VERSION "2021.24.4"

NS_ :

BS_:

BU_: VEH CH Receiver X

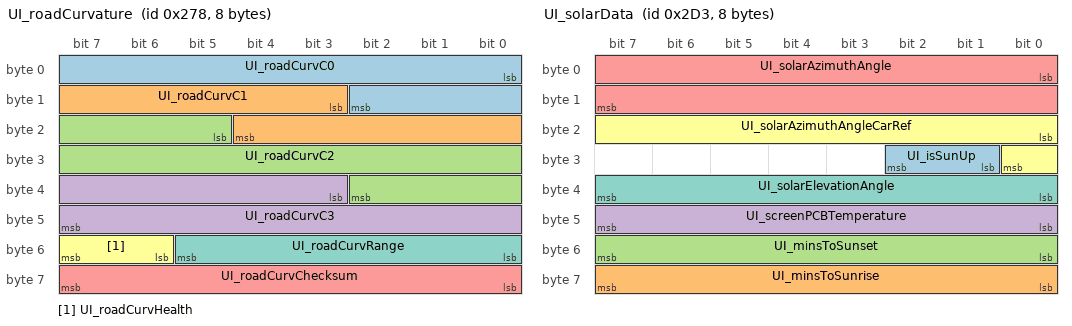
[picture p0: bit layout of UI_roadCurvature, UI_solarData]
BO_ 632 UI_roadCurvature: 8 VEH
 SG_ UI_roadCurvC0: 0|11@1- (0.02,0) [0|0] "m" X
 SG_ UI_roadCurvC1: 11|10@1- (0.00075,0) [0|0] "1" X
 SG_ UI_roadCurvC2: 21|14@1- (7.5e-06,0) [0|0] "1/m" X
 SG_ UI_roadCurvC3: 35|13@1- (3e-08,0) [0|0] "1/m2" X
 SG_ UI_roadCurvChecksum: 56|8@1+ (1,0) [0|0] "" X
 SG_ UI_roadCurvHealth: 54|2@1+ (1,0) [0|0] "" X
 SG_ UI_roadCurvRange: 48|6@1+ (4,0) [0|0] "m" X

BO_ 723 UI_solarData: 8 VEH
 SG_ UI_isSunUp: 25|2@1+ (1,0) [0|0] "" X
 SG_ UI_minsToSunrise: 56|8@1+ (10,0) [0|0] "min" X
 SG_ UI_minsToSunset: 48|8@1+ (10,0) [0|0] "min" X
 SG_ UI_screenPCBTemperature: 40|8@1- (0.5,40) [0|0] "degC" X
 SG_ UI_solarAzimuthAngle: 0|16@1- (1,0) [0|0] "degrees" X
 SG_ UI_solarAzimuthAngleCarRef: 16|9@1- (1,0) [0|0] "degrees" X
 SG_ UI_solarElevationAngle: 32|8@1- (1,0) [0|0] "degrees" X

BO_ 851 UI_status: 8 VehicleBus
 SG_ UI_touchActive : 0|1@1+ (1,0) [0|1] ""  VehicleBus
 SG_ UI_audioActive : 1|1@1+ (1,0) [0|1] ""  VehicleBus
 SG_ UI_bluetoothActive : 2|1@1+ (1,0) [0|1] ""  VehicleBus
 SG_ UI_cellActive : 3|1@1+ (1,0) [0|1] ""  VehicleBus
 SG_ UI_displayReady : 4|1@1+ (1,0) [0|1] ""  VehicleBus
 SG_ UI_displayOn : 5|1@1+ (1,0) [0|1] ""  VehicleBus
 SG_ UI_wifiActive : 6|1@1+ (1,0) [0|1] ""  VehicleBus
 SG_ UI_wifiConnected : 7|1@1+ (1,0) [0|1] ""  VehicleBus
 SG_ UI_systemActive : 8|1@1+ (1,0) [0|1] ""  VehicleBus
 SG_ UI_readyForDrive : 9|1@1+ (1,0) [0|1] ""  VehicleBus
 SG_ UI_cellConnected : 10|1@1+ (1,0) [0|1] ""  VehicleBus
 SG_ UI_vpnActive : 11|1@1+ (1,0) [0|1] ""  VehicleBus
 SG_ UI_autopilotTrial : 12|2@1+ (1,0) [0|3] ""  VehicleBus
 SG_ UI_factoryReset : 14|2@1+ (1,0) [0|3] ""  VehicleBus
 SG_ UI_gpsActive : 16|1@1+ (1,0) [0|1] ""  VehicleBus
 SG_ UI_screenshotActive : 17|1@1+ (1,0) [0|1] ""  VehicleBus
 SG_ UI_radioActive : 18|1@1+ (1,0) [0|1] ""  VehicleBus
 SG_ UI_cellNetworkTechnology : 19|4@1+ (1,0) [0|15] ""  VehicleBus
 SG_ UI_cellReceiverPower : 24|8@1+ (1,-128) [-128|127] "dB"  VehicleBus
 SG_ UI_falseTouchCounter : 32|8@1+ (1,0) [0|255] "1"  VehicleBus
 SG_ UI_developmentCar : 40|1@1+ (1,0) [0|1] ""  VehicleBus
 SG_ UI_cameraActive : 41|1@1+ (1,0) [0|1] ""  VehicleBus
 SG_ UI_cellSignalBars : 42|3@1+ (1,0) [0|7] ""  VehicleBus
 SG_ UI_trailerModeTelltale : 45|2@1+ (1,0) [0|3] ""  VehicleBus
 SG_ UI_pcbTemperature : 48|8@1- (1,40) [-87|167] "degC"  VehicleBus
 SG_ UI_cpuTemperature : 56|8@1- (1,40) [-87|167] "degC"  VehicleBus

BO_ 991 UI_status2: 8 Vector__XXX
 SG_ UI_connectivityStandbyActive : 63|1@1+ (1,0) [0|0] "" Vector__XXX
 SG_ UI_sapClients : 62|1@1+ (1,0) [0|0] "" Vector__XXX
 SG_ UI_sapActive : 61|1@1+ (1,0) [0|0] "" Vector__XXX
 SG_ UI_wakeOnIPActive : 60|1@1+ (1,0) [0|0] "" Vector__XXX
 SG_ UI_sentryModeCameraDetection : 59|1@1+ (1,0) [0|0] "" Vector__XXX
 SG_ UI_fullScreenMode : 58|1@1+ (1,0) [0|0] "" Vector__XXX
 SG_ UI_summonDeviceIndex : 56|2@1+ (1,0) [0|0] "" Vector__XXX
 SG_ UI_selfParkState : 48|8@1+ (1,0) [0|0] "" Vector__XXX
 SG_ UI_sohHealthStatus : 46|2@1+ (1,0) [0|0] "" Vector__XXX
 SG_ UI_wifiBtModuleType : 43|3@1+ (1,0) [0|0] "" Vector__XXX
 SG_ UI_autoshiftDRState : 40|3@1+ (1,0) [0|0] "" Vector__XXX
 SG_ UI_phoneLeftInCabin : 39|1@1+ (1,0) [0|0] "" Vector__XXX
 SG_ UI_mobileAppConnected : 38|1@1+ (1,0) [0|0] "" Vector__XXX
 SG_ UI_autopilotSentryRequest : 37|1@1+ (1,0) [0|0] "" Vector__XXX
 SG_ UI_sentryModeState : 34|3@1+ (1,0) [0|0] "" Vector__XXX
 SG_ UI_linkState : 32|2@1+ (1,0) [0|0] "" Vector__XXX
 SG_ UI_activeTouchPoints : 24|8@1+ (1,0) [0|0] "" Vector__XXX
 SG_ UI_userActivity : 23|1@1+ (1,0) [0|0] "" Vector__XXX
 SG_ UI_displayInDarkMode : 22|1@1+ (1,0) [0|0] "" Vector__XXX
 SG_ UI_locatedAtFavorite : 21|1@1+ (1,0) [0|0] "" Vector__XXX
 SG_ UI_locatedAtWork : 20|1@1+ (1,0) [0|0] "" Vector__XXX
 SG_ UI_locatedAtHome : 19|1@1+ (1,0) [0|0] "" Vector__XXX
 SG_ UI_validDeviceForEUSummon : 18|1@1+ (1,0) [0|0] "" Vector__XXX
 SG_ UI_touchDetected : 17|1@1+ (1,0) [0|0] "" Vector__XXX
 SG_ UI_userRequestSnapshot : 16|1@1+ (1,0) [0|0] "" Vector__XXX
 SG_ UI_mobileAppStepCount : 0|16@1+ (1,0) [0|0] "" Vector__XXX

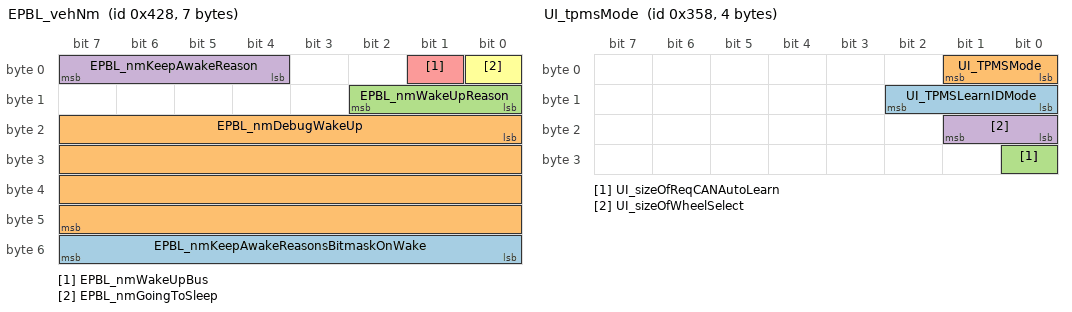
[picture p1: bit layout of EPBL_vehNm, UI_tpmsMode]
BO_ 1064 EPBL_vehNm: 7 Vector__XXX
 SG_ EPBL_nmKeepAwakeReasonsBitmaskOnWake : 48|8@1+ (1,0) [0|0] "" Vector__XXX
 SG_ EPBL_nmDebugWakeUp : 16|32@1+ (1,0) [0|0] "" Vector__XXX
 SG_ EPBL_nmWakeUpReason : 8|3@1+ (1,0) [0|0] "" Vector__XXX
 SG_ EPBL_nmKeepAwakeReason : 4|4@1+ (1,0) [0|0] "" Vector__XXX
 SG_ EPBL_nmWakeUpBus : 1|1@1+ (1,0) [0|0] "" Vector__XXX
 SG_ EPBL_nmGoingToSleep : 0|1@1+ (1,0) [0|0] "" Vector__XXX

BO_ 856 UI_tpmsMode: 4 VEH
 SG_ UI_TPMSLearnIDMode: 8|3@1+ (1,0) [0|0] "" X
 SG_ UI_TPMSMode: 0|2@1+ (1,0) [0|0] "" X
 SG_ UI_sizeOfReqCANAutoLearn: 24|1@1+ (1,0) [0|0] "" X
 SG_ UI_sizeOfWheelSelect: 16|2@1+ (1,0) [0|0] "" X

BO_ 952 UI_tpmsRCPsetting: 4 Vector__XXX
 SG_ UI_setRCPRear : 24|8@1+ (0.025,0) [0|0] "" Vector__XXX
 SG_ UI_setRCPFront : 16|8@1+ (0.025,0) [0|0] "" Vector__XXX

BO_ 627 UI_vehicleControl: 8 VEH
 SG_ UI_accessoryPowerRequest: 0|1@1+ (1,0) [0|0] "" X
 SG_ UI_alarmEnabled: 20|1@1+ (1,0) [0|0] "" X
 SG_ UI_ambientLightingEnabled: 40|1@1+ (1,0) [0|0] "" X
 SG_ UI_autoFoldMirrorsOn: 52|1@1+ (1,0) [0|0] "" X
 SG_ UI_autoHighBeamEnabled: 41|1@1+ (1,0) [0|0] "" X
 SG_ UI_childDoorLockOn: 16|1@1+ (1,0) [0|0] "" X
 SG_ UI_displayBrightnessLevel: 32|8@1+ (0.5,0) [0|0] "%" X
 SG_ UI_domeLightSwitch: 59|2@1+ (1,0) [0|0] "" X
 SG_ UI_driveStateRequest: 62|1@1+ (1,0) [0|0] "" X
 SG_ UI_frontFogSwitch: 3|1@1+ (1,0) [0|0] "" X
 SG_ UI_frontLeftSeatHeatReq: 42|2@1+ (1,0) [0|0] "" X
 SG_ UI_frontRightSeatHeatReq: 44|2@1+ (1,0) [0|0] "" X
 SG_ UI_frunkRequest: 5|1@1+ (1,0) [0|0] "" X
 SG_ UI_globalUnlockOn: 15|1@1+ (1,0) [0|0] "" X
 SG_ UI_honkHorn: 61|1@1+ (1,0) [0|0] "" X
 SG_ UI_intrusionSensorOn: 21|1@1+ (1,0) [0|0] "" X
 SG_ UI_lightSwitch: 1|2@1+ (1,0) [0|0] "" X
 SG_ UI_lockRequest: 17|3@1+ (1,0) [0|0] "" X
 SG_ UI_mirrorDipOnReverse: 53|1@1+ (1,0) [0|0] "" X
 SG_ UI_mirrorFoldRequest: 24|2@1+ (1,0) [0|0] "" X
 SG_ UI_mirrorHeatRequest: 26|1@1+ (1,0) [0|0] "" X
 SG_ UI_powerOff: 31|1@1+ (1,0) [0|0] "" X
 SG_ UI_rearCenterSeatHeatReq: 48|2@1+ (1,0) [0|0] "" X
 SG_ UI_rearFogSwitch: 23|1@1+ (1,0) [0|0] "" X
 SG_ UI_rearLeftSeatHeatReq: 46|2@1+ (1,0) [0|0] "" X
 SG_ UI_rearRightSeatHeatReq: 50|2@1+ (1,0) [0|0] "" X
 SG_ UI_rearWindowLockout: 63|1@1+ (1,0) [0|0] "" X
 SG_ UI_remoteClosureRequest: 54|2@1+ (1,0) [0|0] "" X
 SG_ UI_remoteStartRequest: 27|3@1+ (1,0) [0|0] "" X
 SG_ UI_seeYouHomeLightingOn: 30|1@1+ (1,0) [0|0] "" X
 SG_ UI_steeringBacklightEnabled: 8|1@1+ (1,0) [0|0] "" X
 SG_ UI_steeringButtonMode: 9|3@1+ (1,0) [0|0] "" X
 SG_ UI_stop12vSupport: 22|1@1+ (1,0) [0|0] "" X
 SG_ UI_summonActive: 4|1@1+ (1,0) [0|0] "" X
 SG_ UI_unlockOnPark: 14|1@1+ (1,0) [0|0] "" X
 SG_ UI_walkAwayLock: 13|1@1+ (1,0) [0|0] "" X
 SG_ UI_walkUpUnlock: 12|1@1+ (1,0) [0|0] "" X
 SG_ UI_wiperMode: 6|2@1+ (1,0) [0|0] "" X
 SG_ UI_wiperRequest: 56|3@1+ (1,0) [0|0] "" X

BO_ 947 UI_vehicleControl2: 8 Vector__XXX
 SG_ UI_sleepFeature2 : 63|1@1+ (1,0) [0|0] "" Vector__XXX
 SG_ UI_silentAlarm : 61|1@1+ (1,0) [0|0] "" Vector__XXX
 SG_ UI_saveTireConfigReq : 60|1@1+ (1,0) [0|0] "" Vector__XXX
 SG_ UI_tireSeason : 59|1@1+ (1,0) [0|0] "" Vector__XXX
 SG_ UI_wiperHeaterReq : 57|1@1+ (1,0) [0|0] "" Vector__XXX
 SG_ UI_frontLeftSeatAutoClimateReq : 56|1@1+ (1,0) [0|0] "" Vector__XXX
 SG_ UI_dcr12VThreshold : 52|4@1+ (1,0) [0|0] "" Vector__XXX
 SG_ UI_sleepFeature1 : 51|1@1+ (1,0) [0|0] "" Vector__XXX
 SG_ UI_frontRightSeatAutoClimateReq : 39|1@1+ (1,0) [0|0] "" Vector__XXX
 SG_ UI_disableHorn : 34|1@1+ (1,0) [0|0] "" Vector__XXX
 SG_ UI_steeringWheelHeatReq : 33|1@1+ (1,0) [0|0] "" Vector__XXX
 SG_ UI_WC3UpdateInhibit : 32|1@1+ (1,0) [0|0] "" Vector__XXX
 SG_ UI_conditionalLoggingEnabledVCSE : 31|1@1+ (1,0) [0|0] "" Vector__XXX
 SG_ UI_virtualPitchSensorOverrideOKF : 30|1@1+ (1,0) [0|0] "" Vector__XXX
 SG_ UI_autoRollWindowsOnLockEnable : 29|1@1+ (1,0) [0|0] "" Vector__XXX
 SG_ UI_shorted12VCellTestMode : 27|2@1+ (1,0) [0|0] "" Vector__XXX
 SG_ UI_autopilotPowerStateRequest : 25|2@1+ (1,0) [0|0] "" Vector__XXX
 SG_ UI_coastDownMode : 24|1@1+ (1,0) [0|0] "" Vector__XXX
 SG_ UI_batteryPreconditioningRequest : 23|1@1+ (1,0) [0|0] "" Vector__XXX
 SG_ UI_keepAutopilotAwake : 22|1@1+ (1,0) [0|0] "" Vector__XXX
 SG_ UI_pairKeyQRCodeDisplaying : 21|1@1+ (1,0) [0|0] "" Vector__XXX
 SG_ UI_BLEPushNotificationRequest : 20|1@1+ (1,0) [0|0] "" Vector__XXX
 SG_ UI_freeRollModeRequest : 19|1@1+ (1,0) [0|0] "" Vector__XXX
 SG_ UI_displayOnForUser : 18|1@1+ (1,0) [0|0] "" Vector__XXX
 SG_ UI_summonState : 16|2@1+ (1,0) [0|0] "" Vector__XXX
 SG_ UI_VCLEFTFeature1 : 15|1@1+ (1,0) [0|0] "" Vector__XXX
 SG_ UI_VCSECFeature1 : 14|1@1+ (1,0) [0|0] "" Vector__XXX
 SG_ UI_alarmTriggerRequest : 13|1@1+ (1,0) [0|0] "" Vector__XXX
 SG_ UI_readyToAddKey : 12|1@1+ (1,0) [0|0] "" Vector__XXX
 SG_ UI_lightSwitch : 9|3@1+ (1,0) [0|0] "" Vector__XXX
 SG_ UI_disableMirrorAutoDim : 8|1@1+ (1,0) [0|0] "" Vector__XXX
 SG_ UI_PINToDrivePassed : 7|1@1+ (1,0) [0|0] "" Vector__XXX
 SG_ UI_PINToDriveEnabled : 6|1@1+ (1,0) [0|0] "" Vector__XXX
 SG_ UI_locksPanelActive : 5|1@1+ (1,0) [0|0] "" Vector__XXX
 SG_ UI_soundHornOnLock : 4|1@1+ (1,0) [0|0] "" Vector__XXX
 SG_ UI_WCUpdateInhibit : 3|1@1+ (1,0) [0|0] "" Vector__XXX
 SG_ UI_UMCUpdateInhibit : 2|1@1+ (1,0) [0|0] "" Vector__XXX
 SG_ UI_trunkRequest : 1|1@1+ (1,0) [0|0] "" Vector__XXX
 SG_ UI_gloveboxRequest : 0|1@1+ (1,0) [0|0] "" Vector__XXX

BO_ 644 UI_vehicleModes: 8 Vector__XXX
 SG_ UI_vehicleModesChecksum : 56|8@1+ (1,0) [0|0] "" Vector__XXX
 SG_ UI_vehicleModesCounter : 52|4@1+ (1,0) [0|0] "" Vector__XXX
 SG_ UI_upkeepMode : 46|1@1+ (1,0) [0|0] "" Vector__XXX
 SG_ UI_sohTestRequest : 45|1@1+ (1,0) [0|0] "" Vector__XXX
 SG_ UI_lightShowType : 42|3@1+ (1,0) [0|0] "" Vector__XXX
 SG_ UI_closureEasterEggStatus : 40|2@1+ (1,0) [0|0] "" Vector__XXX
 SG_ UI_signedCmdServiceMode : 39|1@1+ (1,0) [0|0] "" Vector__XXX
 SG_ UI_signedCmdHardLocked : 38|1@1+ (1,0) [0|0] "" Vector__XXX
 SG_ UI_premiumAmpPowerOff : 37|1@1+ (1,0) [0|0] "" Vector__XXX
 SG_ UI_serviceModePlus : 36|1@1+ (1,0) [0|0] "" Vector__XXX
 SG_ UI_diagnosticsAllowed : 35|1@1+ (1,0) [0|0] "" Vector__XXX
 SG_ UI_gameMode : 34|1@1+ (1,0) [0|0] "" Vector__XXX
 SG_ UI_valetMode : 33|1@1+ (1,0) [0|0] "" Vector__XXX
 SG_ UI_carWashMode : 32|1@1+ (1,0) [0|0] "" Vector__XXX
 SG_ UI_homelinkV2Command2 : 24|8@1+ (1,0) [0|0] "" Vector__XXX
 SG_ UI_homelinkV2Command1 : 16|8@1+ (1,0) [0|0] "" Vector__XXX
 SG_ UI_homelinkV2Command0 : 8|8@1+ (1,0) [0|0] "" Vector__XXX
 SG_ UI_hasEverBeenDelivered : 5|1@1+ (1,0) [0|0] "" Vector__XXX
 SG_ UI_isDelivered : 4|1@1+ (1,0) [0|0] "" Vector__XXX
 SG_ UI_serviceMode : 3|1@1+ (1,0) [0|0] "" Vector__XXX
 SG_ UI_showroomMode : 2|1@1+ (1,0) [0|0] "" Vector__XXX
 SG_ UI_transportMode : 1|1@1+ (1,0) [0|0] "" Vector__XXX
 SG_ UI_factoryMode : 0|1@1+ (1,0) [0|0] "" Vector__XXX

BO_ 595 UI_ventPanelControlRequest: 8 Vector__XXX
 SG_ UI_hvacReqActiveVents m0 : 60|2@1+ (1,0) [0|0] "" Vector__XXX
 SG_ UI_ventPanelRightLateralMode m0 : 58|2@1+ (1,0) [0|0] "" Vector__XXX
 SG_ UI_ventPanelLeftLateralMode m0 : 56|2@1+ (1,0) [0|0] "" Vector__XXX
 SG_ UI_ventPanelRightLateralSplit m0 : 48|8@1+ (0.5,0) [0|0] "" Vector__XXX
 SG_ UI_ventPanelRightPositionY m0 : 40|8@1+ (0.5,0) [0|0] "" Vector__XXX
 SG_ UI_ventPanelRightPositionX m0 : 32|8@1+ (0.5,0) [0|0] "" Vector__XXX
 SG_ UI_ventPanelLeftLateralSplit m0 : 24|8@1+ (0.5,0) [0|0] "" Vector__XXX
 SG_ UI_ventPanelLeftPositionY m0 : 16|8@1+ (0.5,0) [0|0] "" Vector__XXX
 SG_ UI_ventPanelLeftPositionX m0 : 8|8@1+ (0.5,0) [0|0] "" Vector__XXX
 SG_ UI_ventPanelControlRequestIndex M : 0|1@1+ (1,0) [0|0] "" Vector__XXX

BO_ 824 UMC_alertMatrix1: 8 VEH
 SG_ UMC_a001_gndMonIntrptLineSide: 0|1@1+ (1,0) [0|0] "" X
 SG_ UMC_a002_GFCITripped: 1|1@1+ (1,0) [0|0] "" X
 SG_ UMC_a003_GFCISelfTestFault: 2|1@1+ (1,0) [0|0] "" X
 SG_ UMC_a004_inputOverVoltage: 3|1@1+ (1,0) [0|0] "" X
 SG_ UMC_a005_inputUnderVoltage: 4|1@1+ (1,0) [0|0] "" X
 SG_ UMC_a006_contactorWelded: 5|1@1+ (1,0) [0|0] "" X
 SG_ UMC_a007_pcbaOT: 6|1@1+ (1,0) [0|0] "" X
 SG_ UMC_a008_wallPlugOT: 7|1@1+ (1,0) [0|0] "" X
 SG_ UMC_a009_vehConnOT: 8|1@1+ (1,0) [0|0] "" X
 SG_ UMC_a010_inputOT: 9|1@1+ (1,0) [0|0] "" X
 SG_ UMC_a011_proxDisconnected: 10|1@1+ (1,0) [0|0] "" X
 SG_ UMC_a012_pilotFault: 11|1@1+ (1,0) [0|0] "" X
 SG_ UMC_a013_SA_Temperature: 12|1@1+ (1,0) [0|0] "" X
 SG_ UMC_a014_SA_Genealogy: 13|1@1+ (1,0) [0|0] "" X
 SG_ UMC_a015_SA_Connection: 14|1@1+ (1,0) [0|0] "" X
 SG_ UMC_a016_pcbaOTFoldback: 15|1@1+ (1,0) [0|0] "" X
 SG_ UMC_a017_wallPlugOTFoldback: 16|1@1+ (1,0) [0|0] "" X
 SG_ UMC_a018_vehConnOTFoldback: 17|1@1+ (1,0) [0|0] "" X
 SG_ UMC_a019_inputOTFoldback: 18|1@1+ (1,0) [0|0] "" X
 SG_ UMC_a020_applicationCRC: 19|1@1+ (1,0) [0|0] "" X
 SG_ UMC_a021_dataBus: 20|1@1+ (1,0) [0|0] "" X
 SG_ UMC_a022_criticalRAM: 21|1@1+ (1,0) [0|0] "" X
 SG_ UMC_a023_adcSelfTest: 22|1@1+ (1,0) [0|0] "" X

BO_ 609 VCFRONT_12VBatteryStatus: 8 Vector__XXX
 SG_ VCFRONT_12VBatteryStatusChecksum : 56|8@1+ (1,0) [0|0] "" Vector__XXX
 SG_ VCFRONT_12VBatteryStatusCounter : 52|4@1+ (1,0) [0|0] "" Vector__XXX
 SG_ VCFRONT_LVBatterySPICommsDetectedDBG m4 : 51|1@1+ (1,0) [0|0] "" Vector__XXX
 SG_ VCFRONT_goodTemp12VforUpdate m1 : 51|1@1+ (1,0) [0|0] "" Vector__XXX
 SG_ VCFRONT_opportunisticDCRTestNeeded m3 : 51|1@1+ (1,0) [0|0] "" Vector__XXX
 SG_ VCFRONT_resistanceEstimationNeeded m2 : 51|1@1+ (1,0) [0|0] "" Vector__XXX
 SG_ VCFRONT_LVBatteryCannotSupportVehicle m1 : 50|1@1+ (1,0) [0|0] "" Vector__XXX
 SG_ VCFRONT_LVBatteryFctryLimOverrideOk m4 : 50|1@1+ (1,0) [0|0] "" Vector__XXX
 SG_ VCFRONT_goodLVChargeForUpdate m3 : 50|1@1+ (1,0) [0|0] "" Vector__XXX
 SG_ VCFRONT_LVBatterySupported m1 : 49|1@1+ (1,0) [0|0] "" Vector__XXX
 SG_ VCFRONT_resistanceEstimationTestsExpended m3 : 49|1@1+ (1,0) [0|0] "" Vector__XXX
 SG_ VCFRONT_LVBatteryType m2 : 48|3@1+ (1,0) [0|0] "" Vector__XXX
 SG_ VCFRONT_resistanceEstimationTestValid m3 : 48|1@1+ (1,0) [0|0] "" Vector__XXX
 SG_ VCFRONT_reverseBatteryFault m1 : 48|1@1+ (1,0) [0|0] "" Vector__XXX
 SG_ VCFRONT_voltageFloorReachedCounter m0 : 48|4@1+ (1,0) [0|0] "" Vector__XXX
 SG_ VCFRONT_LVLoadRequest : 47|1@1+ (1,0) [0|0] "" Vector__XXX
 SG_ VCFRONT_good12VforUpdate : 46|1@1+ (1,0) [0|0] "" Vector__XXX
 SG_ VCFRONT_LVBusControlsFutile m3 : 45|1@1+ (1,0) [0|0] "" Vector__XXX
 SG_ VCFRONT_firstChargePOR m0 : 45|1@1+ (1,0) [0|0] "" Vector__XXX
 SG_ VCFRONT_LVBatteryStatusForDrive m2 : 44|2@1+ (1,0) [0|0] "" Vector__XXX
 SG_ VCFRONT_firstChargeOTA m0 : 44|1@1+ (1,0) [0|0] "" Vector__XXX
 SG_ VCFRONT_LVBusControlMode m4 : 41|4@1+ (1,0) [0|0] "" Vector__XXX
 SG_ VCFRONT_goodForPCSPowerCycleLeakyBktDBG m3 : 40|5@1+ (0.0005,0) [0|0] "" Vector__XXX
 SG_ VCFRONT_LVBatteryEnergyRemainingPCT m2 : 37|7@1+ (1,0) [0|0] "" Vector__XXX
 SG_ VCFRONT_voltageSensorMismatchLeakyBktPctDBG m4 : 34|7@1+ (2,0) [0|0] "" Vector__XXX
 SG_ VCFRONT_LVBatteryLINCommsDetectedDBG m4 : 33|1@1+ (1,0) [0|0] "" Vector__XXX
 SG_ VCFRONT_IBSVoltage m1 : 32|14@1+ (0.005443676098,0) [0|0] "" Vector__XXX
 SG_ VCFRONT_silentWakeIBSCurrent m0 : 32|12@1+ (0.125,-511.875) [0|0] "" Vector__XXX
 SG_ VCFRONT_currentControlLoopIntegrationVal m5 : 30|14@1+ (0.006,0) [0|0] "" Vector__XXX
 SG_ VCFRONT_currentSensorMismatchLeakyBktPctDBG m2 : 27|7@1+ (2,0) [0|0] "" Vector__XXX
 SG_ VCFRONT_LVBatterySupportRqrdTrigger m3 : 24|14@1+ (1,0) [0|0] "" Vector__XXX
 SG_ VCFRONT_IBSVoltageRawDBG m4 : 19|14@1+ (0.005443676098,0) [0|0] "" Vector__XXX
 SG_ VCFRONT_LVBMS_LVPackCurrentSourceDBG m3 : 19|2@1+ (1,0) [0|0] "" Vector__XXX
 SG_ VCFRONT_LVBMS_LVBusVoltageSourceDBG m3 : 17|2@1+ (1,0) [0|0] "" Vector__XXX
 SG_ VCFRONT_IBSCurrent m1 : 16|16@1- (0.005,0) [0|0] "" Vector__XXX
 SG_ VCFRONT_IBSCurrentFiltered m0 : 16|16@1- (0.005,0) [0|0] "" Vector__XXX
 SG_ VCFRONT_IBSTemperature m2 : 16|11@1+ (0.1,-24) [0|0] "" Vector__XXX
 SG_ VCFRONT_voltageControlLoopIntegrationVal m5 : 16|14@1+ (0.006,0) [0|0] "" Vector__XXX
 SG_ VCFRONT_chargeNeeded m5 : 15|1@1+ (1,0) [0|0] "" Vector__XXX
 SG_ VCFRONT_PCSMia m5 : 14|1@1+ (1,0) [0|0] "" Vector__XXX
 SG_ VCFRONT_resistanceEstimationTestCounter m1 : 14|2@1+ (1,0) [0|0] "" Vector__XXX
 SG_ VCFRONT_shortedCellFaultCounter m0 : 13|3@1+ (1,0) [0|0] "" Vector__XXX
 SG_ VCFRONT_isVehicleSupported m0 : 12|1@1+ (1,0) [0|0] "" Vector__XXX
 SG_ VCFRONT_batteryLINScheduleDBG m1 : 11|3@1+ (1,0) [0|0] "" Vector__XXX
 SG_ VCFRONT_eFuseRecoveryStateDBG m1 : 8|3@1+ (1,0) [0|0] "" Vector__XXX
 SG_ VCFRONT_voltageDropCounter m0 : 8|4@1+ (1,0) [0|0] "" Vector__XXX
 SG_ VCFRONT_IBSAmpHours m4 : 5|14@1- (0.005,0) [0|0] "" Vector__XXX
 SG_ VCFRONT_12VOverchargeCounter m0 : 4|4@1+ (1,0) [0|0] "" Vector__XXX
 SG_ VCFRONT_batterySMState m1 : 4|4@1+ (1,0) [0|0] "" Vector__XXX
 SG_ VCFRONT_12VBatteryTargetVoltage m2 : 3|13@1+ (0.01,0) [0|0] "" Vector__XXX
 SG_ VCFRONT_IBSFault m0 : 3|1@1+ (1,0) [0|0] "" Vector__XXX
 SG_ VCFRONT_IBSVoltageFiltered m3 : 3|14@1+ (0.005443676098,0) [0|0] "" Vector__XXX
 SG_ VCFRONT_batterySupportRequest m1 : 3|1@1+ (1,0) [0|0] "" Vector__XXX
 SG_ VCFRONT_targetCurrent m5 : 3|11@1+ (0.125,-127) [0|0] "" Vector__XXX
 SG_ VCFRONT_voltageProfile m4 : 3|2@1+ (1,0) [0|0] "" Vector__XXX
 SG_ VCFRONT_12VBatteryStatusIndex M : 0|3@1+ (1,0) [0|0] "" Vector__XXX

BO_ 545 VCFRONT_LVPowerState: 8 VEH
 SG_ VCFRONT_LVPowerStateChecksum: 56|8@1+ (1,0) [0|0] "" X
 SG_ VCFRONT_LVPowerStateCounter: 52|4@1+ (1,0) [0|0] "" X
 SG_ VCFRONT_LVPowerStateIndex M: 0|5@1+ (1,0) [0|0] "" X
 SG_ VCFRONT_vehiclePowerState: 5|2@1+ (1,0) [0|0] "" X
 SG_ VCFRONT_parkLVState m0: 8|2@1+ (1,0) [0|0] "" X
 SG_ VCFRONT_espLVState m0: 10|2@1+ (1,0) [0|0] "" X
 SG_ VCFRONT_radcLVState m0: 12|2@1+ (1,0) [0|0] "" X
 SG_ VCFRONT_hvacCompLVState m0: 14|2@1+ (1,0) [0|0] "" X
 SG_ VCFRONT_ptcLVRequest m0: 16|2@1+ (1,0) [0|0] "" X
 SG_ VCFRONT_sccmLVRequest m0: 18|2@1+ (1,0) [0|0] "" X
 SG_ VCFRONT_tpmsLVRequest m0: 20|2@1+ (1,0) [0|0] "" X
 SG_ VCFRONT_rcmLVRequest m0: 22|2@1+ (1,0) [0|0] "" X
 SG_ VCFRONT_iBoosterLVState m0: 24|2@1+ (1,0) [0|0] "" X
 SG_ VCFRONT_tunerLVRequest m0: 26|2@1+ (1,0) [0|0] "" X
 SG_ VCFRONT_amplifierLVRequest m0: 28|2@1+ (1,0) [0|0] "" X
 SG_ VCFRONT_das1HighCurrentLVState m0: 30|2@1+ (1,0) [0|0] "" X
 SG_ VCFRONT_das2HighCurrentLVState m0: 32|2@1+ (1,0) [0|0] "" X
 SG_ VCFRONT_diLVRequest m0: 34|2@1+ (1,0) [0|0] "" X
 SG_ VCFRONT_disLVState m0: 36|2@1+ (1,0) [0|0] "" X
 SG_ VCFRONT_oilPumpFrontLVState m0: 38|2@1+ (1,0) [0|0] "" X
 SG_ VCFRONT_oilPumpRearLVRequest m0: 40|2@1+ (1,0) [0|0] "" X
 SG_ VCFRONT_ocsLVRequest m0: 42|2@1+ (1,0) [0|0] "" X
 SG_ VCFRONT_vcleftHiCurrentLVState m0: 44|2@1+ (1,0) [0|0] "" X
 SG_ VCFRONT_vcrightHiCurrentLVState m0: 46|2@1+ (1,0) [0|0] "" X
 SG_ VCFRONT_uiHiCurrentLVState m0: 48|2@1+ (1,0) [0|0] "" X
 SG_ VCFRONT_uiAudioLVState m0: 50|2@1+ (1,0) [0|0] "" X
 SG_ VCFRONT_cpLVRequest m1: 8|2@1+ (1,0) [0|0] "" X
 SG_ VCFRONT_epasLVState m1: 10|2@1+ (1,0) [0|0] "" X
 SG_ VCFRONT_hvcLVRequest m1: 12|2@1+ (1,0) [0|0] "" X
 SG_ VCFRONT_tasLVState m1: 14|2@1+ (1,0) [0|0] "" X
 SG_ VCFRONT_pcsLVState m1: 16|2@1+ (1,0) [0|0] "" X

BO_ 832 VCFRONT_alertMatrix: 8 VEH
 SG_ VCFRONT_matrixIndex M: 0|4@1+ (1,0) [0|0] "" X
 SG_ VCFRONT_a001_WatchdogReset m0: 4|1@1+ (1,0) [0|0] "" X
 SG_ VCFRONT_a002_PowerLossReset m0: 5|1@1+ (1,0) [0|0] "" X
 SG_ VCFRONT_a003_SWAssertion m0: 6|1@1+ (1,0) [0|0] "" X
 SG_ VCFRONT_a010_ExtSupplyVoltError m0: 13|1@1+ (1,0) [0|0] "" X
 SG_ VCFRONT_a012_CPUReset m0: 15|1@1+ (1,0) [0|0] "" X
 SG_ VCFRONT_a013_AlertManagerFault m0: 16|1@1+ (1,0) [0|0] "" X
 SG_ VCFRONT_a015_NVMMAlert m0: 18|1@1+ (1,0) [0|0] "" X
 SG_ VCFRONT_a021_TaskSchedulerError m0: 24|1@1+ (1,0) [0|0] "" X
 SG_ VCFRONT_a022_TaskInitError m0: 25|1@1+ (1,0) [0|0] "" X
 SG_ VCFRONT_a031_UDSActive m0: 34|1@1+ (1,0) [0|0] "" X
 SG_ VCFRONT_a041_HighCPULoad m0: 44|1@1+ (1,0) [0|0] "" X
 SG_ VCFRONT_a042_HighStackUsage m0: 45|1@1+ (1,0) [0|0] "" X
 SG_ VCFRONT_a043_Task1msError m0: 46|1@1+ (1,0) [0|0] "" X
 SG_ VCFRONT_a044_Task10msError m0: 47|1@1+ (1,0) [0|0] "" X
 SG_ VCFRONT_a045_Task100msError m0: 48|1@1+ (1,0) [0|0] "" X
 SG_ VCFRONT_a046_Task1000msError m0: 49|1@1+ (1,0) [0|0] "" X
 SG_ VCFRONT_a059_inputResistanceHigh m0: 62|1@1+ (1,0) [0|0] "" X
 SG_ VCFRONT_a060_engineeringBuild m0: 63|1@1+ (1,0) [0|0] "" X
 SG_ VCFRONT_a061_XCPConnected m1: 4|1@1+ (1,0) [0|0] "" X
 SG_ VCFRONT_a062_XCPWasConnected m1: 5|1@1+ (1,0) [0|0] "" X
 SG_ VCFRONT_a063_SwitchFault m1: 6|1@1+ (1,0) [0|0] "" X
 SG_ VCFRONT_a064_busSleepReqTimeout m1: 7|1@1+ (1,0) [0|0] "" X
 SG_ VCFRONT_a097_CMP_MIA m1: 40|1@1+ (1,0) [0|0] "" X
 SG_ VCFRONT_a098_DI_THERMAL_MIA m1: 41|1@1+ (1,0) [0|0] "" X
 SG_ VCFRONT_a099_PARK_MIA m1: 42|1@1+ (1,0) [0|0] "" X
 SG_ VCFRONT_a100_CANbus_MIA m1: 43|1@1+ (1,0) [0|0] "" X
 SG_ VCFRONT_a101_PM_MIA m1: 44|1@1+ (1,0) [0|0] "" X
 SG_ VCFRONT_a102_PTC_MIA m1: 45|1@1+ (1,0) [0|0] "" X
 SG_ VCFRONT_a103_CP_MIA m1: 46|1@1+ (1,0) [0|0] "" X
 SG_ VCFRONT_a104_DAS_MIA m1: 47|1@1+ (1,0) [0|0] "" X
 SG_ VCFRONT_a105_TAS_MIA m1: 48|1@1+ (1,0) [0|0] "" X
 SG_ VCFRONT_a106_PCS_MIA m1: 49|1@1+ (1,0) [0|0] "" X
 SG_ VCFRONT_a107_BMS_MIA m1: 50|1@1+ (1,0) [0|0] "" X
 SG_ VCFRONT_a108_DIS_MIA m1: 51|1@1+ (1,0) [0|0] "" X
 SG_ VCFRONT_a109_RCM_MIA m1: 52|1@1+ (1,0) [0|0] "" X
 SG_ VCFRONT_a110_GTW_MIA m1: 53|1@1+ (1,0) [0|0] "" X
 SG_ VCFRONT_a111_EPBR_MIA m1: 54|1@1+ (1,0) [0|0] "" X
 SG_ VCFRONT_a112_EPBL_MIA m1: 55|1@1+ (1,0) [0|0] "" X
 SG_ VCFRONT_a113_UI_MIA m1: 56|1@1+ (1,0) [0|0] "" X
 SG_ VCFRONT_a114_ESP_MIA m1: 57|1@1+ (1,0) [0|0] "" X
 SG_ VCFRONT_a115_VCSEC_MIA m1: 58|1@1+ (1,0) [0|0] "" X
 SG_ VCFRONT_a116_VCRIGHT_MIA m1: 59|1@1+ (1,0) [0|0] "" X
 SG_ VCFRONT_a117_VCLEFT_MIA m1: 60|1@1+ (1,0) [0|0] "" X
 SG_ VCFRONT_a118_VCFRONT_MIA m1: 61|1@1+ (1,0) [0|0] "" X
 SG_ VCFRONT_a119_SCCM_MIA m1: 62|1@1+ (1,0) [0|0] "" X
 SG_ VCFRONT_a120_DI_DRIVE_MIA m1: 63|1@1+ (1,0) [0|0] "" X
 SG_ VCFRONT_a121_pumpBatICLatchFault m2: 4|1@1+ (1,0) [0|0] "" X
 SG_ VCFRONT_a122_pumpBatICWarning m2: 5|1@1+ (1,0) [0|0] "" X
 SG_ VCFRONT_a123_pumpPtICLatchFault m2: 6|1@1+ (1,0) [0|0] "" X
 SG_ VCFRONT_a124_pumpPtICWarning m2: 7|1@1+ (1,0) [0|0] "" X
 SG_ VCFRONT_a125_thmlFanICLatchFault m2: 8|1@1+ (1,0) [0|0] "" X
 SG_ VCFRONT_a126_thmlFanICWarning m2: 9|1@1+ (1,0) [0|0] "" X
 SG_ VCFRONT_a127_vcleftEFuseTrip m2: 10|1@1+ (1,0) [0|0] "" X
 SG_ VCFRONT_a128_vcrightEFuseTrip m2: 11|1@1+ (1,0) [0|0] "" X
 SG_ VCFRONT_a129_pcsEFuseTrip m2: 12|1@1+ (1,0) [0|0] "" X
 SG_ VCFRONT_a130_epas3pEFuseTrip m2: 13|1@1+ (1,0) [0|0] "" X
 SG_ VCFRONT_a131_epas3sEFuseTrip m2: 14|1@1+ (1,0) [0|0] "" X
 SG_ VCFRONT_a132_iBoosterEFuseTrip m2: 15|1@1+ (1,0) [0|0] "" X
 SG_ VCFRONT_a133_espEFuseTrip m2: 16|1@1+ (1,0) [0|0] "" X
 SG_ VCFRONT_a134_fusedHighEFuseTrip m2: 17|1@1+ (1,0) [0|0] "" X
 SG_ VCFRONT_a135_coolantLevelLow m2: 18|1@1+ (1,0) [0|0] "" X
 SG_ VCFRONT_a136_refrigDischTempSns m2: 19|1@1+ (1,0) [0|0] "" X
 SG_ VCFRONT_a137_refrigDischPresSns m2: 20|1@1+ (1,0) [0|0] "" X
 SG_ VCFRONT_a138_refrigSuctTempSns m2: 21|1@1+ (1,0) [0|0] "" X
 SG_ VCFRONT_a139_refrigSuctPresSns m2: 22|1@1+ (1,0) [0|0] "" X
 SG_ VCFRONT_a140_coolantTempPtSns m2: 23|1@1+ (1,0) [0|0] "" X
 SG_ VCFRONT_a141_coolantTempBatSns m2: 24|1@1+ (1,0) [0|0] "" X
 SG_ VCFRONT_a142_exvMotorFault m2: 25|1@1+ (1,0) [0|0] "" X
 SG_ VCFRONT_a143_pumpBatICTransFault m2: 26|1@1+ (1,0) [0|0] "" X
 SG_ VCFRONT_a144_pumpPtICTransFault m2: 27|1@1+ (1,0) [0|0] "" X
 SG_ VCFRONT_a145_thmlFanICTransFault m2: 28|1@1+ (1,0) [0|0] "" X
 SG_ VCFRONT_a146_pumpBatSoftStall m2: 29|1@1+ (1,0) [0|0] "" X
 SG_ VCFRONT_a147_pumpPtSoftStall m2: 30|1@1+ (1,0) [0|0] "" X
 SG_ VCFRONT_a148_thmlFanSoftStall m2: 31|1@1+ (1,0) [0|0] "" X
 SG_ VCFRONT_a149_BLEFrontPowerCycled m2: 32|1@1+ (1,0) [0|0] "" X
 SG_ VCFRONT_a150_pumpBatLowRPMCBang m2: 33|1@1+ (1,0) [0|0] "" X
 SG_ VCFRONT_a151_pumpPtLowRPMCBang m2: 34|1@1+ (1,0) [0|0] "" X
 SG_ VCFRONT_a152_thmlFanLowRPMCBang m2: 35|1@1+ (1,0) [0|0] "" X
 SG_ VCFRONT_a156_louverBlockage m2: 39|1@1+ (1,0) [0|0] "" X
 SG_ VCFRONT_a157_louverBreakage m2: 40|1@1+ (1,0) [0|0] "" X
 SG_ VCFRONT_a158_louverDisconnected m2: 41|1@1+ (1,0) [0|0] "" X
 SG_ VCFRONT_a159_fiveWayValveFault m2: 42|1@1+ (1,0) [0|0] "" X
 SG_ VCFRONT_a160_compressorInhibited m2: 43|1@1+ (1,0) [0|0] "" X
 SG_ VCFRONT_a161_compressorSelfFault m2: 44|1@1+ (1,0) [0|0] "" X
 SG_ VCFRONT_a164_eFuseLckoutMissing m2: 47|1@1+ (1,0) [0|0] "" X
 SG_ VCFRONT_a165_unxpctdEFuseLckout m2: 48|1@1+ (1,0) [0|0] "" X
 SG_ VCFRONT_a166_rightHCMMIA m2: 49|1@1+ (1,0) [0|0] "" X
 SG_ VCFRONT_a167_leftHCMMIA m2: 50|1@1+ (1,0) [0|0] "" X
 SG_ VCFRONT_a168_hcmShortToVBAT m2: 51|1@1+ (1,0) [0|0] "" X
 SG_ VCFRONT_a169_hcmPhaseEnableFail m2: 52|1@1+ (1,0) [0|0] "" X
 SG_ VCFRONT_a170_hcmUnderVoltage m2: 53|1@1+ (1,0) [0|0] "" X
 SG_ VCFRONT_a171_driveBlckdByMsmtch m2: 54|1@1+ (1,0) [0|0] "" X
 SG_ VCFRONT_a172_wsteHtBlckdByMsmtch m2: 55|1@1+ (1,0) [0|0] "" X
 SG_ VCFRONT_a173_HVBlckdByMsmtch m2: 56|1@1+ (1,0) [0|0] "" X
 SG_ VCFRONT_a174_driveNotAuthed m2: 57|1@1+ (1,0) [0|0] "" X
 SG_ VCFRONT_a175_ambientTempSns m2: 58|1@1+ (1,0) [0|0] "" X
 SG_ VCFRONT_a176_vehicleInSelfTest m2: 59|1@1+ (1,0) [0|0] "" X
 SG_ VCFRONT_a177_mcuAudioEFuseFault m2: 60|1@1+ (1,0) [0|0] "" X
 SG_ VCFRONT_a179_highLVAmpsIntoPCS m2: 62|1@1+ (1,0) [0|0] "" X
 SG_ VCFRONT_a180_12VNotSupported m2: 63|1@1+ (1,0) [0|0] "" X
 SG_ VCFRONT_a182_replace12VBattery m3: 5|1@1+ (1,0) [0|0] "" X
 SG_ VCFRONT_a183_low12VCapacity m3: 6|1@1+ (1,0) [0|0] "" X
 SG_ VCFRONT_a185_washerFluidLow m3: 8|1@1+ (1,0) [0|0] "" X
 SG_ VCFRONT_a186_noDriveChgCableCon m3: 9|1@1+ (1,0) [0|0] "" X
 SG_ VCFRONT_a187_busesNotSleeping m3: 10|1@1+ (1,0) [0|0] "" X
 SG_ VCFRONT_a188_sleepFailed m3: 11|1@1+ (1,0) [0|0] "" X
 SG_ VCFRONT_a189_IBSMIA m3: 12|1@1+ (1,0) [0|0] "" X
 SG_ VCFRONT_a190_DCDCNotOperational m3: 13|1@1+ (1,0) [0|0] "" X
 SG_ VCFRONT_a191_exitDriveLow12V m3: 14|1@1+ (1,0) [0|0] "" X
 SG_ VCFRONT_a192_criticalLoadShed m3: 15|1@1+ (1,0) [0|0] "" X
 SG_ VCFRONT_a193_mcuAudioRetry m3: 16|1@1+ (1,0) [0|0] "" X
 SG_ VCFRONT_a194_iBoosterRetry m3: 17|1@1+ (1,0) [0|0] "" X
 SG_ VCFRONT_a195_drveBlckdVltgeTooHgh m3: 18|1@1+ (1,0) [0|0] "" X
 SG_ VCFRONT_a196_discnctd12VBattery m3: 19|1@1+ (1,0) [0|0] "" X
 SG_ VCFRONT_a198_PRVCANOverterminate m3: 21|1@1+ (1,0) [0|0] "" X
 SG_ VCFRONT_a199_PRVCANUndertrminate m3: 22|1@1+ (1,0) [0|0] "" X
 SG_ VCFRONT_a200_vcleftSelfTestFail m3: 23|1@1+ (1,0) [0|0] "" X
 SG_ VCFRONT_a201_vcrightSelfTestFail m3: 24|1@1+ (1,0) [0|0] "" X
 SG_ VCFRONT_a202_pcsSelfTestFail m3: 25|1@1+ (1,0) [0|0] "" X
 SG_ VCFRONT_a203_epas3pSelfTestFail m3: 26|1@1+ (1,0) [0|0] "" X
 SG_ VCFRONT_a204_epas3sSelfTestFail m3: 27|1@1+ (1,0) [0|0] "" X
 SG_ VCFRONT_a205_iBoosterSelfTestFail m3: 28|1@1+ (1,0) [0|0] "" X
 SG_ VCFRONT_a206_espSelfTestFail m3: 29|1@1+ (1,0) [0|0] "" X
 SG_ VCFRONT_a207_vbatFusdSelfTestFail m3: 30|1@1+ (1,0) [0|0] "" X
 SG_ VCFRONT_a208_brakeFluidLow m3: 31|1@1+ (1,0) [0|0] "" X
 SG_ VCFRONT_a209_brakeFluidSNA m3: 32|1@1+ (1,0) [0|0] "" X
 SG_ VCFRONT_a210_fiveWayValveCalib m3: 33|1@1+ (1,0) [0|0] "" X
 SG_ VCFRONT_a211_I2CFault m3: 34|1@1+ (1,0) [0|0] "" X
 SG_ VCFRONT_a212_IBSOverTemp m3: 35|1@1+ (1,0) [0|0] "" X
 SG_ VCFRONT_a213_12VOvercharge m3: 36|1@1+ (1,0) [0|0] "" X
 SG_ VCFRONT_a214_airCompUnderCurrent m3: 37|1@1+ (1,0) [0|0] "" X
 SG_ VCFRONT_a215_airCompDriverFault m3: 38|1@1+ (1,0) [0|0] "" X
 SG_ VCFRONT_a219_12VVoltFloorRchd m3: 42|1@1+ (1,0) [0|0] "" X
 SG_ VCFRONT_a220_reverseBatteryFault m3: 43|1@1+ (1,0) [0|0] "" X
 SG_ VCFRONT_a221_leftTurnLightFault m3: 44|1@1+ (1,0) [0|0] "" X
 SG_ VCFRONT_a222_rightTurnLightFault m3: 45|1@1+ (1,0) [0|0] "" X
 SG_ VCFRONT_a223_12VTempSensDiscnect m3: 46|1@1+ (1,0) [0|0] "" X
 SG_ VCFRONT_a224_revBatChrgPmpFault m3: 47|1@1+ (1,0) [0|0] "" X
 SG_ VCFRONT_a225_driveBlckdByShowroom m3: 48|1@1+ (1,0) [0|0] "" X
 SG_ VCFRONT_a226_railAPoweredForFrunk m3: 49|1@1+ (1,0) [0|0] "" X
 SG_ VCFRONT_a228_pumpBatFbkSanity m3: 51|1@1+ (1,0) [0|0] "" X
 SG_ VCFRONT_a229_pumpPtFbkSanity m3: 52|1@1+ (1,0) [0|0] "" X
 SG_ VCFRONT_a230_thmlFanFbkSanity m3: 53|1@1+ (1,0) [0|0] "" X
 SG_ VCFRONT_a231_12VTempSensShort m3: 54|1@1+ (1,0) [0|0] "" X
 SG_ VCFRONT_a233_autopilot1EFuseFault m3: 56|1@1+ (1,0) [0|0] "" X
 SG_ VCFRONT_a234_autopilot2EFuseFault m3: 57|1@1+ (1,0) [0|0] "" X
 SG_ VCFRONT_a235_ptTempSnsIrrational m3: 58|1@1+ (1,0) [0|0] "" X
 SG_ VCFRONT_a236_batTempSnsIrrational m3: 59|1@1+ (1,0) [0|0] "" X
 SG_ VCFRONT_a237_pumpBatChipComms m3: 60|1@1+ (1,0) [0|0] "" X
 SG_ VCFRONT_a238_pumpPtChipComms m3: 61|1@1+ (1,0) [0|0] "" X
 SG_ VCFRONT_a239_thmlFanChipComms m3: 62|1@1+ (1,0) [0|0] "" X
 SG_ VCFRONT_a243_12VOverchargeInstc m4: 6|1@1+ (1,0) [0|0] "" X
 SG_ VCFRONT_a244_sleepBypassFault m4: 7|1@1+ (1,0) [0|0] "" X
 SG_ VCFRONT_a245_pump1EFuseFault m4: 8|1@1+ (1,0) [0|0] "" X
 SG_ VCFRONT_a246_pump2EFuseFault m4: 9|1@1+ (1,0) [0|0] "" X
 SG_ VCFRONT_a247_evapSolenoidFault m4: 10|1@1+ (1,0) [0|0] "" X
 SG_ VCFRONT_a248_voltageOutOfSpec m4: 11|1@1+ (1,0) [0|0] "" X
 SG_ VCFRONT_a249_fiveWayValveBadMode m4: 12|1@1+ (1,0) [0|0] "" X
 SG_ VCFRONT_a250_headlampsNotAimed m4: 13|1@1+ (1,0) [0|0] "" X
 SG_ VCFRONT_a251_UIWakeupTrigger m4: 14|1@1+ (1,0) [0|0] "" X
 SG_ VCFRONT_a252_frontControllerWakeup m4: 15|1@1+ (1,0) [0|0] "" X
 SG_ VCFRONT_a253_maxChrgeSssionTmeout m4: 16|1@1+ (1,0) [0|0] "" X
 SG_ VCFRONT_a254_pumpBatStopped m4: 17|1@1+ (1,0) [0|0] "" X
 SG_ VCFRONT_a255_pumpPtStopped m4: 18|1@1+ (1,0) [0|0] "" X
 SG_ VCFRONT_a256_compTornShaftSeal m4: 19|1@1+ (1,0) [0|0] "" X
 SG_ VCFRONT_a257_portExpanderVOR m4: 20|1@1+ (1,0) [0|0] "" X
 SG_ VCFRONT_a258_resistanceEstimationRun m4: 21|1@1+ (1,0) [0|0] "" X
 SG_ VCFRONT_a259_12vVoltageDropOnHighLoadCurrent m4: 22|1@1+ (1,0) [0|0] "" X

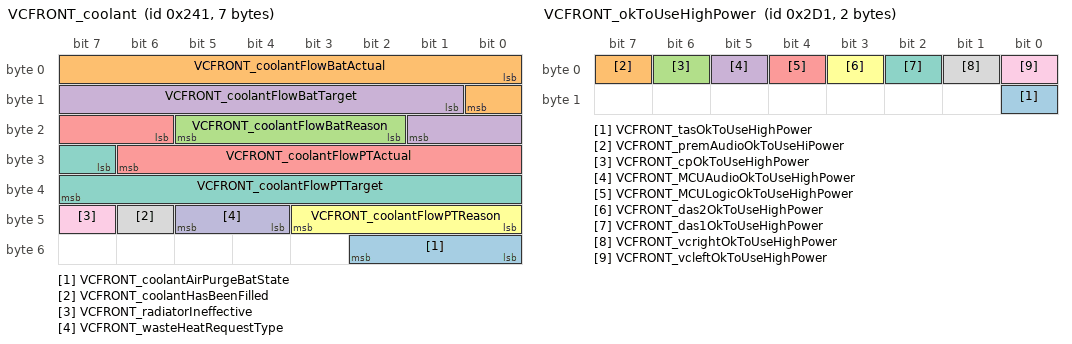
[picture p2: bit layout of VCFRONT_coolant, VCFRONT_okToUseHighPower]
BO_ 577 VCFRONT_coolant: 7 VEH
 SG_ VCFRONT_coolantAirPurgeBatState: 48|3@1+ (1,0) [0|0] "" X
 SG_ VCFRONT_coolantFlowBatActual: 0|9@1+ (0.1,0) [0|0] "LPM" X
 SG_ VCFRONT_coolantFlowBatReason: 18|4@1+ (1,0) [0|0] "" X
 SG_ VCFRONT_coolantFlowBatTarget: 9|9@1+ (0.1,0) [0|0] "LPM" X
 SG_ VCFRONT_coolantFlowPTActual: 22|9@1+ (0.1,0) [0|0] "LPM" X
 SG_ VCFRONT_coolantFlowPTReason: 40|4@1+ (1,0) [0|0] "" X
 SG_ VCFRONT_coolantFlowPTTarget: 31|9@1+ (0.1,0) [0|0] "LPM" X
 SG_ VCFRONT_coolantHasBeenFilled: 46|1@1+ (1,0) [0|0] "" X
 SG_ VCFRONT_radiatorIneffective: 47|1@1+ (1,0) [0|0] "" X
 SG_ VCFRONT_wasteHeatRequestType: 44|2@1+ (1,0) [0|0] "" X

BO_ 753 VCFRONT_eFuseDebugStatus: 8 VEH
 SG_ VCFRONT_eFuseDebugStatusIndex M: 0|5@1+ (1,0) [0|0] "" X
 SG_ VCFRONT_rightControllerState m0: 8|2@1+ (1,0) [0|0] "" X
 SG_ VCFRONT_rightControllerFault m0: 10|1@1+ (1,0) [0|0] "" X
 SG_ VCFRONT_vcrightSelfTestResult m0: 11|4@1+ (1,0) [0|0] "" X
 SG_ VCFRONT_rightControllerTemp m0: 15|11@1+ (0.125,-40) [0|0] "degC" X
 SG_ VCFRONT_rightControllerVoltage m0: 31|16@1+ (0.1,0) [0|0] "V" X
 SG_ VCFRONT_rightControllerCurrent m0: 47|16@1+ (0.1,0) [0|0] "A" X
 SG_ VCFRONT_leftControllerState m1: 8|2@1+ (1,0) [0|0] "" X
 SG_ VCFRONT_leftControllerFault m1: 10|1@1+ (1,0) [0|0] "" X
 SG_ VCFRONT_vcleftSelfTestResult m1: 11|4@1+ (1,0) [0|0] "" X
 SG_ VCFRONT_leftControllerTemp m1: 15|11@1+ (0.125,-40) [0|0] "degC" X
 SG_ VCFRONT_leftControllerVoltage m1: 31|16@1+ (0.1,0) [0|0] "V" X
 SG_ VCFRONT_leftControllerCurrent m1: 47|16@1+ (0.1,0) [0|0] "A" X
 SG_ VCFRONT_PCSState m2: 8|2@1+ (1,0) [0|0] "" X
 SG_ VCFRONT_PCSFault m2: 10|1@1+ (1,0) [0|0] "" X
 SG_ VCFRONT_pcsSelfTestResult m2: 11|4@1+ (1,0) [0|0] "" X
 SG_ VCFRONT_PCSTemp m2: 15|11@1+ (0.125,-40) [0|0] "degC" X
 SG_ VCFRONT_PCSVoltage m2: 31|16@1+ (0.1,0) [0|0] "V" X
 SG_ VCFRONT_PCSCurrent m2: 47|16@1- (0.1,0) [0|0] "A" X
 SG_ VCFRONT_iBoosterState m3: 8|2@1+ (1,0) [0|0] "" X
 SG_ VCFRONT_iBoosterFault m3: 10|1@1+ (1,0) [0|0] "" X
 SG_ VCFRONT_iBoosterSelfTestResult m3: 11|4@1+ (1,0) [0|0] "" X
 SG_ VCFRONT_iBoosterTemp m3: 15|11@1+ (0.125,-40) [0|0] "degC" X
 SG_ VCFRONT_iBoosterVoltage m3: 31|16@1+ (0.1,0) [0|0] "V" X
 SG_ VCFRONT_iBoosterCurrent m3: 47|16@1+ (0.1,0) [0|0] "A" X
 SG_ VCFRONT_EPAS3PState m4: 8|2@1+ (1,0) [0|0] "" X
 SG_ VCFRONT_EPAS3PFault m4: 10|1@1+ (1,0) [0|0] "" X
 SG_ VCFRONT_EPAS3PSelfTestResult m4: 11|4@1+ (1,0) [0|0] "" X
 SG_ VCFRONT_EPAS3PTemp m4: 15|11@1+ (0.125,-40) [0|0] "degC" X
 SG_ VCFRONT_EPAS3PVoltage m4: 31|16@1+ (0.1,0) [0|0] "V" X
 SG_ VCFRONT_EPAS3PCurrent m4: 47|16@1+ (0.1,0) [0|0] "A" X
 SG_ VCFRONT_EPAS3SState m5: 8|2@1+ (1,0) [0|0] "" X
 SG_ VCFRONT_EPAS3SFault m5: 10|1@1+ (1,0) [0|0] "" X
 SG_ VCFRONT_EPAS3SSelfTestResult m5: 11|4@1+ (1,0) [0|0] "" X
 SG_ VCFRONT_EPAS3STemp m5: 15|11@1+ (0.125,-40) [0|0] "degC" X
 SG_ VCFRONT_EPAS3SVoltage m5: 31|16@1+ (0.1,0) [0|0] "V" X
 SG_ VCFRONT_EPAS3SCurrent m5: 47|16@1+ (0.1,0) [0|0] "A" X
 SG_ VCFRONT_ESPMotorState m6: 8|2@1+ (1,0) [0|0] "" X
 SG_ VCFRONT_ESPMotorFault m6: 10|1@1+ (1,0) [0|0] "" X
 SG_ VCFRONT_ESPMotorSelfTestResult m6: 11|4@1+ (1,0) [0|0] "" X
 SG_ VCFRONT_ESPMotorTemp m6: 15|11@1+ (0.125,-40) [0|0] "degC" X
 SG_ VCFRONT_ESPMotorVoltage m6: 31|16@1+ (0.1,0) [0|0] "V" X
 SG_ VCFRONT_ESPMotorCurrent m6: 47|16@1+ (0.1,0) [0|0] "A" X
 SG_ VCFRONT_ESPValveState m7: 8|2@1+ (1,0) [0|0] "" X
 SG_ VCFRONT_ESPValveFault m7: 10|1@1+ (1,0) [0|0] "" X
 SG_ VCFRONT_ESPValveTemp m7: 12|11@1+ (0.125,-40) [0|0] "degC" X
 SG_ VCFRONT_ESPValveVoltage m7: 28|16@1+ (0.1,0) [0|0] "V" X
 SG_ VCFRONT_ESPValveCurrent m7: 44|16@1+ (0.1,0) [0|0] "A" X
 SG_ VCFRONT_autopilot1State m8: 8|2@1+ (1,0) [0|0] "" X
 SG_ VCFRONT_autopilot1Fault m8: 10|1@1+ (1,0) [0|0] "" X
 SG_ VCFRONT_autopilot1Temp m8: 11|11@1+ (0.125,-40) [0|0] "degC" X
 SG_ VCFRONT_autopilot1Voltage m8: 27|16@1+ (0.1,0) [0|0] "V" X
 SG_ VCFRONT_autopilot1Current m8: 43|16@1+ (0.1,0) [0|0] "A" X
 SG_ VCFRONT_autopilot2State m9: 8|2@1+ (1,0) [0|0] "" X
 SG_ VCFRONT_autopilot2Fault m9: 10|1@1+ (1,0) [0|0] "" X
 SG_ VCFRONT_autopilot2Temp m9: 11|11@1+ (0.125,-40) [0|0] "degC" X
 SG_ VCFRONT_autopilot2Voltage m9: 27|16@1+ (0.1,0) [0|0] "V" X
 SG_ VCFRONT_autopilot2Current m9: 43|16@1+ (0.1,0) [0|0] "A" X
 SG_ VCFRONT_sleepBypassState m10: 8|1@1+ (1,0) [0|0] "" X
 SG_ VCFRONT_sleepBypassFault m10: 9|1@1+ (1,0) [0|0] "" X
 SG_ VCFRONT_sleepBypassVoltage m10: 10|16@1+ (0.1,0) [0|0] "V" X
 SG_ VCFRONT_sleepBypassCurrent m10: 26|16@1+ (0.1,0) [0|0] "A" X
 SG_ VCFRONT_uiAudioState m11: 5|1@1+ (1,0) [0|0] "" X
 SG_ VCFRONT_uiAudioFault m11: 6|1@1+ (1,0) [0|0] "" X
 SG_ VCFRONT_uiAudioCurrent m11: 8|16@1+ (0.1,0) [0|0] "A" X
 SG_ VCFRONT_uiState m11: 24|1@1+ (1,0) [0|0] "" X
 SG_ VCFRONT_uiFault m11: 25|1@1+ (1,0) [0|0] "" X
 SG_ VCFRONT_uiCurrent m11: 32|16@1+ (0.1,0) [0|0] "A" X
 SG_ VCFRONT_headlampLeftState m12: 8|1@1+ (1,0) [0|0] "" X
 SG_ VCFRONT_headlampLeftFault m12: 9|1@1+ (1,0) [0|0] "" X
 SG_ VCFRONT_headlampLeftCurrent m12: 10|10@1+ (0.1,0) [0|0] "A" X
 SG_ VCFRONT_headlampLeftVoltage m12: 20|8@1+ (0.1,0) [0|0] "V" X
 SG_ VCFRONT_headlampRightState m12: 28|1@1+ (1,0) [0|0] "" X
 SG_ VCFRONT_headlampRightFault m12: 29|1@1+ (1,0) [0|0] "" X
 SG_ VCFRONT_headlampRightCurrent m12: 30|10@1+ (0.1,0) [0|0] "A" X
 SG_ VCFRONT_headlampRightVoltage m12: 40|8@1+ (0.1,0) [0|0] "V" X
 SG_ VCFRONT_headlampLeftTemperature m12: 48|8@1- (1,-40) [0|0] "degC" X
 SG_ VCFRONT_headlampRightTemperature m12: 56|8@1- (1,-40) [0|0] "degC" X
 SG_ VCFRONT_vbatFusedHighState m13: 8|1@1+ (1,0) [0|0] "" X
 SG_ VCFRONT_vbatFusedHighFault m13: 9|1@1+ (1,0) [0|0] "" X
 SG_ VCFRONT_vbatFusedSelfTestResult m13: 10|4@1+ (1,0) [0|0] "" X
 SG_ VCFRONT_vbatFusedHighTemp m13: 14|11@1+ (0.125,-40) [0|0] "degC" X
 SG_ VCFRONT_vbatFusedHighVoltage m13: 30|16@1+ (0.1,0) [0|0] "V" X
 SG_ VCFRONT_vbatFusedHighCurrent m13: 46|16@1+ (0.1,0) [0|0] "A" X
 SG_ VCFRONT_pump1AndFanState m14: 5|1@1+ (1,0) [0|0] "" X
 SG_ VCFRONT_pump1AndFanCurrent m14: 6|16@1+ (0.1,0) [0|0] "A" X
 SG_ VCFRONT_pump1AndFanVoltage m14: 22|12@1+ (0.1,0) [0|0] "V" X
 SG_ VCFRONT_pump2AndAirCompState m14: 34|1@1+ (1,0) [0|0] "" X
 SG_ VCFRONT_pump2AndAirCompCurrent m14: 35|16@1+ (0.1,0) [0|0] "A" X
 SG_ VCFRONT_pump2AndAirCompVoltage m14: 51|12@1+ (0.1,0) [0|0] "V" X
 SG_ VCFRONT_railA_12v m15: 8|12@1+ (0.00544368,0) [0|0] "V" X
 SG_ VCFRONT_railB_12v m15: 20|12@1+ (0.00544368,0) [0|0] "V" X
 SG_ VCFRONT_railA_5v m15: 32|12@1+ (0.00544368,0) [0|0] "V" X
 SG_ VCFRONT_railB_5v m15: 44|12@1+ (0.00544368,0) [0|0] "V" X
 SG_ VCFRONT_eFuseLockoutVoltage m16: 8|12@1+ (0.00544368,0) [0|0] "V" X
 SG_ VCFRONT_ChargePumpVoltage m16: 24|16@1+ (0.00544368,0) [0|0] "V" X
 SG_ VCFRONT_vbatProt m16: 40|12@1+ (0.00544368,0) [0|0] "V" X

BO_ 769 VCFRONT_info: 8 Vector__XXX
 SG_ VCFRONT_infoComponentId m10 : 48|16@1+ (1,0) [0|0] "" Vector__XXX
 SG_ VCFRONT_infoSubUsageId m11 : 40|16@1+ (1,0) [0|0] "" Vector__XXX
 SG_ VCFRONT_infoBattPumpAppCRC m32 : 32|32@1+ (1,0) [0|0] "" Vector__XXX
 SG_ VCFRONT_infoFanAppCRC m34 : 32|32@1+ (1,0) [0|0] "" Vector__XXX
 SG_ VCFRONT_infoHardwareId m10 : 32|16@1+ (1,0) [0|0] "" Vector__XXX
 SG_ VCFRONT_infoPtPumpAppCRC m33 : 32|32@1+ (1,0) [0|0] "" Vector__XXX
 SG_ VCFRONT_infoSubcomponent10 m37 : 32|32@1+ (1,0) [0|0] "" Vector__XXX
 SG_ VCFRONT_infoSubcomponent11 m38 : 32|32@1+ (1,0) [0|0] "" Vector__XXX
 SG_ VCFRONT_infoSubcomponent12 m39 : 32|32@1+ (1,0) [0|0] "" Vector__XXX
 SG_ VCFRONT_infoSubcomponent13 m40 : 32|32@1+ (1,0) [0|0] "" Vector__XXX
 SG_ VCFRONT_infoSubcomponent14 m41 : 32|32@1+ (1,0) [0|0] "" Vector__XXX
 SG_ VCFRONT_infoSubcomponent3 m24 : 32|32@1+ (1,0) [0|0] "" Vector__XXX
 SG_ VCFRONT_infoSubcomponent8 m35 : 32|32@1+ (1,0) [0|0] "" Vector__XXX
 SG_ VCFRONT_infoSubcomponent9 m36 : 32|32@1+ (1,0) [0|0] "" Vector__XXX
 SG_ VC_infoHCMLAppCRC m16 : 32|32@1+ (1,0) [0|0] "" Vector__XXX
 SG_ VC_infoHCMRAppCRC m23 : 32|32@1+ (1,0) [0|0] "" Vector__XXX
 SG_ VC_infoWiperAppCRC m31 : 32|32@1+ (1,0) [0|0] "" Vector__XXX
 SG_ VCFRONT_infoBootCrc m20 : 24|32@1+ (1,0) [0|0] "" Vector__XXX
 SG_ VCFRONT_infoUsageId m11 : 24|16@1+ (1,0) [0|0] "" Vector__XXX
 SG_ VCFRONT_infoAssemblyId m11 : 16|8@1+ (1,0) [0|0] "" Vector__XXX
 SG_ VCFRONT_infoBuildConfigId m10 : 16|16@1+ (1,0) [0|0] "" Vector__XXX
 SG_ VCFRONT_infoAppCrc m13 : 8|32@1+ (1,0) [0|0] "" Vector__XXX
 SG_ VCFRONT_infoAppGitHash m17 : 8|56@1+ (1,0) [0|0] "" Vector__XXX
 SG_ VCFRONT_infoBootGitHash m18 : 8|56@1+ (1,0) [0|0] "" Vector__XXX
 SG_ VCFRONT_infoBootUdsProtoVersion m20 : 8|16@1+ (1,0) [0|0] "" Vector__XXX
 SG_ VCFRONT_infoBuildType m10 : 8|3@1+ (1,0) [0|0] "" Vector__XXX
 SG_ VCFRONT_infoPcbaId m11 : 8|8@1+ (1,0) [0|0] "" Vector__XXX
 SG_ VCFRONT_infoPlatformType m19 : 8|8@1+ (1,0) [0|0] "" Vector__XXX
 SG_ VCFRONT_infoIndex M : 0|8@1+ (1,0) [0|0] "" Vector__XXX

BO_ 1009 VCFRONT_lighting_3F1: 8 VEH
 SG_ VCFRONT_DRLLeftStatus: 36|2@1+ (1,0) [0|0] "" X
 SG_ VCFRONT_DRLRightStatus: 38|2@1+ (1,0) [0|0] "" X
 SG_ VCFRONT_ambientLightingBrightnes: 8|8@1+ (0.5,0) [0|0] "%" X
 SG_ VCFRONT_approachLightingRequest: 25|1@1+ (1,0) [0|0] "" X
 SG_ VCFRONT_courtesyLightingRequest: 24|1@1+ (1,0) [0|0] "" X
 SG_ VCFRONT_fogLeftStatus: 40|2@1+ (1,0) [0|0] "" X
 SG_ VCFRONT_fogRightStatus: 42|2@1+ (1,0) [0|0] "" X
 SG_ VCFRONT_hazardLightRequest: 4|3@1+ (1,0) [0|0] "" X
 SG_ VCFRONT_hazardSwitchBacklight: 27|1@1+ (1,0) [0|0] "" X
 SG_ VCFRONT_highBeamLeftStatus: 32|2@1+ (1,0) [0|0] "" X
 SG_ VCFRONT_highBeamRightStatus: 34|2@1+ (1,0) [0|0] "" X
 SG_ VCFRONT_highBeamSwitchActive: 58|1@1+ (1,0) [0|0] "" X
 SG_ VCFRONT_indicatorLeftRequest: 0|2@1+ (1,0) [0|0] "" X
 SG_ VCFRONT_indicatorRightRequest: 2|2@1+ (1,0) [0|0] "" X
 SG_ VCFRONT_lowBeamLeftStatus: 28|2@1+ (1,0) [0|0] "" X
 SG_ VCFRONT_lowBeamRightStatus: 30|2@1+ (1,0) [0|0] "" X
 SG_ VCFRONT_lowBeamsCalibrated: 62|1@1+ (1,0) [0|0] "" X
 SG_ VCFRONT_lowBeamsOnForDRL: 61|1@1+ (1,0) [0|0] "" X
 SG_ VCFRONT_parkLeftStatus: 54|2@1+ (1,0) [0|0] "" X
 SG_ VCFRONT_parkRightStatus: 56|2@1+ (1,0) [0|0] "" X
 SG_ VCFRONT_seeYouHomeLightingReq: 26|1@1+ (1,0) [0|0] "" X
 SG_ VCFRONT_sideMarkersStatus: 44|2@1+ (1,0) [0|0] "" X
 SG_ VCFRONT_sideRepeaterLeftStatus: 46|2@1+ (1,0) [0|0] "" X
 SG_ VCFRONT_sideRepeaterRightStatus: 48|2@1+ (1,0) [0|0] "" X
 SG_ VCFRONT_simLatchingStalk: 59|2@1+ (1,0) [0|0] "" X
 SG_ VCFRONT_switchLightingBrightness: 16|8@1+ (0.5,0) [0|0] "%" X
 SG_ VCFRONT_turnSignalLeftStatus: 50|2@1+ (1,0) [0|0] "" X
 SG_ VCFRONT_turnSignalRightStatus: 52|2@1+ (1,0) [0|0] "" X

BO_ 705 VCFRONT_logging10Hz: 8 VEH
 SG_ VCFRONT_logging10HzIndex M : 0|3@1+ (1,0) [0|7] "" X
 SG_ VCFRONT_activeLouverAbnormalKT m4 : 3|1@1+ (1,0) [0|1] "" X
 SG_ VCFRONT_activeLouverCalibRange m4 : 53|8@1+ (1,630) [630|880] "ticks" X
 SG_ VCFRONT_activeLouverCommSuccess m4 : 63|1@1+ (1,0) [0|1] "" X
 SG_ VCFRONT_activeLouverDemand m4 : 32|7@1+ (1,0) [0|100] "%" X
 SG_ VCFRONT_activeLouverDisconnect m4 : 6|1@1+ (1,0) [0|1] "" X
 SG_ VCFRONT_activeLouverFalsStallCal m4 : 62|1@1+ (1,0) [0|1] "" X
 SG_ VCFRONT_activeLouverFalsStallRun m4 : 61|1@1+ (1,0) [0|1] "" X
 SG_ VCFRONT_activeLouverIsCalibrated m4 : 15|1@1+ (1,0) [0|1] "" X
 SG_ VCFRONT_activeLouverMotorCounts m4 : 16|11@1+ (1,-100) [-100|1900] "ticks" X
 SG_ VCFRONT_activeLouverMotorState m4 : 8|3@1+ (1,0) [0|7] "" X
 SG_ VCFRONT_activeLouverOverCurrent m4 : 4|1@1+ (1,0) [0|1] "" X
 SG_ VCFRONT_activeLouverOverTemp m4 : 5|1@1+ (1,0) [0|1] "" X
 SG_ VCFRONT_activeLouverStallCounter m4 : 40|3@1+ (1,0) [0|7] "" X
 SG_ VCFRONT_activeLouverStallLength m4 : 43|10@1+ (1,0) [0|1000] "ticks" X
 SG_ VCFRONT_activeLouverStalled m4 : 7|1@1+ (1,0) [0|1] "" X
 SG_ VCFRONT_activeLouverState m4 : 11|4@1+ (1,0) [0|8] "" X
 SG_ VCFRONT_compLimitDeadband m3 : 8|1@1+ (1,0) [0|1] "" X
 SG_ VCFRONT_compLimitNvh m3 : 6|1@1+ (1,0) [0|1] "" X
 SG_ VCFRONT_compLimitPresDischargeHi m3 : 3|1@1+ (1,0) [0|1] "" X
 SG_ VCFRONT_compLimitScrollSepRamp m3 : 7|1@1+ (1,0) [0|1] "" X
 SG_ VCFRONT_compLimitScrollSepRegion m3 : 5|1@1+ (1,0) [0|1] "" X
 SG_ VCFRONT_compLimitTempDischargeHi m3 : 4|1@1+ (1,0) [0|1] "" X
 SG_ VCFRONT_compLimitTempDischargeSi m3 : 19|1@1+ (1,0) [0|1] "" X
 SG_ VCFRONT_compRampRateUpMax m3 : 20|6@1+ (0.1,0) [0|6] "%/s" X
 SG_ VCFRONT_compStandbyCoastDownMode m3 : 15|1@1+ (1,0) [0|1] "" X
 SG_ VCFRONT_compStandbyCommunication m3 : 10|1@1+ (1,0) [0|1] "" X
 SG_ VCFRONT_compStandbyHVNotReady m3 : 11|1@1+ (1,0) [0|1] "" X
 SG_ VCFRONT_compStandbyHighSuctionSu m3 : 16|1@1+ (1,0) [0|1] "" X
 SG_ VCFRONT_compStandbyLowAmbient m3 : 12|1@1+ (1,0) [0|1] "" X
 SG_ VCFRONT_compStandbyLowDischPress m3 : 13|1@1+ (1,0) [0|1] "" X
 SG_ VCFRONT_compStandbyMultiplePdCut m3 : 17|1@1+ (1,0) [0|1] "" X
 SG_ VCFRONT_compStandbyRefrigNotOk m3 : 14|1@1+ (1,0) [0|1] "" X
 SG_ VCFRONT_compStandbySelfNotReady m3 : 9|1@1+ (1,0) [0|1] "" X
 SG_ VCFRONT_compStandbyShowroomMode m3 : 18|1@1+ (1,0) [0|1] "" X
 SG_ VCFRONT_coolantFlowAmbSourceActu m0 : 48|8@1+ (0.1,0) [0|25] "LPM" X
 SG_ VCFRONT_coolantFlowAmbSourceTarg m0 : 56|8@1+ (0.1,0) [0|25] "LPM" X
 SG_ VCFRONT_coolantTempBasedMode m2 : 3|2@1+ (1,0) [0|3] "" X
 SG_ VCFRONT_coolantValveAngleActual m2 : 8|11@1+ (0.25,-100) [-100|410] "deg" X
 SG_ VCFRONT_coolantValveAngleTarget m2 : 19|10@1+ (0.25,-5) [-5|245] "deg" X
 SG_ VCFRONT_coolantValveAngleTravel m2 : 40|10@1+ (5,0) [0|5000] "deg" X
 SG_ VCFRONT_coolantValveDuty m2 : 32|8@1- (1,0) [-100|100] "%" X
 SG_ VCFRONT_coolantValveISense m2 : 56|7@1+ (0.01,0) [0|1.2] "A" X
 SG_ VCFRONT_coolantValveModeWrong m2 : 5|1@1+ (1,0) [0|1] "" X
 SG_ VCFRONT_coolantValveState m2 : 29|2@1+ (1,0) [0|3] "" X
 SG_ VCFRONT_exvFlow m3 : 32|10@1+ (0.1,0) [0|100] "%" X
 SG_ VCFRONT_exvIsFlooding m3 : 42|1@1+ (1,0) [0|1] "" X
 SG_ VCFRONT_exvMotorState m3 : 28|4@1+ (1,0) [0|10] "" X
 SG_ VCFRONT_exvPrechillActive m3 : 43|1@1+ (1,0) [0|1] "" X
 SG_ VCFRONT_pumpBatSpiError m0 : 46|1@1+ (1,0) [0|1] "" X
 SG_ VCFRONT_pumpBatteryEnabled m0 : 41|1@1+ (1,0) [0|1] "" X
 SG_ VCFRONT_pumpBatteryInitd m0 : 39|1@1+ (1,0) [0|1] "" X
 SG_ VCFRONT_pumpBatteryOutVoltage m0 : 24|7@1+ (0.2,0) [0|20] "V" X
 SG_ VCFRONT_pumpBatteryPowerOn m0 : 43|1@1+ (1,0) [0|1] "" X
 SG_ VCFRONT_pumpBatteryRPMTarget m0 : 3|10@1+ (10,0) [0|10000] "rpm" X
 SG_ VCFRONT_pumpPowertrainEnabled m0 : 42|1@1+ (1,0) [0|1] "" X
 SG_ VCFRONT_pumpPowertrainInitd m0 : 40|1@1+ (1,0) [0|1] "" X
 SG_ VCFRONT_pumpPowertrainOutVoltage m0 : 32|7@1+ (0.2,0) [0|20] "V" X
 SG_ VCFRONT_pumpPowertrainPowerOn m0 : 44|1@1+ (1,0) [0|1] "" X
 SG_ VCFRONT_pumpPowertrainRPMTarget m0 : 13|10@1+ (10,0) [0|10000] "rpm" X
 SG_ VCFRONT_pumpPtSpiError m0 : 47|1@1+ (1,0) [0|1] "" X
 SG_ VCFRONT_pumpsWake m0 : 45|1@1+ (1,0) [0|1] "" X
 SG_ VCFRONT_radarHeaterCurrent m6 : 8|8@1+ (0.1,0) [0|25.5] "A" X
 SG_ VCFRONT_radarHeaterDuty m6 : 16|7@1+ (1,0) [0|100] "%" X
 SG_ VCFRONT_radarHeaterTargetVoltage m6 : 24|8@1+ (0.1,0) [0|16] "V" X
 SG_ VCFRONT_radiatorFanDemandLimit m1 : 48|7@1+ (1,0) [0|100] "%" X
 SG_ VCFRONT_radiatorFanDemandLimited m1 : 47|1@1+ (1,0) [0|1] "" X
 SG_ VCFRONT_radiatorFanEnabled m1 : 27|1@1+ (1,0) [0|1] "" X
 SG_ VCFRONT_radiatorFanInitd m1 : 26|1@1+ (1,0) [0|1] "" X
 SG_ VCFRONT_radiatorFanOutVoltage m1 : 8|7@1+ (0.2,0) [0|20] "V" X
 SG_ VCFRONT_radiatorFanPhaseCurrent m1 : 32|8@1+ (0.25,-10) [-10|50] "A" X
 SG_ VCFRONT_radiatorFanPhaseIMax m1 : 40|7@1+ (0.25,0) [5|35] "A" X
 SG_ VCFRONT_radiatorFanPowerOn m1 : 28|1@1+ (1,0) [0|1] "" X
 SG_ VCFRONT_radiatorFanRPMTarget m1 : 16|10@1+ (10,0) [0|10000] "rpm" X
 SG_ VCFRONT_refrigerantHasBeenFilled m3 : 27|1@1+ (1,0) [0|1] "" X
 SG_ VCFRONT_refrigerantValvesClosed m3 : 26|1@1+ (1,0) [0|1] "" X
 SG_ VCFRONT_solenoidEvapCurrent m3 : 58|6@1+ (0.04,0) [0|2.4] "A" X
 SG_ VCFRONT_subcoolFeedbackFlow m5 : 13|10@1- (0.1,0) [-50|50] "%" X
 SG_ VCFRONT_subcoolFeedforwardFlow m5 : 3|10@1+ (0.1,0) [0|100] "%" X
 SG_ VCFRONT_subcoolProtectionFlow m5 : 24|10@1+ (0.1,0) [0|100] "%" X
 SG_ VCFRONT_subcoolProtectionType m5 : 34|3@1+ (1,0) [0|4] "" X
 SG_ VCFRONT_tempDischargeSimulated m3 : 44|11@1+ (0.125,-40) [-40|150] "C" X
 SG_ VCFRONT_thmlFanSpiError m1 : 55|1@1+ (1,0) [0|1] "" X
 SG_ VCFRONT_usingSimulatedAmbTemp m3 : 57|1@1+ (1,0) [0|1] "" X
 SG_ VCFRONT_usingSimulatedDischTemp m3 : 56|1@1+ (1,0) [0|1] "" X
 SG_ VCFRONT_usingSimulatedSuctTemp m3 : 55|1@1+ (1,0) [0|1] "" X

BO_ 897 VCFRONT_logging1Hz: 8 VEH
 SG_ VCFRONT_logging1HzIndex M : 0|5@1+ (1,0) [0|19] ""  Receiver
 SG_ VCFRONT_CCQdotActual m9 : 21|7@1+ (80,0) [0|10100] "W"  Receiver
 SG_ VCFRONT_CCQdotFdFrwrdTarget m9 : 7|7@1+ (80,0) [0|10100] "W"  Receiver
 SG_ VCFRONT_CCQdotFdbk m9 : 14|7@1- (80,0) [-5000|5000] "W"  Receiver
 SG_ VCFRONT_CMPDischargeSuperheat m8 : 17|5@1- (1,6) [-10|21] "C"  Receiver
 SG_ VCFRONT_DIQdotA m9 : 42|7@1+ (80,0) [0|10000] "W"  Receiver
 SG_ VCFRONT_HCML_bladeTemp m3 : 32|8@1- (1,67) [-60|194] "C"  Receiver
 SG_ VCFRONT_HCML_diffuseTemp m3 : 40|8@1- (1,67) [-60|194] "C"  Receiver
 SG_ VCFRONT_HCML_highBeamTemp m3 : 16|8@1- (1,67) [-60|194] "C"  Receiver
 SG_ VCFRONT_HCML_lowBeamSpotTemp m3 : 8|8@1- (1,67) [-60|194] "C"  Receiver
 SG_ VCFRONT_HCML_turnTemp m3 : 24|8@1- (1,67) [-60|194] "C"  Receiver
 SG_ VCFRONT_HCMR_bladeTemp m4 : 32|8@1- (1,67) [-60|194] "C"  Receiver
 SG_ VCFRONT_HCMR_diffuseTemp m4 : 40|8@1- (1,67) [-60|194] "C"  Receiver
 SG_ VCFRONT_HCMR_highBeamTemp m4 : 16|8@1- (1,67) [-60|194] "C"  Receiver
 SG_ VCFRONT_HCMR_lowBeamSpotTemp m4 : 8|8@1- (1,67) [-60|194] "C"  Receiver
 SG_ VCFRONT_HCMR_turnTemp m4 : 24|8@1- (1,67) [-60|194] "C"  Receiver
 SG_ VCFRONT_PDischargeControllerOutp m14 : 24|8@1+ (0.5,0) [0|100] "%"  Receiver
 SG_ VCFRONT_PSuctionControllerOutput m14 : 40|8@1+ (0.5,0) [0|100] "%"  Receiver
 SG_ VCFRONT_ambientColderThanBatt m16 : 8|1@1+ (1,0) [0|1] ""  Receiver
 SG_ VCFRONT_ambientSourcingAvailable m16 : 9|1@1+ (1,0) [0|1] ""  Receiver
 SG_ VCFRONT_ambientSourcingDisabled m14 : 38|1@1+ (1,0) [0|1] ""  Receiver
 SG_ VCFRONT_battDissipation m12 : 8|8@1+ (140,0) [0|35000] "W"  Receiver
 SG_ VCFRONT_battLoopWorthCooling m16 : 15|1@1+ (1,0) [0|1] ""  Receiver
 SG_ VCFRONT_battOverStagUpperLimit m16 : 6|1@1+ (1,0) [0|1] ""  Receiver
 SG_ VCFRONT_battUnderStagUpperLimit m16 : 7|1@1+ (1,0) [0|1] ""  Receiver
 SG_ VCFRONT_cabinHeatEnergyDuringDri m8 : 42|7@1+ (150,0) [0|19000] "Wh"  Receiver
 SG_ VCFRONT_calibratedPositionHCML m6 : 5|10@1+ (1,0) [0|1023] "Steps"  Receiver
 SG_ VCFRONT_calibratedPositionHCMR m6 : 16|10@1+ (1,0) [0|1023] "Steps"  Receiver
 SG_ VCFRONT_ccLeftExvCalibFailed m11 : 60|1@1+ (1,0) [0|1] ""  Receiver
 SG_ VCFRONT_ccLeftExvCalibOffset m11 : 40|8@1- (4,0) [-510|510] "ticks"  Receiver
 SG_ VCFRONT_ccLeftExvRange m7 : 41|9@1+ (3,0) [0|1500] "ticks"  Receiver
 SG_ VCFRONT_ccRightExvCalibFailed m11 : 61|1@1+ (1,0) [0|1] ""  Receiver
 SG_ VCFRONT_ccRightExvCalibOffset m11 : 48|8@1- (4,0) [-510|510] "ticks"  Receiver
 SG_ VCFRONT_ccRightExvRange m7 : 50|9@1+ (3,0) [0|1500] "ticks"  Receiver
 SG_ VCFRONT_chillerExvCalibFailed m11 : 56|1@1+ (1,0) [0|1] ""  Receiver
 SG_ VCFRONT_chillerExvCalibOffset m11 : 8|8@1- (4,0) [-510|510] "ticks"  Receiver
 SG_ VCFRONT_chillerExvRange m7 : 5|9@1+ (3,0) [0|1500] "ticks"  Receiver
 SG_ VCFRONT_chillerInletTempEstimate m13 : 27|8@1- (1,0) [-40|85] "C"  Receiver
 SG_ VCFRONT_chillerLiftDisabledLowPs m14 : 39|1@1+ (1,0) [0|1] ""  Receiver
 SG_ VCFRONT_chillerPassiveCoolPower m12 : 24|8@1- (60,7560) [0|15000] "W"  Receiver
 SG_ VCFRONT_compEnergyDuringDrive m8 : 35|7@1+ (150,0) [0|19000] "Wh"  Receiver
 SG_ VCFRONT_condenserPressureLimit m1 : 8|6@1+ (0.16,10) [10|20] "bar"  Receiver
 SG_ VCFRONT_coolantLevelVoltage m0 : 55|9@1+ (0.01,0) [0|5] "V"  Receiver
 SG_ VCFRONT_coolantValveAngleDrift m2 : 18|10@1+ (0.25,-127) [-127|127] "degrees"  Receiver
 SG_ VCFRONT_coolantValveCountRange m2 : 8|10@1+ (1,375) [375|1375] "ticks"  Receiver
 SG_ VCFRONT_coolantValveRadBypass m2 : 56|7@1+ (1,0) [0|100] "%"  Receiver
 SG_ VCFRONT_coolantValveRecalCount m2 : 28|16@1+ (1,0) [0|65535] ""  Receiver
 SG_ VCFRONT_coolantValveRecalReason m2 : 5|3@1+ (1,0) [0|6] ""  Receiver
 SG_ VCFRONT_coolantValveWindupEstL m2 : 44|6@1+ (2,0) [0|126] "ticks"  Receiver
 SG_ VCFRONT_coolantValveWindupEstR m2 : 50|6@1+ (2,0) [0|126] "ticks"  Receiver
 SG_ VCFRONT_currentPositionHCML m6 : 26|10@1+ (1,0) [0|1023] "Steps"  Receiver
 SG_ VCFRONT_currentPositionHCMR m6 : 36|10@1+ (1,0) [0|1023] "Steps"  Receiver
 SG_ VCFRONT_cycleModelConverged m10 : 61|1@1+ (1,0) [0|1] ""  Receiver
 SG_ VCFRONT_diDissipation m12 : 16|8@1+ (80,0) [0|20000] "W"  Receiver
 SG_ VCFRONT_dischargePressureTarget m14 : 8|7@1+ (0.25,0) [0|26] "bar"  Receiver
 SG_ VCFRONT_estCompPower m16 : 48|8@1+ (50,0) [0|12750] "W"  Receiver
 SG_ VCFRONT_estCompPressureInlet m16 : 24|8@1+ (0.05,0) [0|12.75] "bar"  Receiver
 SG_ VCFRONT_estCompPressureOutlet m16 : 32|8@1+ (0.1,0) [1|26.5] "bar"  Receiver
 SG_ VCFRONT_estCompRefrigMassflow m16 : 17|7@1+ (2,0) [0|254] "g/s"  Receiver
 SG_ VCFRONT_estCompTempOutlet m16 : 40|8@1+ (1.5,0) [0|190.5] "C"  Receiver
 SG_ VCFRONT_estCompressorRpm m10 : 48|6@1+ (400,0) [0|25200] "rpm"  Receiver
 SG_ VCFRONT_estPressureDisch m10 : 19|7@1+ (0.25,0) [0|31.75] "bar"  Receiver
 SG_ VCFRONT_estPressureLiq m10 : 5|7@1+ (0.25,0) [0|31.75] "bar"  Receiver
 SG_ VCFRONT_estPressureSuct m10 : 12|7@1+ (0.125,0) [0|11.5] "bar"  Receiver
 SG_ VCFRONT_estQLift m10 : 54|7@1+ (100,0) [0|12700] "W"  Receiver
 SG_ VCFRONT_estTempDisch m10 : 40|8@1- (0.8,68.8) [-34|170] "C"  Receiver
 SG_ VCFRONT_estTempLiq m10 : 26|8@1- (0.8,68.8) [-34|170] "C"  Receiver
 SG_ VCFRONT_estTempSuct m10 : 34|6@1- (1,2) [-30|33] "C"  Receiver
 SG_ VCFRONT_evapDisabledLowPsCutout m14 : 15|1@1+ (1,0) [0|1] ""  Receiver
 SG_ VCFRONT_evapExvCalibFailed m11 : 57|1@1+ (1,0) [0|1] ""  Receiver
 SG_ VCFRONT_evapExvCalibOffset m11 : 16|8@1- (4,0) [-510|510] "ticks"  Receiver
 SG_ VCFRONT_evapExvRange m7 : 14|9@1+ (3,0) [0|1500] "ticks"  Receiver
 SG_ VCFRONT_evapFdFrwrdTarget m9 : 28|7@1+ (80,0) [0|10100] "W"  Receiver
 SG_ VCFRONT_evapFdFrwrdTargetMinimum m9 : 49|7@1+ (80,0) [0|10000] "W"  Receiver
 SG_ VCFRONT_evapFdbk m9 : 35|7@1- (80,0) [-5000|5000] "W"  Receiver
 SG_ VCFRONT_exteriorQuietModeAllowed m9 : 6|1@1+ (1,0) [0|1] ""  Receiver
 SG_ VCFRONT_exteriorQuietModeEnabled m9 : 5|1@1+ (1,0) [0|1] ""  Receiver
 SG_ VCFRONT_fanControlFeedfwdActive m15 : 49|1@1+ (1,0) [0|1] ""  Receiver
 SG_ VCFRONT_fanControlRadCanCool m15 : 48|1@1+ (1,0) [0|1] ""  Receiver
 SG_ VCFRONT_fanControlRadiatorInletT m15 : 57|6@1- (1.8,36) [-20|90] "C"  Receiver
 SG_ VCFRONT_fanControlRadiatorUa m15 : 50|7@1+ (8,0) [0|1000] "W/C"  Receiver
 SG_ VCFRONT_fanDemandCondenser m1 : 14|7@1+ (1,0) [0|100] "%"  Receiver
 SG_ VCFRONT_fanDemandRadiator m1 : 21|7@1+ (1,0) [0|100] "%"  Receiver
 SG_ VCFRONT_feedBackDuctTempControll m15 : 32|8@1+ (1,-100) [-100|100] "-"  Receiver
 SG_ VCFRONT_feedBackEvapTempControll m15 : 24|7@1+ (0.01,-0.5) [-0.5|0.5] "-"  Receiver
 SG_ VCFRONT_feedFwdFanDemand m13 : 35|7@1+ (1,0) [0|100] "%"  Receiver
 SG_ VCFRONT_feedFwdMDotCabinCondense m15 : 16|8@1+ (0.005,0) [0|1] "-"  Receiver
 SG_ VCFRONT_feedFwdMDotEvaporator m15 : 8|8@1+ (0.005,0) [0|1] "-"  Receiver
 SG_ VCFRONT_feedFwdPumpDemand m13 : 42|7@1+ (1,0) [0|100] "%"  Receiver
 SG_ VCFRONT_feedfwdLoadCoolingDomina m9 : 59|1@1+ (1,0) [0|1] ""  Receiver
 SG_ VCFRONT_homelinkRegionCode m5 : 8|4@1+ (1,0) [0|9] ""  Receiver
 SG_ VCFRONT_hpAmbientSource m17 : 6|1@1+ (1,0) [0|1] ""  Receiver
 SG_ VCFRONT_hpAtSteadyState m16 : 63|1@1+ (1,0) [0|1] ""  Receiver
 SG_ VCFRONT_hpBattStagTarget m8 : 28|7@1+ (1,-40) [-40|80] "C"  Receiver
 SG_ VCFRONT_hpBatteryCool m17 : 19|1@1+ (1,0) [0|1] ""  Receiver
 SG_ VCFRONT_hpBatteryCoolCabinConden m17 : 20|1@1+ (1,0) [0|1] ""  Receiver
 SG_ VCFRONT_hpBatteryCoolCabinReheat m17 : 21|1@1+ (1,0) [0|1] ""  Receiver
 SG_ VCFRONT_hpBatteryCoolEvaporator m17 : 22|1@1+ (1,0) [0|1] ""  Receiver
 SG_ VCFRONT_hpBatteryHeatAmbientSour m17 : 17|1@1+ (1,0) [0|1] ""  Receiver
 SG_ VCFRONT_hpBatteryHeatCOP1 m17 : 18|1@1+ (1,0) [0|1] ""  Receiver
 SG_ VCFRONT_hpCOP m8 : 22|6@1+ (0.1,0) [0|6] "-"  Receiver
 SG_ VCFRONT_hpCabinCoolEvaporator m17 : 15|1@1+ (1,0) [0|1] ""  Receiver
 SG_ VCFRONT_hpCabinCoolEvaporatorReh m17 : 16|1@1+ (1,0) [0|1] ""  Receiver
 SG_ VCFRONT_hpCabinHeatAmbientSource m17 : 8|1@1+ (1,0) [0|1] ""  Receiver
 SG_ VCFRONT_hpCabinHeatBatteryCoolRe m17 : 14|1@1+ (1,0) [0|1] ""  Receiver
 SG_ VCFRONT_hpCabinHeatBatteryHeatRe m17 : 13|1@1+ (1,0) [0|1] ""  Receiver
 SG_ VCFRONT_hpCabinHeatBlend m17 : 11|1@1+ (1,0) [0|1] ""  Receiver
 SG_ VCFRONT_hpCabinHeatCOP1 m17 : 12|1@1+ (1,0) [0|1] ""  Receiver
 SG_ VCFRONT_hpCabinHeatReheatAmbient m17 : 10|1@1+ (1,0) [0|1] ""  Receiver
 SG_ VCFRONT_hpCabinHeatReheatScaveng m17 : 9|1@1+ (1,0) [0|1] ""  Receiver
 SG_ VCFRONT_hpCabinHeatScavengeOnly m17 : 7|1@1+ (1,0) [0|1] ""  Receiver
 SG_ VCFRONT_hpCompPowerIndex m16 : 56|7@1+ (1,0) [0|127] "-"  Receiver
 SG_ VCFRONT_hpForceScavenge m16 : 5|1@1+ (1,0) [0|1] ""  Receiver
 SG_ VCFRONT_hpGeneral m17 : 5|1@1+ (1,0) [0|1] ""  Receiver
 SG_ VCFRONT_hpMode m16 : 10|5@1+ (1,0) [0|19] ""  Receiver
 SG_ VCFRONT_hpPotentialLowRefrig m9 : 61|1@1+ (1,0) [0|1] ""  Receiver
 SG_ VCFRONT_hpRefrigerantPurgeState m9 : 62|2@1+ (1,0) [0|2] ""  Receiver
 SG_ VCFRONT_hpSubcoolTarget m8 : 12|5@1+ (1,0) [0|31] "C"  Receiver
 SG_ VCFRONT_lccExvCalibFailed m11 : 59|1@1+ (1,0) [0|1] ""  Receiver
 SG_ VCFRONT_lccExvCalibOffset m11 : 32|8@1- (4,0) [-510|510] "ticks"  Receiver
 SG_ VCFRONT_lccExvRange m7 : 32|9@1+ (3,0) [0|1500] "ticks"  Receiver
 SG_ VCFRONT_lccInletTempEstimate m13 : 19|8@1- (1,0) [-40|85] "C"  Receiver
 SG_ VCFRONT_lccPassiveHeatPower m12 : 32|8@1+ (60,0) [0|15000] "W"  Receiver
 SG_ VCFRONT_lowSideLiftEnergyDrive m8 : 49|7@1+ (150,0) [0|19000] "Wh"  Receiver
 SG_ VCFRONT_lowSideWattsLift m8 : 56|7@1+ (60,0) [0|7600] "W"  Receiver
 SG_ VCFRONT_maxAllowedEvapPowerInSer m12 : 40|8@1+ (40,0) [0|10000] "W"  Receiver
 SG_ VCFRONT_maxChillerCoolingPower m15 : 40|8@1+ (100,0) [0|20000] "W"  Receiver
 SG_ VCFRONT_maxCompressorRPMAllowed m14 : 56|7@1+ (90,0) [0|11430] "rpm"  Receiver
 SG_ VCFRONT_minAllowedChillerPowerIn m12 : 48|8@1+ (40,0) [0|10000] "W"  Receiver
 SG_ VCFRONT_minAllowedSuctionPressur m14 : 48|7@1+ (0.02,0) [0|2.5] "bar"  Receiver
 SG_ VCFRONT_minFlowPDCont m14 : 16|8@1+ (0.5,0) [0|100] "%"  Receiver
 SG_ VCFRONT_modeDesired m0 : 14|2@1+ (1,0) [0|3] ""  Receiver
 SG_ VCFRONT_modeTransitionID m0 : 8|6@1+ (1,0) [0|39] ""  Receiver
 SG_ VCFRONT_modelLoadCoolingDominant m9 : 60|1@1+ (1,0) [0|1] ""  Receiver
 SG_ VCFRONT_passiveCoolingState m9 : 56|2@1+ (1,0) [0|3] ""  Receiver
 SG_ VCFRONT_ptLoopWorthCooling m16 : 16|1@1+ (1,0) [0|1] ""  Receiver
 SG_ VCFRONT_pumpBatteryFETTemp m1 : 36|8@1+ (1,-40) [-40|150] "C"  Receiver
 SG_ VCFRONT_pumpPowertrainFETTemp m1 : 44|8@1+ (1,-40) [-40|150] "C"  Receiver
 SG_ VCFRONT_radActiveRejectEstimate m13 : 49|15@1+ (1,0) [0|30000] "W"  Receiver
 SG_ VCFRONT_radPassiveRejectEstimate m13 : 5|14@1+ (1,0) [0|15000] "W"  Receiver
 SG_ VCFRONT_radiatorFanFETTemp m1 : 52|8@1+ (1,-40) [-40|150] "C"  Receiver
 SG_ VCFRONT_radiatorFanRunReason m1 : 60|4@1+ (1,0) [0|8] ""  Receiver
 SG_ VCFRONT_recircExvCalibFailed m11 : 58|1@1+ (1,0) [0|1] ""  Receiver
 SG_ VCFRONT_recircExvCalibOffset m11 : 24|8@1- (4,0) [-510|510] "ticks"  Receiver
 SG_ VCFRONT_recircExvRange m7 : 23|9@1+ (3,0) [0|1500] "ticks"  Receiver
 SG_ VCFRONT_subcoolActual m8 : 5|7@1- (0.4,15.2) [-10|40] "C"  Receiver
 SG_ VCFRONT_suctionPressureTarget m14 : 32|6@1+ (0.15,0) [0|8] "bar"  Receiver
 SG_ VCFRONT_targetBatActiveCool m0 : 32|7@1+ (1,0) [0|100] "C"  Receiver
 SG_ VCFRONT_targetBatActiveHeat m0 : 48|7@1+ (1,-40) [-40|60] "C"  Receiver
 SG_ VCFRONT_targetBatPassive m0 : 40|7@1+ (1,-20) [-20|80] "C"  Receiver
 SG_ VCFRONT_targetPTActiveCool m0 : 16|8@1+ (1,-40) [-40|120] "C"  Receiver
 SG_ VCFRONT_targetPTPassive m0 : 24|8@1+ (1,-40) [-40|120] "C"  Receiver
 SG_ VCFRONT_tempRefrigSuction m1 : 28|8@1+ (0.5,-40) [-40|85] "C"  Receiver
 SG_ VCFRONT_totalLoadCoolingDominant m9 : 58|1@1+ (1,0) [0|1] ""  Receiver
 SG_ VCFRONT_wiperCycles m18 : 48|16@1+ (100,0) [0|6553500] "Cycles"  Receiver

BO_ 721 VCFRONT_okToUseHighPower: 2 Vector__XXX
 SG_ VCFRONT_tasOkToUseHighPower : 8|1@1+ (1,0) [0|0] "" Vector__XXX
 SG_ VCFRONT_premAudioOkToUseHiPower : 7|1@1+ (1,0) [0|0] "" Vector__XXX
 SG_ VCFRONT_cpOkToUseHighPower : 6|1@1+ (1,0) [0|0] "" Vector__XXX
 SG_ VCFRONT_MCUAudioOkToUseHighPower : 5|1@1+ (1,0) [0|0] "" Vector__XXX
 SG_ VCFRONT_MCULogicOkToUseHighPower : 4|1@1+ (1,0) [0|0] "" Vector__XXX
 SG_ VCFRONT_das2OkToUseHighPower : 3|1@1+ (1,0) [0|0] "" Vector__XXX
 SG_ VCFRONT_das1OkToUseHighPower : 2|1@1+ (1,0) [0|0] "" Vector__XXX
 SG_ VCFRONT_vcrightOkToUseHighPower : 1|1@1+ (1,0) [0|0] "" Vector__XXX
 SG_ VCFRONT_vcleftOkToUseHighPower : 0|1@1+ (1,0) [0|0] "" Vector__XXX

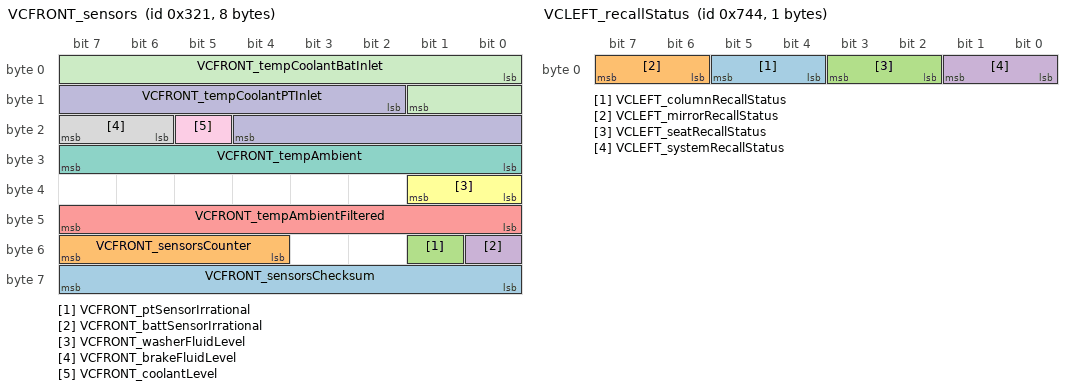
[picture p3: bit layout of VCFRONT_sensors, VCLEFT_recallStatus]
BO_ 801 VCFRONT_sensors: 8 Vector__XXX
 SG_ VCFRONT_sensorsChecksum : 56|8@1+ (1,0) [0|0] "" Vector__XXX
 SG_ VCFRONT_sensorsCounter : 52|4@1+ (1,0) [0|0] "" Vector__XXX
 SG_ VCFRONT_ptSensorIrrational : 49|1@1+ (1,0) [0|0] "" Vector__XXX
 SG_ VCFRONT_battSensorIrrational : 48|1@1+ (1,0) [0|0] "" Vector__XXX
 SG_ VCFRONT_tempAmbientFiltered : 40|8@1+ (0.5,-40) [0|0] "" Vector__XXX
 SG_ VCFRONT_washerFluidLevel : 32|2@1+ (1,0) [0|0] "" Vector__XXX
 SG_ VCFRONT_tempAmbient : 24|8@1+ (0.5,-40) [0|0] "" Vector__XXX
 SG_ VCFRONT_brakeFluidLevel : 22|2@1+ (1,0) [0|0] "" Vector__XXX
 SG_ VCFRONT_coolantLevel : 21|1@1+ (1,0) [0|0] "" Vector__XXX
 SG_ VCFRONT_tempCoolantPTInlet : 10|11@1+ (0.125,-40) [0|0] "" Vector__XXX
 SG_ VCFRONT_tempCoolantBatInlet : 0|10@1+ (0.125,-40) [0|0] "" Vector__XXX

BO_ 737 VCFRONT_status: 8 VEH
 SG_ VCFRONT_statusIndex M : 0|3@1+ (1,0) [0|6] "" X
 SG_ VCFRONT_12VARailStable m5 : 5|1@1+ (1,0) [0|1] "" X
 SG_ VCFRONT_12VBRailStable m5 : 6|1@1+ (1,0) [0|1] "" X
 SG_ VCFRONT_12VOverchargeCounter m4 : 16|4@1+ (1,0) [0|15] "" X
 SG_ VCFRONT_5VARailStable m5 : 3|1@1+ (1,0) [0|1] "" X
 SG_ VCFRONT_5VBRailStable m5 : 4|1@1+ (1,0) [0|1] "" X
 SG_ VCFRONT_AS8510Voltage m5 : 28|12@1+ (0.00544368,0) [0|22.2864] "V" X
 SG_ VCFRONT_ChargePumpVoltageStable m5 : 9|1@1+ (1,0) [0|1] "" X
 SG_ VCFRONT_HSDInitCompleteU13 m5 : 11|1@1+ (1,0) [0|1] "" X
 SG_ VCFRONT_HSDInitCompleteU16 m5 : 12|1@1+ (1,0) [0|1] "" X
 SG_ VCFRONT_IBSFault m4 : 15|1@1+ (1,0) [0|1] "" X
 SG_ VCFRONT_PCSMia m4 : 14|1@1+ (1,0) [0|1] "" X
 SG_ VCFRONT_PEResetLineState m5 : 10|1@1+ (1,0) [0|1] "" X
 SG_ VCFRONT_airCompressorStatus m0 : 25|3@1+ (1,0) [0|7] "" X
 SG_ VCFRONT_anyClosureOpen m0 : 49|1@1+ (1,0) [0|1] "" X
 SG_ VCFRONT_anyDoorOpen m0 : 50|1@1+ (1,0) [0|1] "" X
 SG_ VCFRONT_batterySMState m1 : 16|4@1+ (1,0) [0|8] "" X
 SG_ VCFRONT_chargeNeeded m4 : 13|1@1+ (1,0) [0|1] "" X
 SG_ VCFRONT_chillerDemandActive m3 : 26|1@1+ (1,0) [0|1] "" X
 SG_ VCFRONT_compPerfRecoveryLimited m3 : 27|1@1+ (1,0) [0|1] "" X
 SG_ VCFRONT_coolantFillRoutineStatus m3 : 50|2@1+ (1,0) [0|3] "" X
 SG_ VCFRONT_crashDetectedType m0 : 20|2@1+ (1,0) [0|2] "" X
 SG_ VCFRONT_crashState m0 : 22|2@1+ (1,0) [0|2] "" X
 SG_ VCFRONT_crashUnlockOverrideSet m0 : 24|1@1+ (1,0) [0|1] "" X
 SG_ VCFRONT_epasWakeLine m1 : 4|1@1+ (1,0) [0|1] "" X
 SG_ VCFRONT_freezeEvapITerm m3 : 24|1@1+ (1,0) [0|1] "" X
 SG_ VCFRONT_frunkAccessPost m0 : 62|1@1+ (1,0) [0|1] "" X
 SG_ VCFRONT_frunkInteriorRelSwitch m0 : 48|1@1+ (1,0) [0|1] "" X
 SG_ VCFRONT_frunkLatchStatus m0 : 3|4@1+ (1,0) [0|8] "" X
 SG_ VCFRONT_frunkLatchType m0 : 58|2@1+ (1,0) [0|2] "" X
 SG_ VCFRONT_hasLowRefrigerant m3 : 29|1@1+ (1,0) [0|1] "" X
 SG_ VCFRONT_headlampLeftFanStatus m0 : 60|1@1+ (1,0) [0|1] "" X
 SG_ VCFRONT_headlampRightFanStatus m0 : 61|1@1+ (1,0) [0|1] "" X
 SG_ VCFRONT_headlightLeftVPosition m0 : 28|10@1+ (1,0) [0|1023] "ticks" X
 SG_ VCFRONT_headlightRightVPosition m0 : 38|10@1+ (1,0) [0|1023] "ticks" X
 SG_ VCFRONT_homelinkCommStatus m2 : 48|2@1+ (1,0) [0|3] "" X
 SG_ VCFRONT_homelinkV2Response0 m2 : 8|8@1+ (1,0) [0|255] "" X
 SG_ VCFRONT_homelinkV2Response1 m2 : 16|8@1+ (1,0) [0|255] "" X
 SG_ VCFRONT_homelinkV2Response2 m2 : 24|8@1+ (1,0) [0|255] "" X
 SG_ VCFRONT_homelinkV2Response3 m2 : 32|8@1+ (1,0) [0|255] "" X
 SG_ VCFRONT_homelinkV2Response4 m2 : 40|8@1+ (1,0) [0|255] "" X
 SG_ VCFRONT_hornOn m0 : 51|1@1+ (1,0) [0|1] "" X
 SG_ VCFRONT_hvacPerfTestCommand m3 : 48|2@1+ (1,0) [0|2] "" X
 SG_ VCFRONT_iBoosterStateDBG m1 : 5|3@1+ (1,0) [0|4] "" X
 SG_ VCFRONT_iBoosterWakeLine m1 : 3|1@1+ (1,0) [0|1] "" X
 SG_ VCFRONT_isActiveHeatingBattery m0 : 63|1@1+ (1,0) [0|1] "" X
 SG_ VCFRONT_isColdStartRunning m3 : 30|1@1+ (1,0) [0|1] "" X
 SG_ VCFRONT_isEvapOperationAllowed m3 : 25|1@1+ (1,0) [0|1] "" X
 SG_ VCFRONT_isHeatPumpOilPurgeActive m3 : 31|1@1+ (1,0) [0|1] "" X
 SG_ VCFRONT_maxEvapHeatRejection m3 : 8|8@1+ (65,0) [0|16575] "W" X
 SG_ VCFRONT_minEvapHeatRejection m3 : 16|8@1+ (10,0) [0|2500] "W" X
 SG_ VCFRONT_pressureRefrigDischarge m3 : 40|8@1+ (0.125,0) [0|31.75] "bar" X
 SG_ VCFRONT_pressureRefrigSuction m3 : 32|7@1+ (0.125,0) [0|11.5] "bar" X
 SG_ VCFRONT_radarHeaterState m0 : 52|3@1+ (1,0) [0|4] "" X
 SG_ VCFRONT_railAState m5 : 7|1@1+ (1,0) [0|1] "" X
 SG_ VCFRONT_railBState m5 : 8|1@1+ (1,0) [0|1] "" X
 SG_ VCFRONT_refrigFillRoutineStatus m3 : 52|2@1+ (1,0) [0|3] ""  Receiver
 SG_ VCFRONT_reverseBatteryFault m4 : 30|1@1+ (1,0) [0|1] "" X
 SG_ VCFRONT_shortedCellFaultCounter m4 : 44|3@1+ (1,0) [0|7] "" X
 SG_ VCFRONT_silentWakeIBSCurrent m4 : 32|12@1- (0.1,-204.7) [-409.5|0] "mA" X
 SG_ VCFRONT_sleepCurrent m1 : 32|12@1- (0.1,-204.7) [-409.5|0] "mA" X
 SG_ VCFRONT_tempCompTargetVoltage m4 : 3|10@1+ (0.01,9) [9|16] "V" X
 SG_ VCFRONT_timeSpentSleeping m1 : 24|8@1+ (1,0) [0|255] "s" X
 SG_ VCFRONT_vbatMonitorVoltage m5 : 16|12@1+ (0.00544368,0) [0|22.2864] "V" X
 SG_ VCFRONT_vbatProt m5 : 40|12@1+ (0.00544368,0) [0|22.2919] "V" X
 SG_ VCFRONT_vehicleStatusDBG m1 : 8|5@1+ (1,0) [0|17] "" X
 SG_ VCFRONT_voltageDropCounter m4 : 20|4@1+ (1,0) [0|15] "" X
 SG_ VCFRONT_voltageFloorReachedCount m4 : 24|4@1+ (1,0) [0|15] "" X
 SG_ VCFRONT_voltageProfile m4 : 28|2@1+ (1,0) [0|3] "" X
 SG_ VCFRONT_wiperPosition m0 : 12|3@1+ (1,0) [0|4] "" X
 SG_ VCFRONT_wiperSpeed m0 : 8|4@1+ (1,0) [0|8] "" X
 SG_ VCFRONT_wiperState m0 : 16|4@1+ (1,0) [0|12] "" X

BO_ 929 VCFRONT_vehicleStatus: 8 Vector__XXX
 SG_ VCFRONT_vehicleStatusChecksum : 56|8@1+ (1,0) [0|0] "" Vector__XXX
 SG_ VCFRONT_vehicleStatusCounter : 52|4@1+ (1,0) [0|0] "" Vector__XXX
 SG_ VCFRONT_pcsEFuseVoltage m0 : 42|10@1+ (0.1,0) [0|0] "" Vector__XXX
 SG_ VCFRONT_hpBattHeatingPowerTrgt m1 : 41|7@1+ (100,0) [0|0] "" Vector__XXX
 SG_ VCFRONT_2RowRightUnbuckled m0 : 40|2@1+ (1,0) [0|0] "" Vector__XXX
 SG_ VCFRONT_anySWEFuseActive m1 : 40|1@1+ (1,0) [0|0] "" Vector__XXX
 SG_ VCFRONT_driverEnteredCabinEstimateDBG m1 : 39|1@1+ (1,0) [0|0] "" Vector__XXX
 SG_ VCFRONT_2RowCenterUnbuckled m0 : 38|2@1+ (1,0) [0|0] "" Vector__XXX
 SG_ VCFRONT_refSystemNominal m1 : 38|1@1+ (1,0) [0|0] "" Vector__XXX
 SG_ VCFRONT_2RowLeftUnbuckled m0 : 36|2@1+ (1,0) [0|0] "" Vector__XXX
 SG_ VCFRONT_passengerUnbuckled m0 : 34|2@1+ (1,0) [0|0] "" Vector__XXX
 SG_ VCFRONT_driverUnbuckled m0 : 32|2@1+ (1,0) [0|0] "" Vector__XXX
 SG_ VCFRONT_driverDoorStatus m0 : 31|1@1+ (1,0) [0|0] "" Vector__XXX
 SG_ VCFRONT_driverBuckleStatus m0 : 30|1@1+ (1,0) [0|0] "" Vector__XXX
 SG_ VCFRONT_ota12VSupportRequest m0 : 29|1@1+ (1,0) [0|0] "" Vector__XXX
 SG_ VCFRONT_factoryLimitsOverrideOk m0 : 27|1@1+ (1,0) [0|0] "" Vector__XXX
 SG_ VCFRONT_PCSCurrent m1 : 25|13@1- (0.1,0) [0|0] "" Vector__XXX
 SG_ VC_userPresenceState m0 : 24|2@1+ (1,0) [0|0] "" Vector__XXX
 SG_ VCFRONT_dcr12VMilliOhms m0 : 16|8@1+ (1,0) [0|0] "" Vector__XXX
 SG_ VCFRONT_hvacReqBattCoolOutTemp m1 : 16|9@1+ (0.1,40) [0|0] "" Vector__XXX
 SG_ VCFRONT_12vStatusForDrive m0 : 14|2@1+ (1,0) [0|0] "" Vector__XXX
 SG_ VCFRONT_diPowerOnState m0 : 10|3@1+ (1,0) [0|0] "" Vector__XXX
 SG_ VCFRONT_accPlusAvailable m0 : 9|1@1+ (1,0) [0|0] "" Vector__XXX
 SG_ VCFRONT_passengerPresent m0 : 8|1@1+ (1,0) [0|0] "" Vector__XXX
 SG_ VCFRONT_driverPresent m0 : 7|1@1+ (1,0) [0|0] "" Vector__XXX
 SG_ VCFRONT_maxBattHeatRejection m1 : 6|10@1+ (30,0) [0|0] "" Vector__XXX
 SG_ VCFRONT_standbySupplySupported m0 : 6|1@1+ (1,0) [0|0] "" Vector__XXX
 SG_ VCFRONT_thermalSystemType m0 : 5|1@1+ (1,0) [0|0] "" Vector__XXX
 SG_ VCFRONT_3RowRightUnbuckled m1 : 4|2@1+ (1,0) [0|0] "" Vector__XXX
 SG_ VCFRONT_3RowLeftUnbuckled m1 : 2|2@1+ (1,0) [0|0] "" Vector__XXX
 SG_ VCFRONT_APGlassHeaterState m0 : 2|3@1+ (1,0) [0|0] "" Vector__XXX
 SG_ VCFRONT_bmsHvChargeEnable m1 : 1|1@1+ (1,0) [0|0] "" Vector__XXX
 SG_ VCFRONT_preconditionRequest m0 : 1|1@1+ (1,0) [0|0] "" Vector__XXX
 SG_ VCFRONT_vehicleStatusMuxIndex M : 0|1@1+ (1,0) [0|0] "" Vector__XXX

BO_ 864 VCLEFT_alertMatrix: 8 VEH
 SG_ VCLEFT_matrixIndex M: 0|4@1+ (1,0) [0|0] "" X
 SG_ VCLEFT_a001_WatchdogReset m0: 4|1@1+ (1,0) [0|0] "" X
 SG_ VCLEFT_a002_PowerLossReset m0: 5|1@1+ (1,0) [0|0] "" X
 SG_ VCLEFT_a003_SWAssertion m0: 6|1@1+ (1,0) [0|0] "" X
 SG_ VCLEFT_a010_ExtSupplyVoltError m0: 13|1@1+ (1,0) [0|0] "" X
 SG_ VCLEFT_a012_CPUReset m0: 15|1@1+ (1,0) [0|0] "" X
 SG_ VCLEFT_a013_AlertManagerFault m0: 16|1@1+ (1,0) [0|0] "" X
 SG_ VCLEFT_a015_NVMMAlert m0: 18|1@1+ (1,0) [0|0] "" X
 SG_ VCLEFT_a021_TaskSchedulerError m0: 24|1@1+ (1,0) [0|0] "" X
 SG_ VCLEFT_a022_TaskInitError m0: 25|1@1+ (1,0) [0|0] "" X
 SG_ VCLEFT_a031_UDSActive m0: 34|1@1+ (1,0) [0|0] "" X
 SG_ VCLEFT_a041_HighCPULoad m0: 44|1@1+ (1,0) [0|0] "" X
 SG_ VCLEFT_a042_HighStackUsage m0: 45|1@1+ (1,0) [0|0] "" X
 SG_ VCLEFT_a043_Task1msError m0: 46|1@1+ (1,0) [0|0] "" X
 SG_ VCLEFT_a044_Task10msError m0: 47|1@1+ (1,0) [0|0] "" X
 SG_ VCLEFT_a045_Task100msError m0: 48|1@1+ (1,0) [0|0] "" X
 SG_ VCLEFT_a046_Task1000msError m0: 49|1@1+ (1,0) [0|0] "" X
 SG_ VCLEFT_a059_inputResistanceHigh m0: 62|1@1+ (1,0) [0|0] "" X
 SG_ VCLEFT_a060_engineeringBuild m0: 63|1@1+ (1,0) [0|0] "" X
 SG_ VCLEFT_a061_XCPConnected m1: 4|1@1+ (1,0) [0|0] "" X
 SG_ VCLEFT_a062_XCPWasConnected m1: 5|1@1+ (1,0) [0|0] "" X
 SG_ VCLEFT_a063_SwitchFault m1: 6|1@1+ (1,0) [0|0] "" X
 SG_ VCLEFT_a064_busSleepReqTimeout m1: 7|1@1+ (1,0) [0|0] "" X
 SG_ VCLEFT_a097_CMP_MIA m1: 40|1@1+ (1,0) [0|0] "" X
 SG_ VCLEFT_a098_DI_THERMAL_MIA m1: 41|1@1+ (1,0) [0|0] "" X
 SG_ VCLEFT_a099_PARK_MIA m1: 42|1@1+ (1,0) [0|0] "" X
 SG_ VCLEFT_a100_CANbus_MIA m1: 43|1@1+ (1,0) [0|0] "" X
 SG_ VCLEFT_a101_PM_MIA m1: 44|1@1+ (1,0) [0|0] "" X
 SG_ VCLEFT_a102_PTC_MIA m1: 45|1@1+ (1,0) [0|0] "" X
 SG_ VCLEFT_a103_CP_MIA m1: 46|1@1+ (1,0) [0|0] "" X
 SG_ VCLEFT_a104_DAS_MIA m1: 47|1@1+ (1,0) [0|0] "" X
 SG_ VCLEFT_a105_TAS_MIA m1: 48|1@1+ (1,0) [0|0] "" X
 SG_ VCLEFT_a106_PCS_MIA m1: 49|1@1+ (1,0) [0|0] "" X
 SG_ VCLEFT_a107_BMS_MIA m1: 50|1@1+ (1,0) [0|0] "" X
 SG_ VCLEFT_a108_DIS_MIA m1: 51|1@1+ (1,0) [0|0] "" X
 SG_ VCLEFT_a109_RCM_MIA m1: 52|1@1+ (1,0) [0|0] "" X
 SG_ VCLEFT_a110_GTW_MIA m1: 53|1@1+ (1,0) [0|0] "" X
 SG_ VCLEFT_a111_EPBR_MIA m1: 54|1@1+ (1,0) [0|0] "" X
 SG_ VCLEFT_a112_EPBL_MIA m1: 55|1@1+ (1,0) [0|0] "" X
 SG_ VCLEFT_a113_UI_MIA m1: 56|1@1+ (1,0) [0|0] "" X
 SG_ VCLEFT_a114_ESP_MIA m1: 57|1@1+ (1,0) [0|0] "" X
 SG_ VCLEFT_a115_VCSEC_MIA m1: 58|1@1+ (1,0) [0|0] "" X
 SG_ VCLEFT_a116_VCRIGHT_MIA m1: 59|1@1+ (1,0) [0|0] "" X
 SG_ VCLEFT_a117_VCLEFT_MIA m1: 60|1@1+ (1,0) [0|0] "" X
 SG_ VCLEFT_a118_VCFRONT_MIA m1: 61|1@1+ (1,0) [0|0] "" X
 SG_ VCLEFT_a119_SCCM_MIA m1: 62|1@1+ (1,0) [0|0] "" X
 SG_ VCLEFT_a120_DI_DRIVE_MIA m1: 63|1@1+ (1,0) [0|0] "" X
 SG_ VCLEFT_a129_blowerICLatchFault m2: 12|1@1+ (1,0) [0|0] "" X
 SG_ VCLEFT_a130_blowerICWarning m2: 13|1@1+ (1,0) [0|0] "" X
 SG_ VCLEFT_a131_blowerICTransFault m2: 14|1@1+ (1,0) [0|0] "" X
 SG_ VCLEFT_a132_blowerSoftStall m2: 15|1@1+ (1,0) [0|0] "" X
 SG_ VCLEFT_a133_blowerLowRPMCBang m2: 16|1@1+ (1,0) [0|0] "" X
 SG_ VCLEFT_a134_SteerColUpDownUnCal m2: 17|1@1+ (1,0) [0|0] "" X
 SG_ VCLEFT_a135_SteerColInOutUnCal m2: 18|1@1+ (1,0) [0|0] "" X
 SG_ VCLEFT_a136_brakeSwitchMismatch m2: 19|1@1+ (1,0) [0|0] "" X
 SG_ VCLEFT_a137_VCSECPowerCycled m2: 20|1@1+ (1,0) [0|0] "" X
 SG_ VCLEFT_a138_consoleDoorAssist m2: 21|1@1+ (1,0) [0|0] "" X
 SG_ VCLEFT_a139_BLERearPowerCycled m2: 22|1@1+ (1,0) [0|0] "" X
 SG_ VCLEFT_a140_BLELeftPowerCycled m2: 23|1@1+ (1,0) [0|0] "" X
 SG_ VCLEFT_a141_12VAuxPowerTrip m2: 24|1@1+ (1,0) [0|0] "" X
 SG_ VCLEFT_a150_windowPinchFront m2: 33|1@1+ (1,0) [0|0] "" X
 SG_ VCLEFT_a151_windowPinchRear m2: 34|1@1+ (1,0) [0|0] "" X
 SG_ VCLEFT_a152_windowUncalFront m2: 35|1@1+ (1,0) [0|0] "" X
 SG_ VCLEFT_a153_windowUncalRear m2: 36|1@1+ (1,0) [0|0] "" X
 SG_ VCLEFT_a154_windowThermalFront m2: 37|1@1+ (1,0) [0|0] "" X
 SG_ VCLEFT_a155_windowThermalRear m2: 38|1@1+ (1,0) [0|0] "" X
 SG_ VCLEFT_a156_windowNoInputFront m2: 39|1@1+ (1,0) [0|0] "" X
 SG_ VCLEFT_a157_windowNoInputRear m2: 40|1@1+ (1,0) [0|0] "" X
 SG_ VCLEFT_a158_windowPinchOverideF m2: 41|1@1+ (1,0) [0|0] "" X
 SG_ VCLEFT_a159_windowPinchOverideR m2: 42|1@1+ (1,0) [0|0] "" X
 SG_ VCLEFT_a160_windowUndercurrentF m2: 43|1@1+ (1,0) [0|0] "" X
 SG_ VCLEFT_a161_windowUndercurrentR m2: 44|1@1+ (1,0) [0|0] "" X
 SG_ VCLEFT_a162_windowEncoderStallF m2: 45|1@1+ (1,0) [0|0] "" X
 SG_ VCLEFT_a163_windowEncoderStallR m2: 46|1@1+ (1,0) [0|0] "" X
 SG_ VCLEFT_a164_windowFactoryTest m2: 47|1@1+ (1,0) [0|0] "" X
 SG_ VCLEFT_a165_windowFactoryTest2 m2: 48|1@1+ (1,0) [0|0] "" X
 SG_ VCLEFT_a166_windowDebug m2: 49|1@1+ (1,0) [0|0] "" X
 SG_ VCLEFT_a167_windowDebugPinchF m2: 50|1@1+ (1,0) [0|0] "" X
 SG_ VCLEFT_a168_windowDebugPinchR m2: 51|1@1+ (1,0) [0|0] "" X
 SG_ VCLEFT_a169_windowCurrentPeakF m2: 52|1@1+ (1,0) [0|0] "" X
 SG_ VCLEFT_a170_windowCurrentPeakR m2: 53|1@1+ (1,0) [0|0] "" X
 SG_ VCLEFT_a172_SPI_MIA m2: 55|1@1+ (1,0) [0|0] "" X
 SG_ VCLEFT_a180_frontDoorLatchRehome m2: 63|1@1+ (1,0) [0|0] "" X
 SG_ VCLEFT_a181_rearDoorLatchRehome m3: 4|1@1+ (1,0) [0|0] "" X
 SG_ VCLEFT_a182_emergencyLatchRel m3: 5|1@1+ (1,0) [0|0] "" X
 SG_ VCLEFT_a183_doorStateFactoryTest m3: 6|1@1+ (1,0) [0|0] "" X
 SG_ VCLEFT_a185_summonAborted m3: 8|1@1+ (1,0) [0|0] "" X
 SG_ VCLEFT_a186_latchReleaseFailedF m3: 9|1@1+ (1,0) [0|0] "" X
 SG_ VCLEFT_a187_latchReleaseFailedR m3: 10|1@1+ (1,0) [0|0] "" X
 SG_ VCLEFT_a188_latchUnableToRearmF m3: 11|1@1+ (1,0) [0|0] "" X
 SG_ VCLEFT_a189_latchUnableToRearmR m3: 12|1@1+ (1,0) [0|0] "" X
 SG_ VCLEFT_a190_eFuseMgmtVbatFused m3: 13|1@1+ (1,0) [0|0] "" X
 SG_ VCLEFT_a191_TLCOvercurrent m3: 14|1@1+ (1,0) [0|0] "" X
 SG_ VCLEFT_a196_VEHCANOverterminate m3: 19|1@1+ (1,0) [0|0] "" X
 SG_ VCLEFT_a197_VEHCANUndertrminate m3: 20|1@1+ (1,0) [0|0] "" X
 SG_ VCLEFT_a200_motorPhantomEncoder m3: 23|1@1+ (1,0) [0|0] "" X
 SG_ VCLEFT_a201_motorDutyEncDisabl m3: 24|1@1+ (1,0) [0|0] "" X
 SG_ VCLEFT_a202_epbmUnderIStatic m3: 25|1@1+ (1,0) [0|0] "" X
 SG_ VCLEFT_a203_epbmOverIStatic m3: 26|1@1+ (1,0) [0|0] "" X
 SG_ VCLEFT_a204_epbmUnderIDyn m3: 27|1@1+ (1,0) [0|0] "" X
 SG_ VCLEFT_a205_epbmOverIDyn m3: 28|1@1+ (1,0) [0|0] "" X
 SG_ VCLEFT_a206_epbWrongDirection m3: 29|1@1+ (1,0) [0|0] "" X
 SG_ VCLEFT_a207_epbmEnableWrong m3: 30|1@1+ (1,0) [0|0] "" X
 SG_ VCLEFT_a208_epbFaulted m3: 31|1@1+ (1,0) [0|0] "" X
 SG_ VCLEFT_a209_epbStateMisTime m3: 32|1@1+ (1,0) [0|0] "" X
 SG_ VCLEFT_a210_epbStateTime m3: 33|1@1+ (1,0) [0|0] "" X
 SG_ VCLEFT_a211_epbmUnderIStaticNew m3: 34|1@1+ (1,0) [0|0] "" X
 SG_ VCLEFT_a212_epbmOverIStaticNew m3: 35|1@1+ (1,0) [0|0] "" X
 SG_ VCLEFT_a213_epbmUnderIDynNew m3: 36|1@1+ (1,0) [0|0] "" X
 SG_ VCLEFT_a214_epbmOverIDynNew m3: 37|1@1+ (1,0) [0|0] "" X
 SG_ VCLEFT_a215_currentDesyncWarning m3: 38|1@1+ (1,0) [0|0] "" X
 SG_ VCLEFT_a216_SPI_MIA_debugData1 m3: 39|1@1+ (1,0) [0|0] "" X
 SG_ VCLEFT_a217_SPI_MIA_debugData2 m3: 40|1@1+ (1,0) [0|0] "" X
 SG_ VCLEFT_a218_motorDriverFault m3: 41|1@1+ (1,0) [0|0] "" X
 SG_ VCLEFT_a219_motorCurrentDropout m3: 42|1@1+ (1,0) [0|0] "" X
 SG_ VCLEFT_a220_seatCurrStallTrack m3: 43|1@1+ (1,0) [0|0] "" X
 SG_ VCLEFT_a221_seatCurrStallBack m3: 44|1@1+ (1,0) [0|0] "" X
 SG_ VCLEFT_a222_seatCurrStallTilt m3: 45|1@1+ (1,0) [0|0] "" X
 SG_ VCLEFT_a223_seatCurrStallLift m3: 46|1@1+ (1,0) [0|0] "" X
 SG_ VCLEFT_a224_seatEncStallTrack m3: 47|1@1+ (1,0) [0|0] "" X
 SG_ VCLEFT_a225_seatEncStallBack m3: 48|1@1+ (1,0) [0|0] "" X
 SG_ VCLEFT_a226_seatEncStallTilt m3: 49|1@1+ (1,0) [0|0] "" X
 SG_ VCLEFT_a227_seatEncStallLift m3: 50|1@1+ (1,0) [0|0] "" X
 SG_ VCLEFT_a228_seatEncOverTrack m3: 51|1@1+ (1,0) [0|0] "" X
 SG_ VCLEFT_a229_seatEncOverBack m3: 52|1@1+ (1,0) [0|0] "" X
 SG_ VCLEFT_a230_seatEncOverTilt m3: 53|1@1+ (1,0) [0|0] "" X
 SG_ VCLEFT_a231_seatEncOverLift m3: 54|1@1+ (1,0) [0|0] "" X
 SG_ VCLEFT_a232_seatCurrUnderTrack m3: 55|1@1+ (1,0) [0|0] "" X
 SG_ VCLEFT_a233_seatCurrUnderBack m3: 56|1@1+ (1,0) [0|0] "" X
 SG_ VCLEFT_a234_seatCurrUnderTilt m3: 57|1@1+ (1,0) [0|0] "" X
 SG_ VCLEFT_a235_seatCurrUnderLift m3: 58|1@1+ (1,0) [0|0] "" X
 SG_ VCLEFT_a236_lumbarOverPresA m3: 59|1@1+ (1,0) [0|0] "" X
 SG_ VCLEFT_a237_lumbarOverPresB m3: 60|1@1+ (1,0) [0|0] "" X
 SG_ VCLEFT_a238_lumbarValveMIA m3: 61|1@1+ (1,0) [0|0] "" X
 SG_ VCLEFT_a239_seatHeatIFront m3: 62|1@1+ (1,0) [0|0] "" X
 SG_ VCLEFT_a240_seatHeatShortFront m3: 63|1@1+ (1,0) [0|0] "" X
 SG_ VCLEFT_a241_seatHeatMIAFront m4: 4|1@1+ (1,0) [0|0] "" X
 SG_ VCLEFT_a242_seatHeatIRearL m4: 5|1@1+ (1,0) [0|0] "" X
 SG_ VCLEFT_a243_seatHeatShortRearL m4: 6|1@1+ (1,0) [0|0] "" X
 SG_ VCLEFT_a244_seatHeatMIARearL m4: 7|1@1+ (1,0) [0|0] "" X
 SG_ VCLEFT_a251_seatUncalTrack m4: 14|1@1+ (1,0) [0|0] "" X
 SG_ VCLEFT_a252_seatUncalBack m4: 15|1@1+ (1,0) [0|0] "" X
 SG_ VCLEFT_a253_seatUncalTilt m4: 16|1@1+ (1,0) [0|0] "" X
 SG_ VCLEFT_a254_seatUncalLift m4: 17|1@1+ (1,0) [0|0] "" X
 SG_ VCLEFT_a259_latchDisarmDelayF m4: 22|1@1+ (1,0) [0|0] "" X
 SG_ VCLEFT_a260_latchDisarmDelayR m4: 23|1@1+ (1,0) [0|0] "" X
 SG_ VCLEFT_a263_seatTrackStallDebug m4: 26|1@1+ (1,0) [0|0] "" X
 SG_ VCLEFT_a264_seatBackStallDebug m4: 27|1@1+ (1,0) [0|0] "" X
 SG_ VCLEFT_a265_seatTiltStallDebug m4: 28|1@1+ (1,0) [0|0] "" X
 SG_ VCLEFT_a266_seatLiftStallDebug m4: 29|1@1+ (1,0) [0|0] "" X
 SG_ VCLEFT_a267_seatTrackHCEncStlDbg m4: 30|1@1+ (1,0) [0|0] "" X
 SG_ VCLEFT_a268_seatBackHCEncStlDbg m4: 31|1@1+ (1,0) [0|0] "" X
 SG_ VCLEFT_a269_seatTiltHCEncStlDbg m4: 32|1@1+ (1,0) [0|0] "" X
 SG_ VCLEFT_a270_seatLiftHCEncStlDbg m4: 33|1@1+ (1,0) [0|0] "" X
 SG_ VCLEFT_a272_vhclPwrStateMsmtch m4: 35|1@1+ (1,0) [0|0] "" X
 SG_ VCLEFT_a273_handleStuckActiveF m4: 36|1@1+ (1,0) [0|0] "" X
 SG_ VCLEFT_a274_handleStuckActiveR m4: 37|1@1+ (1,0) [0|0] "" X
 SG_ VCLEFT_a275_leftTurnLightFault m4: 38|1@1+ (1,0) [0|0] "" X
 SG_ VCLEFT_a276_mirrorDebug m4: 39|1@1+ (1,0) [0|0] "" X
 SG_ VCLEFT_a277_BLELeftUnderVoltage m4: 40|1@1+ (1,0) [0|0] "" X
 SG_ VCLEFT_a278_BLERearUnderVoltage m4: 41|1@1+ (1,0) [0|0] "" X
 SG_ VCLEFT_a279_VCSECUnderVoltage m4: 42|1@1+ (1,0) [0|0] "" X
 SG_ VCLEFT_a280_latchDidNotDisarmF m4: 43|1@1+ (1,0) [0|0] "" X
 SG_ VCLEFT_a281_latchDidNotDisarmR m4: 44|1@1+ (1,0) [0|0] "" X
 SG_ VCLEFT_a282_latchUnexpectedArmF m4: 45|1@1+ (1,0) [0|0] "" X
 SG_ VCLEFT_a283_latchUnexpectedArmR m4: 46|1@1+ (1,0) [0|0] "" X
 SG_ VCLEFT_a284_blowerFbkSanity m4: 47|1@1+ (1,0) [0|0] "" X
 SG_ VCLEFT_a285_blowerChipComms m4: 48|1@1+ (1,0) [0|0] "" X
 SG_ VCLEFT_a286_windowSpeedInvalidF m4: 49|1@1+ (1,0) [0|0] "" X
 SG_ VCLEFT_a287_windowSpeedInvalidR m4: 50|1@1+ (1,0) [0|0] "" X
 SG_ VCLEFT_a290_occupancyFaultedFront m4: 53|1@1+ (1,0) [0|0] "" X
 SG_ VCLEFT_a291_buckleFaultedFront m4: 54|1@1+ (1,0) [0|0] "" X
 SG_ VCLEFT_a292_occupancyFaultedRearL m4: 55|1@1+ (1,0) [0|0] "" X
 SG_ VCLEFT_a293_occupancyFaultedRearC m4: 56|1@1+ (1,0) [0|0] "" X
 SG_ VCLEFT_a294_occupancyFaultedRearR m4: 57|1@1+ (1,0) [0|0] "" X
 SG_ VCLEFT_a295_buckleFaultedRearL m4: 58|1@1+ (1,0) [0|0] "" X
 SG_ VCLEFT_a300_swcUnderVoltage m4: 63|1@1+ (1,0) [0|0] "" X
 SG_ VCLEFT_a301_swcOverVoltage m5: 4|1@1+ (1,0) [0|0] "" X
 SG_ VCLEFT_a302_blowerGeneralFault m5: 5|1@1+ (1,0) [0|0] "" X
 SG_ VCLEFT_a303_eFuseMgmtWindowLift m5: 6|1@1+ (1,0) [0|0] "" X
 SG_ VCLEFT_a304_frontIntHandleShorted m5: 7|1@1+ (1,0) [0|0] "" X
 SG_ VCLEFT_a305_rearIntHandleShorted m5: 8|1@1+ (1,0) [0|0] "" X
 SG_ VCLEFT_a306_handleDisconnectedF m5: 9|1@1+ (1,0) [0|0] "" X
 SG_ VCLEFT_a307_handleDisconnectedR m5: 10|1@1+ (1,0) [0|0] "" X

BO_ 258 VCLEFT_doorStatus: 8 VEH
 SG_ VCLEFT_frontHandlePWM: 16|7@1+ (1,0) [0|0] "%" X
 SG_ VCLEFT_frontHandlePulled: 10|1@1+ (1,0) [0|0] "" X
 SG_ VCLEFT_frontHandlePulledPersist: 62|1@1+ (1,0) [0|0] "" X
 SG_ VCLEFT_frontIntSwitchPressed: 31|1@1+ (1,0) [0|0] "" X
 SG_ VCLEFT_frontLatchStatus: 0|4@1+ (1,0) [0|0] "" X
 SG_ VCLEFT_frontLatchSwitch: 8|1@1+ (1,0) [0|0] "" X
 SG_ VCLEFT_frontRelActuatorSwitch: 12|1@1+ (1,0) [0|0] "" X
 SG_ VCLEFT_mirrorDipped: 61|1@1+ (1,0) [0|0] "" X
 SG_ VCLEFT_mirrorFoldState: 52|3@1+ (1,0) [0|0] "" X
 SG_ VCLEFT_mirrorHeatState: 58|3@1+ (1,0) [0|0] "" X
 SG_ VCLEFT_mirrorRecallState: 55|3@1+ (1,0) [0|0] "" X
 SG_ VCLEFT_mirrorState: 49|3@1+ (1,0) [0|0] "" X
 SG_ VCLEFT_mirrorTiltXPosition: 33|8@1+ (0.02,0) [0|0] "V" X
 SG_ VCLEFT_mirrorTiltYPosition: 41|8@1+ (0.02,0) [0|0] "V" X
 SG_ VCLEFT_rearHandlePWM: 24|7@1+ (1,0) [0|0] "%" X
 SG_ VCLEFT_rearHandlePulled: 11|1@1+ (1,0) [0|0] "" X
 SG_ VCLEFT_rearIntSwitchPressed: 32|1@1+ (1,0) [0|0] "" X
 SG_ VCLEFT_rearLatchStatus: 4|4@1+ (1,0) [0|0] "" X
 SG_ VCLEFT_rearLatchSwitch: 9|1@1+ (1,0) [0|0] "" X
 SG_ VCLEFT_rearRelActuatorSwitch: 13|1@1+ (1,0) [0|0] "" X

BO_ 626 VCLEFT_epbmDebug: 8 VEH
 SG_ VCLEFT_epbmDebugIndex M: 0|1@1+ (1,0) [0|0] "" X
 SG_ VCLEFT_epbmCaliperState m0: 1|3@1+ (1,0) [0|0] "" X
 SG_ VCLEFT_epbmMotorEnabled m0: 4|1@1+ (1,0) [0|0] "" X
 SG_ VCLEFT_epbMotorCurrent m0: 5|11@1+ (0.01,0) [0|0] "A" X
 SG_ VCLEFT_epbmApplyVoltage m0: 16|11@1+ (0.01,0) [0|0] "A" X
 SG_ VCLEFT_epbmReleaseVoltage m0: 27|11@1+ (0.01,0) [0|0] "A" X
 SG_ VCLEFT_summonFaultReason m0: 38|5@1+ (1,0) [0|0] "" X
 SG_ VCLEFT_epbSummonState m0: 43|3@1+ (1,0) [0|0] "" X
 SG_ VCLEFT_epbmSummonState m0: 46|3@1+ (1,0) [0|0] "" X
 SG_ VCLEFT_epbmUnitStatus m0: 49|5@1+ (1,0) [0|0] "" X
 SG_ VCLEFT_epbUnitStatus m0: 54|5@1+ (1,0) [0|0] "" X
 SG_ VCLEFT_epbmFaultStatus m0: 59|2@1+ (1,0) [0|0] "" X
 SG_ VCLEFT_epbFaultStatus m0: 61|2@1+ (1,0) [0|0] "" X
 SG_ VCLEFT_epbmOpenAllowed m1: 1|1@1+ (1,0) [0|0] "" X
 SG_ VCLEFT_epbmDynamicAllowed m1: 2|1@1+ (1,0) [0|0] "" X
 SG_ VCLEFT_epbmParkAllowed m1: 3|1@1+ (1,0) [0|0] "" X
 SG_ VCLEFT_epbmStartAllowed m1: 4|1@1+ (1,0) [0|0] "" X
 SG_ VCLEFT_epbmServiceAllowed m1: 5|1@1+ (1,0) [0|0] "" X
 SG_ VCLEFT_epbmWinchAllowed m1: 6|1@1+ (1,0) [0|0] "" X
 SG_ VCLEFT_epbmWinchReleaseAllowed m1: 7|1@1+ (1,0) [0|0] "" X
 SG_ VCLEFT_epbmParkingAllowed m1: 8|1@1+ (1,0) [0|0] "" X
 SG_ VCLEFT_epbmDynApplyingAllowed m1: 9|1@1+ (1,0) [0|0] "" X
 SG_ VCLEFT_epbmReleasingAllowed m1: 10|1@1+ (1,0) [0|0] "" X
 SG_ VCLEFT_epbmFaultAllowed m1: 11|1@1+ (1,0) [0|0] "" X
 SG_ VCLEFT_epbmSummonAllowed m1: 12|1@1+ (1,0) [0|0] "" X
 SG_ VCLEFT_epbmSummonParkAllowed m1: 13|1@1+ (1,0) [0|0] "" X
 SG_ VCLEFT_epbmSummonReleaseAllowed m1: 14|1@1+ (1,0) [0|0] "" X
 SG_ VCLEFT_summonInitAllowed m1: 15|1@1+ (1,0) [0|0] "" X
 SG_ VCLEFT_epbmUnknownAllowed m1: 16|1@1+ (1,0) [0|0] "" X
 SG_ VCLEFT_summonIdleAllowed m1: 17|1@1+ (1,0) [0|0] "" X
 SG_ VCLEFT_summonArmedAllowed m1: 18|1@1+ (1,0) [0|0] "" X
 SG_ VCLEFT_summonActiveAllowed m1: 19|1@1+ (1,0) [0|0] "" X
 SG_ VCLEFT_summonCompleteAllowed m1: 20|1@1+ (1,0) [0|0] "" X
 SG_ VCLEFT_summonFaultAllowed m1: 21|1@1+ (1,0) [0|0] "" X
 SG_ VCLEFT_summonUnavailableAllowed m1: 22|1@1+ (1,0) [0|0] "" X
 SG_ VCLEFT_cdpEnumDummy m1: 24|2@1+ (1,0) [0|0] "" X

BO_ 642 VCLEFT_hvacBlowerFeedback: 8 VEH
 SG_ VCLEFT_blowerIndex M: 0|2@1+ (1,0) [0|0] "" X
 SG_ VCLEFT_hvacBlowerEnabled m0: 2|1@1+ (1,0) [0|0] "" X
 SG_ VCLEFT_hvacBlowerOutputDuty m0: 3|7@1+ (1,0) [0|0] "%" X
 SG_ VCLEFT_hvacBlowerRPMTarget m0: 10|10@1+ (10,0) [0|0] "rpm" X
 SG_ VCLEFT_hvacBlowerRPMActual m0: 20|10@1+ (10,0) [0|0] "rpm" X
 SG_ VCLEFT_hvacBlowerTorque m0: 34|8@1- (0.025,-1.5) [0|0] "Nm" X
 SG_ VCLEFT_hvacBlowerFETTemp m0: 42|8@1+ (1,-40) [0|0] "degC" X
 SG_ VCLEFT_hvacBlowerITerm m0: 50|8@1+ (0.025,-1.5) [0|0] "Nm" X
 SG_ VCLEFT_hvacBlowerInitd m0: 58|1@1+ (1,0) [0|0] "" X
 SG_ VCLEFT_hvacBlowerFault m0: 59|1@1+ (1,0) [0|0] "" X
 SG_ VCLEFT_hvacBlowerLimitFETTemps m0: 60|1@1+ (1,0) [0|0] "" X
 SG_ VCLEFT_hvacBlowerPowerOn m0: 61|1@1+ (1,0) [0|0] "" X
 SG_ VCLEFT_hvacBlowerSpiError m0: 62|1@1+ (1,0) [0|0] "" X
 SG_ VCLEFT_hvacBlowerRs m1: 2|8@1+ (0.0025,0) [0|0] "Ohm" X
 SG_ VCLEFT_hvacBlowerIPhase0 m1: 10|8@1+ (0.2,0) [0|0] "A" X
 SG_ VCLEFT_hvacBlowerIPhase1 m1: 18|8@1+ (0.2,0) [0|0] "A" X
 SG_ VCLEFT_hvacBlowerIPhase2 m1: 26|8@1+ (0.2,0) [0|0] "A" X

BO_ 770 VCLEFT_info: 8 Vector__XXX
 SG_ VCLEFT_infoComponentId m10 : 48|16@1+ (1,0) [0|0] "" Vector__XXX
 SG_ VCLEFT_infoSubUsageId m11 : 40|16@1+ (1,0) [0|0] "" Vector__XXX
 SG_ VCLEFT_infoCBCAppCRC m31 : 32|32@1+ (1,0) [0|0] "" Vector__XXX
 SG_ VCLEFT_infoHardwareId m10 : 32|16@1+ (1,0) [0|0] "" Vector__XXX
 SG_ VCLEFT_infoLUMBARLAppCRC m16 : 32|32@1+ (1,0) [0|0] "" Vector__XXX
 SG_ VCLEFT_infoRGBIPFLAppCRC m38 : 32|32@1+ (1,0) [0|0] "" Vector__XXX
 SG_ VCLEFT_infoRGBIPFRAppCRC m39 : 32|32@1+ (1,0) [0|0] "" Vector__XXX
 SG_ VCLEFT_infoSubcomponent3 m24 : 32|32@1+ (1,0) [0|0] "" Vector__XXX
 SG_ VCLEFT_infoTLCAppCRC m33 : 32|32@1+ (1,0) [0|0] "" Vector__XXX
 SG_ VCLEFT_infoVCUSBAppCRC m32 : 32|32@1+ (1,0) [0|0] "" Vector__XXX
 SG_ VCLEFT_swcAppCRC m23 : 32|32@1+ (1,0) [0|0] "" Vector__XXX
 SG_ VCLEFT_infoBootCrc m20 : 24|32@1+ (1,0) [0|0] "" Vector__XXX
 SG_ VCLEFT_infoUsageId m11 : 24|16@1+ (1,0) [0|0] "" Vector__XXX
 SG_ VCLEFT_infoAssemblyId m11 : 16|8@1+ (1,0) [0|0] "" Vector__XXX
 SG_ VCLEFT_infoBuildConfigId m10 : 16|16@1+ (1,0) [0|0] "" Vector__XXX
 SG_ VCLEFT_infoAppCrc m13 : 8|32@1+ (1,0) [0|0] "" Vector__XXX
 SG_ VCLEFT_infoAppGitHash m17 : 8|56@1+ (1,0) [0|0] "" Vector__XXX
 SG_ VCLEFT_infoBootGitHash m18 : 8|56@1+ (1,0) [0|0] "" Vector__XXX
 SG_ VCLEFT_infoBootUdsProtoVersion m20 : 8|16@1+ (1,0) [0|0] "" Vector__XXX
 SG_ VCLEFT_infoBuildType m10 : 8|3@1+ (1,0) [0|0] "" Vector__XXX
 SG_ VCLEFT_infoPcbaId m11 : 8|8@1+ (1,0) [0|0] "" Vector__XXX
 SG_ VCLEFT_infoPlatformType m19 : 8|8@1+ (1,0) [0|0] "" Vector__XXX
 SG_ VCLEFT_infoIndex M : 0|8@1+ (1,0) [0|0] "" Vector__XXX

BO_ 1860 VCLEFT_recallStatus: 1 VEH
 SG_ VCLEFT_columnRecallStatus: 4|2@1+ (1,0) [0|0] "" X
 SG_ VCLEFT_mirrorRecallStatus: 6|2@1+ (1,0) [0|0] "" X
 SG_ VCLEFT_seatRecallStatus: 2|2@1+ (1,0) [0|0] "" X
 SG_ VCLEFT_systemRecallStatus: 0|2@1+ (1,0) [0|0] "" X

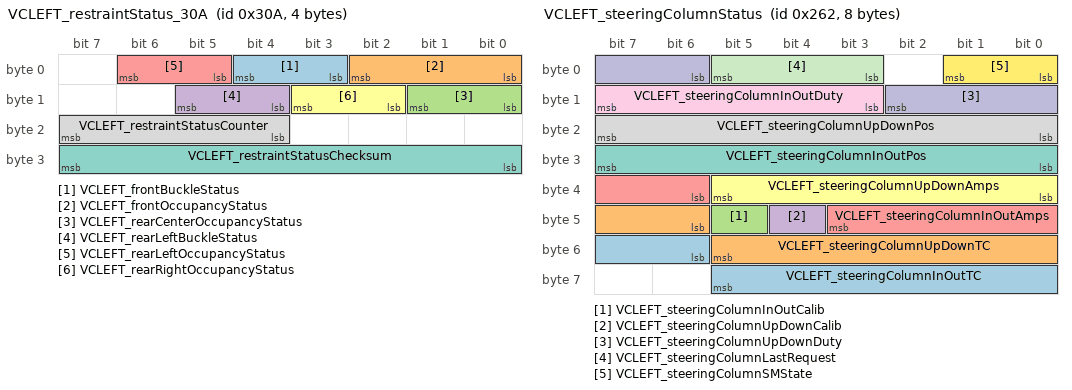
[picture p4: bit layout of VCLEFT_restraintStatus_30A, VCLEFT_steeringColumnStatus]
BO_ 778 VCLEFT_restraintStatus_30A: 4 VEH
 SG_ VCLEFT_frontBuckleStatus: 3|2@1+ (1,0) [0|0] "" X
 SG_ VCLEFT_frontOccupancyStatus: 0|3@1+ (1,0) [0|0] "" X
 SG_ VCLEFT_rearCenterOccupancyStatus: 8|2@1+ (1,0) [0|0] "" X
 SG_ VCLEFT_rearLeftBuckleStatus: 12|2@1+ (1,0) [0|0] "" X
 SG_ VCLEFT_rearLeftOccupancyStatus: 5|2@1+ (1,0) [0|0] "" X
 SG_ VCLEFT_rearRightOccupancyStatus: 10|2@1+ (1,0) [0|0] "" X
 SG_ VCLEFT_restraintStatusChecksum: 24|8@1+ (1,0) [0|0] "" X
 SG_ VCLEFT_restraintStatusCounter: 20|4@1+ (1,0) [0|0] "" X

BO_ 1250 VCLEFT_seatStatus: 8 Vector__XXX
 SG_ VCLEFT_lumbarDevMaxPumpPressB m4 : 60|1@1+ (1,0) [0|0] "" Vector__XXX
 SG_ VCLEFT_lumbarDevMaxPumpPressA m4 : 59|1@1+ (1,0) [0|0] "" Vector__XXX
 SG_ VCLEFT_lumbarGeneralErr m4 : 58|1@1+ (1,0) [0|0] "" Vector__XXX
 SG_ VCLEFT_lumbarMinPErr m4 : 57|1@1+ (1,0) [0|0] "" Vector__XXX
 SG_ VCLEFT_lumbarMaxOperatingPErr m4 : 56|1@1+ (1,0) [0|0] "" Vector__XXX
 SG_ VCLEFT_frontSeatBackPercentage m1 : 55|7@1+ (1,0) [0|0] "" Vector__XXX
 SG_ VCLEFT_frontSeatLiftPercentage m2 : 55|7@1+ (1,0) [0|0] "" Vector__XXX
 SG_ VCLEFT_frontSeatTiltPercentage m3 : 55|7@1+ (1,0) [0|0] "" Vector__XXX
 SG_ VCLEFT_frontSeatTrackPercentage m0 : 55|7@1+ (1,0) [0|0] "" Vector__XXX
 SG_ VCLEFT_lumbarOvercurrentErr m4 : 55|1@1+ (1,0) [0|0] "" Vector__XXX
 SG_ VCLEFT_lumbarMaxPErr m4 : 54|1@1+ (1,0) [0|0] "" Vector__XXX
 SG_ VCLEFT_frontSeatBackBridgeSt m1 : 53|2@1+ (1,0) [0|0] "" Vector__XXX
 SG_ VCLEFT_frontSeatLiftBridgeSt m2 : 53|2@1+ (1,0) [0|0] "" Vector__XXX
 SG_ VCLEFT_frontSeatTiltBridgeSt m3 : 53|2@1+ (1,0) [0|0] "" Vector__XXX
 SG_ VCLEFT_frontSeatTrackBridgeSt m0 : 53|2@1+ (1,0) [0|0] "" Vector__XXX
 SG_ VCLEFT_lumbarActiveTooLongErr m4 : 53|1@1+ (1,0) [0|0] "" Vector__XXX
 SG_ VCLEFT_frontSeatBackLog m1 : 52|1@1+ (1,0) [0|0] "" Vector__XXX
 SG_ VCLEFT_frontSeatLiftLog m2 : 52|1@1+ (1,0) [0|0] "" Vector__XXX
 SG_ VCLEFT_frontSeatTiltLog m3 : 52|1@1+ (1,0) [0|0] "" Vector__XXX
 SG_ VCLEFT_frontSeatTrackLog m0 : 52|1@1+ (1,0) [0|0] "" Vector__XXX
 SG_ VCLEFT_frontSeatBackCalibrated m1 : 51|1@1+ (1,0) [0|0] "" Vector__XXX
 SG_ VCLEFT_frontSeatLiftCalibrated m2 : 51|1@1+ (1,0) [0|0] "" Vector__XXX
 SG_ VCLEFT_frontSeatTiltCalibrated m3 : 51|1@1+ (1,0) [0|0] "" Vector__XXX
 SG_ VCLEFT_frontSeatTrackCalibrated m0 : 51|1@1+ (1,0) [0|0] "" Vector__XXX
 SG_ VCLEFT_frontSeatBackState m1 : 48|3@1+ (1,0) [0|0] "" Vector__XXX
 SG_ VCLEFT_frontSeatLiftState m2 : 48|3@1+ (1,0) [0|0] "" Vector__XXX
 SG_ VCLEFT_frontSeatTiltState m3 : 48|3@1+ (1,0) [0|0] "" Vector__XXX
 SG_ VCLEFT_frontSeatTrackState m0 : 48|3@1+ (1,0) [0|0] "" Vector__XXX
 SG_ VCLEFT_lumbarBPressureHpaFilt m4 : 43|10@1+ (1,0) [0|0] "" Vector__XXX
 SG_ VCLEFT_frontSeatTiltPosOffset m6 : 40|12@1- (0.1,0) [0|0] "" Vector__XXX
 SG_ VCLEFT_frontSeatTiltPosReal m5 : 40|12@1- (0.1,0) [0|0] "" Vector__XXX
 SG_ VCLEFT_frontSeatBackDuty m1 : 36|12@1- (0.1,0) [0|0] "" Vector__XXX
 SG_ VCLEFT_frontSeatLiftDuty m2 : 36|12@1- (0.1,0) [0|0] "" Vector__XXX
 SG_ VCLEFT_frontSeatTiltDuty m3 : 36|12@1- (0.1,0) [0|0] "" Vector__XXX
 SG_ VCLEFT_frontSeatTrackDuty m0 : 36|12@1- (0.1,0) [0|0] "" Vector__XXX
 SG_ VCLEFT_lumbarBPressureHpa m4 : 31|12@1+ (1,0) [0|0] "" Vector__XXX
 SG_ VCLEFT_frontSeatLiftPosOffset m6 : 28|12@1- (1,0) [0|0] "" Vector__XXX
 SG_ VCLEFT_frontSeatLiftPosReal m5 : 28|12@1- (1,0) [0|0] "" Vector__XXX
 SG_ VCLEFT_frontSeatBackCurrent m1 : 24|12@1- (0.01,0) [0|0] "" Vector__XXX
 SG_ VCLEFT_frontSeatLiftCurrent m2 : 24|12@1- (0.01,0) [0|0] "" Vector__XXX
 SG_ VCLEFT_frontSeatTiltCurrent m3 : 24|12@1- (0.01,0) [0|0] "" Vector__XXX
 SG_ VCLEFT_frontSeatTrackCurrent m0 : 24|12@1- (0.01,0) [0|0] "" Vector__XXX
 SG_ VCLEFT_lumbarAPressureHpaFilt m4 : 21|10@1+ (1,0) [0|0] "" Vector__XXX
 SG_ VCLEFT_frontSeatBackPosOffset m6 : 16|12@1- (0.1,0) [0|0] "" Vector__XXX
 SG_ VCLEFT_frontSeatBackPosReal m5 : 16|12@1- (0.1,0) [0|0] "" Vector__XXX
 SG_ VCLEFT_lumbarBPressurePercentage m7 : 10|7@1+ (1,0) [0|0] "" Vector__XXX
 SG_ VCLEFT_lumbarAPressureHpa m4 : 9|12@1+ (1,0) [0|0] "" Vector__XXX
 SG_ VCLEFT_frontSeatBackPos m1 : 8|16@1- (1,0) [0|0] "" Vector__XXX
 SG_ VCLEFT_frontSeatLiftPos m2 : 8|16@1- (1,0) [0|0] "" Vector__XXX
 SG_ VCLEFT_frontSeatTiltPos m3 : 8|16@1- (1,0) [0|0] "" Vector__XXX
 SG_ VCLEFT_frontSeatTrackPos m0 : 8|16@1- (1,0) [0|0] "" Vector__XXX
 SG_ VCLEFT_lumbarBState m4 : 6|3@1+ (1,0) [0|0] "" Vector__XXX
 SG_ VC_AH_1RowLeftSeatMovementHealth m0 : 5|3@1+ (1,0) [0|0] "" Vector__XXX
 SG_ VCLEFT_frontSeatTrackPosOffset m6 : 3|12@1- (1,0) [0|0] "" Vector__XXX
 SG_ VCLEFT_frontSeatTrackPosReal m5 : 3|12@1- (1,0) [0|0] "" Vector__XXX
 SG_ VCLEFT_lumbarAPressurePercentage m7 : 3|7@1+ (1,0) [0|0] "" Vector__XXX
 SG_ VCLEFT_lumbarAState m4 : 3|3@1+ (1,0) [0|0] "" Vector__XXX
 SG_ VCLEFT_seatStatusIndex M : 0|3@1+ (1,0) [0|0] "" Vector__XXX

BO_ 930 VCLEFT_status: 8 VEH
 SG_ VCLEFT_statusIndex M: 0|1@1+ (1,0) [0|0] "" X
 SG_ VCLEFT_loadShedPriority m0: 1|8@1+ (1,0) [0|0] "" X
 SG_ VCLEFT_vehiclePowerStateDBG m0: 9|2@1+ (1,0) [0|0] "" X
 SG_ VCLEFT_consoleDoorAssist m0: 11|1@1+ (1,0) [0|0] "" X
 SG_ VCLEFT_OTAState m0: 12|1@1+ (1,0) [0|0] "" X
 SG_ VCLEFT_5AVoltage m0: 13|10@1+ (0.00544368,0) [0|0] "V" X
 SG_ VCLEFT_vbatProt m0: 23|12@1+ (0.00544368,0) [0|0] "V" X
 SG_ VCLEFT_footwellLightCurrent m0: 35|12@1- (0.1,0) [0|0] "mA" X
 SG_ VCLEFT_swcInputVoltage m0: 47|8@1+ (0.1,0) [0|0] "V" X
 SG_ VCLEFT_swcPCBATemperature m0: 55|8@1- (1,-40) [0|0] "degC" X
 SG_ VCLEFT_pcbaTemperature m1: 1|11@1+ (0.125,-40) [0|0] "degC" X
 SG_ VCLEFT_DIeFuseCurrent m1: 12|12@1- (0.1,0) [0|0] "A" X
 SG_ VCLEFT_DIeFuseFault m1: 24|1@1+ (1,0) [0|0] "" X
 SG_ VCLEFT_tlcPCBATemperature m1: 32|8@1- (1,-40) [0|0] "degC" X

BO_ 610 VCLEFT_steeringColumnStatus: 8 Vector__XXX
 SG_ VCLEFT_steeringColumnInOutTC : 54|8@1+ (0.5,-10) [0|0] "" Vector__XXX
 SG_ VCLEFT_steeringColumnUpDownTC : 46|8@1+ (0.5,-10) [0|0] "" Vector__XXX
 SG_ VCLEFT_steeringColumnInOutCalib : 45|1@1+ (1,0) [0|0] "" Vector__XXX
 SG_ VCLEFT_steeringColumnUpDownCalib : 44|1@1+ (1,0) [0|0] "" Vector__XXX
 SG_ VCLEFT_steeringColumnInOutAmps : 38|6@1- (0.63,0) [0|0] "" Vector__XXX
 SG_ VCLEFT_steeringColumnUpDownAmps : 32|6@1- (0.63,0) [0|0] "" Vector__XXX
 SG_ VCLEFT_steeringColumnInOutPos : 24|8@1- (1,103) [0|0] "" Vector__XXX
 SG_ VCLEFT_steeringColumnUpDownPos : 16|8@1- (1,103) [0|0] "" Vector__XXX
 SG_ VCLEFT_steeringColumnInOutDuty : 11|5@1- (7,0) [0|0] "" Vector__XXX
 SG_ VCLEFT_steeringColumnUpDownDuty : 6|5@1- (7,0) [0|0] "" Vector__XXX
 SG_ VCLEFT_steeringColumnLastRequest : 3|3@1+ (1,0) [0|0] "" Vector__XXX
 SG_ VCLEFT_steeringColumnSMState : 0|2@1+ (1,0) [0|0] "" Vector__XXX

BO_ 962 VCLEFT_switchStatus: 8 VEH
 SG_ VCLEFT_switchStatusIndex M : 0|2@1+ (1,0) [0|2] "" X
 SG_ VCLEFT_2RowSeatBothFoldFlatSwitc m1 : 40|1@1+ (1,0) [0|1] "" X
 SG_ VCLEFT_2RowSeatCenterSwitch m1 : 37|1@1+ (1,0) [0|1] "" X
 SG_ VCLEFT_2RowSeatLeftFoldFlatSwitc m1 : 38|1@1+ (1,0) [0|1] "" X
 SG_ VCLEFT_2RowSeatReclineSwitch m1 : 36|1@1+ (1,0) [0|1] "" X
 SG_ VCLEFT_2RowSeatRightFoldFlatSwit m1 : 39|1@1+ (1,0) [0|1] "" X
 SG_ VCLEFT_brakePressed m0 : 60|1@1+ (1,0) [0|1] "" X
 SG_ VCLEFT_brakeSwitchPressed m0 : 4|1@1+ (1,0) [0|1] "" X
 SG_ VCLEFT_btnWindowAutoDownLR m1 : 35|1@1+ (1,0) [0|1] "" X
 SG_ VCLEFT_btnWindowAutoUpLR m1 : 33|1@1+ (1,0) [0|1] "" X
 SG_ VCLEFT_btnWindowDownLR m1 : 34|1@1+ (1,0) [0|1] "" X
 SG_ VCLEFT_btnWindowSwPackAutoDownLF m0 : 35|1@1+ (1,0) [0|1] "" X
 SG_ VCLEFT_btnWindowSwPackAutoDownLR m0 : 39|1@1+ (1,0) [0|1] "" X
 SG_ VCLEFT_btnWindowSwPackAutoDownRF m0 : 43|1@1+ (1,0) [0|1] "" X
 SG_ VCLEFT_btnWindowSwPackAutoDownRR m0 : 47|1@1+ (1,0) [0|1] "" X
 SG_ VCLEFT_btnWindowSwPackAutoUpLF m0 : 33|1@1+ (1,0) [0|1] "" X
 SG_ VCLEFT_btnWindowSwPackAutoUpLR m0 : 37|1@1+ (1,0) [0|1] "" X
 SG_ VCLEFT_btnWindowSwPackAutoUpRF m0 : 41|1@1+ (1,0) [0|1] "" X
 SG_ VCLEFT_btnWindowSwPackAutoUpRR m0 : 45|1@1+ (1,0) [0|1] "" X
 SG_ VCLEFT_btnWindowSwPackDownLF m0 : 34|1@1+ (1,0) [0|1] "" X
 SG_ VCLEFT_btnWindowSwPackDownLR m0 : 38|1@1+ (1,0) [0|1] "" X
 SG_ VCLEFT_btnWindowSwPackDownRF m0 : 42|1@1+ (1,0) [0|1] "" X
 SG_ VCLEFT_btnWindowSwPackDownRR m0 : 46|1@1+ (1,0) [0|1] "" X
 SG_ VCLEFT_btnWindowSwPackUpLF m0 : 32|1@1+ (1,0) [0|1] "" X
 SG_ VCLEFT_btnWindowSwPackUpLR m0 : 36|1@1+ (1,0) [0|1] "" X
 SG_ VCLEFT_btnWindowSwPackUpRF m0 : 40|1@1+ (1,0) [0|1] "" X
 SG_ VCLEFT_btnWindowSwPackUpRR m0 : 44|1@1+ (1,0) [0|1] "" X
 SG_ VCLEFT_btnWindowUpLR m1 : 32|1@1+ (1,0) [0|1] "" X
 SG_ VCLEFT_frontBuckleSwitch m0 : 48|2@1+ (1,0) [0|3] "" X
 SG_ VCLEFT_frontOccupancySwitch m0 : 50|2@1+ (1,0) [0|3] "" X
 SG_ VCLEFT_frontSeatBackrestBack m0 : 20|2@1+ (1,0) [0|3] "" X
 SG_ VCLEFT_frontSeatBackrestForward m0 : 22|2@1+ (1,0) [0|3] "" X
 SG_ VCLEFT_frontSeatLiftDown m0 : 16|2@1+ (1,0) [0|3] "" X
 SG_ VCLEFT_frontSeatLiftUp m0 : 18|2@1+ (1,0) [0|3] "" X
 SG_ VCLEFT_frontSeatLumbarDown m0 : 24|2@1+ (1,0) [0|3] "" X
 SG_ VCLEFT_frontSeatLumbarIn m0 : 28|2@1+ (1,0) [0|3] "" X
 SG_ VCLEFT_frontSeatLumbarOut m0 : 30|2@1+ (1,0) [0|3] "" X
 SG_ VCLEFT_frontSeatLumbarUp m0 : 26|2@1+ (1,0) [0|3] "" X
 SG_ VCLEFT_frontSeatTiltDown m0 : 12|2@1+ (1,0) [0|3] "" X
 SG_ VCLEFT_frontSeatTiltUp m0 : 14|2@1+ (1,0) [0|3] "" X
 SG_ VCLEFT_frontSeatTrackBack m0 : 8|2@1+ (1,0) [0|3] "" X
 SG_ VCLEFT_frontSeatTrackForward m0 : 10|2@1+ (1,0) [0|3] "" X
 SG_ VCLEFT_hazardButtonPressed m0 : 3|1@1+ (1,0) [0|1] "" X
 SG_ VCLEFT_hornSwitchPressed m0 : 2|1@1+ (1,0) [0|1] "" X
 SG_ VCLEFT_rearCenterBuckleSwitch m0 : 62|2@1+ (1,0) [0|3] "" X
 SG_ VCLEFT_rearCenterOccupancySwitch m0 : 54|2@1+ (1,0) [0|3] "" X
 SG_ VCLEFT_rearHVACButtonPressed m0 : 61|1@1+ (1,0) [0|1] "" X
 SG_ VCLEFT_rearLeftBuckleSwitch m0 : 52|2@1+ (1,0) [0|3] "" X
 SG_ VCLEFT_rearLeftOccupancySwitch m0 : 56|2@1+ (1,0) [0|3] "" X
 SG_ VCLEFT_rearRightOccupancySwitch m0 : 58|2@1+ (1,0) [0|3] "" X
 SG_ VCLEFT_rightMirrorTilt m0 : 5|3@1+ (1,0) [0|4] "" X
 SG_ VCLEFT_swcLeftDoublePress m1 : 41|1@1+ (1,0) [0|1] "" X
 SG_ VCLEFT_swcLeftPressed m1 : 5|2@1+ (1,0) [0|3] "" X
 SG_ VCLEFT_swcLeftScrollTicks m1 : 16|6@1- (1,0) [-32|31] "" X
 SG_ VCLEFT_swcLeftTiltLeft m1 : 14|2@1+ (1,0) [0|3] "" X
 SG_ VCLEFT_swcLeftTiltRight m1 : 3|2@1+ (1,0) [0|3] "" X
 SG_ VCLEFT_swcRightDoublePress m1 : 42|1@1+ (1,0) [0|1] "" X
 SG_ VCLEFT_swcRightPressed m1 : 12|2@1+ (1,0) [0|3] "" X
 SG_ VCLEFT_swcRightScrollTicks m1 : 24|6@1- (1,0) [-32|31] "" X
 SG_ VCLEFT_swcRightTiltLeft m1 : 8|2@1+ (1,0) [0|3] "" X
 SG_ VCLEFT_swcRightTiltRight m1 : 10|2@1+ (1,0) [0|3] "" X

BO_ 960 VCRIGHT_alertMatrix: 8 VEH
 SG_ VCRIGHT_matrixIndex M: 0|4@1+ (1,0) [0|0] "" X
 SG_ VCRIGHT_a001_WatchdogReset m0: 4|1@1+ (1,0) [0|0] "" X
 SG_ VCRIGHT_a002_PowerLossReset m0: 5|1@1+ (1,0) [0|0] "" X
 SG_ VCRIGHT_a003_SWAssertion m0: 6|1@1+ (1,0) [0|0] "" X
 SG_ VCRIGHT_a010_ExtSupplyVoltError m0: 13|1@1+ (1,0) [0|0] "" X
 SG_ VCRIGHT_a012_CPUReset m0: 15|1@1+ (1,0) [0|0] "" X
 SG_ VCRIGHT_a013_AlertManagerFault m0: 16|1@1+ (1,0) [0|0] "" X
 SG_ VCRIGHT_a015_NVMMAlert m0: 18|1@1+ (1,0) [0|0] "" X
 SG_ VCRIGHT_a021_TaskSchedulerError m0: 24|1@1+ (1,0) [0|0] "" X
 SG_ VCRIGHT_a022_TaskInitError m0: 25|1@1+ (1,0) [0|0] "" X
 SG_ VCRIGHT_a031_UDSActive m0: 34|1@1+ (1,0) [0|0] "" X
 SG_ VCRIGHT_a041_HighCPULoad m0: 44|1@1+ (1,0) [0|0] "" X
 SG_ VCRIGHT_a042_HighStackUsage m0: 45|1@1+ (1,0) [0|0] "" X
 SG_ VCRIGHT_a043_Task1msError m0: 46|1@1+ (1,0) [0|0] "" X
 SG_ VCRIGHT_a044_Task10msError m0: 47|1@1+ (1,0) [0|0] "" X
 SG_ VCRIGHT_a045_Task100msError m0: 48|1@1+ (1,0) [0|0] "" X
 SG_ VCRIGHT_a046_Task1000msError m0: 49|1@1+ (1,0) [0|0] "" X
 SG_ VCRIGHT_a059_inputResistanceHigh m0: 62|1@1+ (1,0) [0|0] "" X
 SG_ VCRIGHT_a060_engineeringBuild m0: 63|1@1+ (1,0) [0|0] "" X
 SG_ VCRIGHT_a061_XCPConnected m1: 4|1@1+ (1,0) [0|0] "" X
 SG_ VCRIGHT_a062_XCPWasConnected m1: 5|1@1+ (1,0) [0|0] "" X
 SG_ VCRIGHT_a063_SwitchFault m1: 6|1@1+ (1,0) [0|0] "" X
 SG_ VCRIGHT_a064_busSleepReqTimeout m1: 7|1@1+ (1,0) [0|0] "" X
 SG_ VCRIGHT_a097_CMP_MIA m1: 40|1@1+ (1,0) [0|0] "" X
 SG_ VCRIGHT_a098_DI_THERMAL_MIA m1: 41|1@1+ (1,0) [0|0] "" X
 SG_ VCRIGHT_a099_PARK_MIA m1: 42|1@1+ (1,0) [0|0] "" X
 SG_ VCRIGHT_a100_CANbus_MIA m1: 43|1@1+ (1,0) [0|0] "" X
 SG_ VCRIGHT_a101_PM_MIA m1: 44|1@1+ (1,0) [0|0] "" X
 SG_ VCRIGHT_a102_PTC_MIA m1: 45|1@1+ (1,0) [0|0] "" X
 SG_ VCRIGHT_a103_CP_MIA m1: 46|1@1+ (1,0) [0|0] "" X
 SG_ VCRIGHT_a104_DAS_MIA m1: 47|1@1+ (1,0) [0|0] "" X
 SG_ VCRIGHT_a105_TAS_MIA m1: 48|1@1+ (1,0) [0|0] "" X
 SG_ VCRIGHT_a106_PCS_MIA m1: 49|1@1+ (1,0) [0|0] "" X
 SG_ VCRIGHT_a107_BMS_MIA m1: 50|1@1+ (1,0) [0|0] "" X
 SG_ VCRIGHT_a108_DIS_MIA m1: 51|1@1+ (1,0) [0|0] "" X
 SG_ VCRIGHT_a109_RCM_MIA m1: 52|1@1+ (1,0) [0|0] "" X
 SG_ VCRIGHT_a110_GTW_MIA m1: 53|1@1+ (1,0) [0|0] "" X
 SG_ VCRIGHT_a111_EPBR_MIA m1: 54|1@1+ (1,0) [0|0] "" X
 SG_ VCRIGHT_a112_EPBL_MIA m1: 55|1@1+ (1,0) [0|0] "" X
 SG_ VCRIGHT_a113_UI_MIA m1: 56|1@1+ (1,0) [0|0] "" X
 SG_ VCRIGHT_a114_ESP_MIA m1: 57|1@1+ (1,0) [0|0] "" X
 SG_ VCRIGHT_a115_VCSEC_MIA m1: 58|1@1+ (1,0) [0|0] "" X
 SG_ VCRIGHT_a116_VCRIGHT_MIA m1: 59|1@1+ (1,0) [0|0] "" X
 SG_ VCRIGHT_a117_VCLEFT_MIA m1: 60|1@1+ (1,0) [0|0] "" X
 SG_ VCRIGHT_a118_VCFRONT_MIA m1: 61|1@1+ (1,0) [0|0] "" X
 SG_ VCRIGHT_a119_SCCM_MIA m1: 62|1@1+ (1,0) [0|0] "" X
 SG_ VCRIGHT_a120_DI_DRIVE_MIA m1: 63|1@1+ (1,0) [0|0] "" X
 SG_ VCRIGHT_a129_hvacIntakeUncalib m2: 12|1@1+ (1,0) [0|0] "" X
 SG_ VCRIGHT_a130_hvacLHBleedUncalib m2: 13|1@1+ (1,0) [0|0] "" X
 SG_ VCRIGHT_a131_hvacRHBleedUncalib m2: 14|1@1+ (1,0) [0|0] "" X
 SG_ VCRIGHT_a132_hvacLHVaneUncalib m2: 15|1@1+ (1,0) [0|0] "" X
 SG_ VCRIGHT_a133_hvacRHVaneUncalib m2: 16|1@1+ (1,0) [0|0] "" X
 SG_ VCRIGHT_a134_hvacUpprModeUncalib m2: 17|1@1+ (1,0) [0|0] "" X
 SG_ VCRIGHT_a135_hvacLowrModeUncalib m2: 18|1@1+ (1,0) [0|0] "" X
 SG_ VCRIGHT_a136_hvacIntakeFault m2: 19|1@1+ (1,0) [0|0] "" X
 SG_ VCRIGHT_a137_hvacLHBleedFault m2: 20|1@1+ (1,0) [0|0] "" X
 SG_ VCRIGHT_a138_hvacRHBleedFault m2: 21|1@1+ (1,0) [0|0] "" X
 SG_ VCRIGHT_a139_hvacLHVaneFault m2: 22|1@1+ (1,0) [0|0] "" X
 SG_ VCRIGHT_a140_hvacRHVaneFault m2: 23|1@1+ (1,0) [0|0] "" X
 SG_ VCRIGHT_a141_hvacUpperModeFault m2: 24|1@1+ (1,0) [0|0] "" X
 SG_ VCRIGHT_a142_hvacLowerModeFault m2: 25|1@1+ (1,0) [0|0] "" X
 SG_ VCRIGHT_a144_evaporatorTempSns m2: 27|1@1+ (1,0) [0|0] "" X
 SG_ VCRIGHT_a145_ductLeftTempSns m2: 28|1@1+ (1,0) [0|0] "" X
 SG_ VCRIGHT_a146_ductRightTempSns m2: 29|1@1+ (1,0) [0|0] "" X
 SG_ VCRIGHT_a147_incarProbeTempSns m2: 30|1@1+ (1,0) [0|0] "" X
 SG_ VCRIGHT_a148_incarMidTempSns m2: 31|1@1+ (1,0) [0|0] "" X
 SG_ VCRIGHT_a149_incarDeepTempSns m2: 32|1@1+ (1,0) [0|0] "" X
 SG_ VCRIGHT_a150_windowPinchFront m2: 33|1@1+ (1,0) [0|0] "" X
 SG_ VCRIGHT_a151_windowPinchRear m2: 34|1@1+ (1,0) [0|0] "" X
 SG_ VCRIGHT_a152_windowUncalFront m2: 35|1@1+ (1,0) [0|0] "" X
 SG_ VCRIGHT_a153_windowUncalRear m2: 36|1@1+ (1,0) [0|0] "" X
 SG_ VCRIGHT_a154_windowThermalFront m2: 37|1@1+ (1,0) [0|0] "" X
 SG_ VCRIGHT_a155_windowThermalRear m2: 38|1@1+ (1,0) [0|0] "" X
 SG_ VCRIGHT_a156_windowNoInputFront m2: 39|1@1+ (1,0) [0|0] "" X
 SG_ VCRIGHT_a157_windowNoInputRear m2: 40|1@1+ (1,0) [0|0] "" X
 SG_ VCRIGHT_a158_windowPinchOverideF m2: 41|1@1+ (1,0) [0|0] "" X
 SG_ VCRIGHT_a159_windowPinchOverideR m2: 42|1@1+ (1,0) [0|0] "" X
 SG_ VCRIGHT_a160_windowUndercurrentF m2: 43|1@1+ (1,0) [0|0] "" X
 SG_ VCRIGHT_a161_windowUndercurrentR m2: 44|1@1+ (1,0) [0|0] "" X
 SG_ VCRIGHT_a162_windowEncoderStallF m2: 45|1@1+ (1,0) [0|0] "" X
 SG_ VCRIGHT_a163_windowEncoderStallR m2: 46|1@1+ (1,0) [0|0] "" X
 SG_ VCRIGHT_a164_windowFactoryTest m2: 47|1@1+ (1,0) [0|0] "" X
 SG_ VCRIGHT_a165_windowFactoryTest2 m2: 48|1@1+ (1,0) [0|0] "" X
 SG_ VCRIGHT_a166_windowDebug m2: 49|1@1+ (1,0) [0|0] "" X
 SG_ VCRIGHT_a167_windowDebugPinchF m2: 50|1@1+ (1,0) [0|0] "" X
 SG_ VCRIGHT_a168_windowDebugPinchR m2: 51|1@1+ (1,0) [0|0] "" X
 SG_ VCRIGHT_a169_windowCurrentPeakF m2: 52|1@1+ (1,0) [0|0] "" X
 SG_ VCRIGHT_a170_windowCurrentPeakR m2: 53|1@1+ (1,0) [0|0] "" X
 SG_ VCRIGHT_a172_SPI_MIA m2: 55|1@1+ (1,0) [0|0] "" X
 SG_ VCRIGHT_a174_BLERightPowerCycled m2: 57|1@1+ (1,0) [0|0] "" X
 SG_ VCRIGHT_a180_frontDoorLatchRehome m2: 63|1@1+ (1,0) [0|0] "" X
 SG_ VCRIGHT_a181_rearDoorLatchRehome m3: 4|1@1+ (1,0) [0|0] "" X
 SG_ VCRIGHT_a182_emergencyLatchRel m3: 5|1@1+ (1,0) [0|0] "" X
 SG_ VCRIGHT_a183_doorStateFactoryTest m3: 6|1@1+ (1,0) [0|0] "" X
 SG_ VCRIGHT_a184_trunkFailedOpening m3: 7|1@1+ (1,0) [0|0] "" X
 SG_ VCRIGHT_a185_summonAborted m3: 8|1@1+ (1,0) [0|0] "" X
 SG_ VCRIGHT_a186_latchReleaseFailedF m3: 9|1@1+ (1,0) [0|0] "" X
 SG_ VCRIGHT_a187_latchReleaseFailedR m3: 10|1@1+ (1,0) [0|0] "" X
 SG_ VCRIGHT_a188_latchUnableToRearmF m3: 11|1@1+ (1,0) [0|0] "" X
 SG_ VCRIGHT_a189_latchUnableToRearmR m3: 12|1@1+ (1,0) [0|0] "" X
 SG_ VCRIGHT_a190_eFuseMgmtVbatFused m3: 13|1@1+ (1,0) [0|0] "" X
 SG_ VCRIGHT_a191_gloveboxPower m3: 14|1@1+ (1,0) [0|0] "" X
 SG_ VCRIGHT_a192_gloveboxLatchRel m3: 15|1@1+ (1,0) [0|0] "" X
 SG_ VCRIGHT_a193_amplifierEFuseFault m3: 16|1@1+ (1,0) [0|0] "" X
 SG_ VCRIGHT_a194_cntctrPwrEFuseFault m3: 17|1@1+ (1,0) [0|0] "" X
 SG_ VCRIGHT_a195_hvcEFuseFault m3: 18|1@1+ (1,0) [0|0] "" X
 SG_ VCRIGHT_a196_VEHCANOverterminate m3: 19|1@1+ (1,0) [0|0] "" X
 SG_ VCRIGHT_a197_VEHCANUndertrminate m3: 20|1@1+ (1,0) [0|0] "" X
 SG_ VCRIGHT_a198_PRVCANOverterminate m3: 21|1@1+ (1,0) [0|0] "" X
 SG_ VCRIGHT_a199_PRVCANUndertrminate m3: 22|1@1+ (1,0) [0|0] "" X
 SG_ VCRIGHT_a200_motorPhantomEncoder m3: 23|1@1+ (1,0) [0|0] "" X
 SG_ VCRIGHT_a201_motorDutyEncDisabl m3: 24|1@1+ (1,0) [0|0] "" X
 SG_ VCRIGHT_a202_epbmUnderIStatic m3: 25|1@1+ (1,0) [0|0] "" X
 SG_ VCRIGHT_a203_epbmOverIStatic m3: 26|1@1+ (1,0) [0|0] "" X
 SG_ VCRIGHT_a204_epbmUnderIDyn m3: 27|1@1+ (1,0) [0|0] "" X
 SG_ VCRIGHT_a205_epbmOverIDyn m3: 28|1@1+ (1,0) [0|0] "" X
 SG_ VCRIGHT_a206_epbWrongDirection m3: 29|1@1+ (1,0) [0|0] "" X
 SG_ VCRIGHT_a207_epbmEnableWrong m3: 30|1@1+ (1,0) [0|0] "" X
 SG_ VCRIGHT_a208_epbFaulted m3: 31|1@1+ (1,0) [0|0] "" X
 SG_ VCRIGHT_a209_epbStateMisTime m3: 32|1@1+ (1,0) [0|0] "" X
 SG_ VCRIGHT_a210_epbStateTime m3: 33|1@1+ (1,0) [0|0] "" X
 SG_ VCRIGHT_a211_epbmUnderIStaticNew m3: 34|1@1+ (1,0) [0|0] "" X
 SG_ VCRIGHT_a212_epbmOverIStaticNew m3: 35|1@1+ (1,0) [0|0] "" X
 SG_ VCRIGHT_a213_epbmUnderIDynNew m3: 36|1@1+ (1,0) [0|0] "" X
 SG_ VCRIGHT_a214_epbmOverIDynNew m3: 37|1@1+ (1,0) [0|0] "" X
 SG_ VCRIGHT_a215_currentDesyncWarning m3: 38|1@1+ (1,0) [0|0] "" X
 SG_ VCRIGHT_a216_SPI_MIA_debugData1 m3: 39|1@1+ (1,0) [0|0] "" X
 SG_ VCRIGHT_a217_SPI_MIA_debugData2 m3: 40|1@1+ (1,0) [0|0] "" X
 SG_ VCRIGHT_a218_motorDriverFault m3: 41|1@1+ (1,0) [0|0] "" X
 SG_ VCRIGHT_a219_motorCurrentDropout m3: 42|1@1+ (1,0) [0|0] "" X
 SG_ VCRIGHT_a220_seatCurrStallTrack m3: 43|1@1+ (1,0) [0|0] "" X
 SG_ VCRIGHT_a221_seatCurrStallBack m3: 44|1@1+ (1,0) [0|0] "" X
 SG_ VCRIGHT_a222_seatCurrStallTilt m3: 45|1@1+ (1,0) [0|0] "" X
 SG_ VCRIGHT_a223_seatCurrStallLift m3: 46|1@1+ (1,0) [0|0] "" X
 SG_ VCRIGHT_a224_seatEncStallTrack m3: 47|1@1+ (1,0) [0|0] "" X
 SG_ VCRIGHT_a225_seatEncStallBack m3: 48|1@1+ (1,0) [0|0] "" X
 SG_ VCRIGHT_a226_seatEncStallTilt m3: 49|1@1+ (1,0) [0|0] "" X
 SG_ VCRIGHT_a227_seatEncStallLift m3: 50|1@1+ (1,0) [0|0] "" X
 SG_ VCRIGHT_a228_seatEncOverTrack m3: 51|1@1+ (1,0) [0|0] "" X
 SG_ VCRIGHT_a229_seatEncOverBack m3: 52|1@1+ (1,0) [0|0] "" X
 SG_ VCRIGHT_a230_seatEncOverTilt m3: 53|1@1+ (1,0) [0|0] "" X
 SG_ VCRIGHT_a231_seatEncOverLift m3: 54|1@1+ (1,0) [0|0] "" X
 SG_ VCRIGHT_a232_seatCurrUnderTrack m3: 55|1@1+ (1,0) [0|0] "" X
 SG_ VCRIGHT_a233_seatCurrUnderBack m3: 56|1@1+ (1,0) [0|0] "" X
 SG_ VCRIGHT_a234_seatCurrUnderTilt m3: 57|1@1+ (1,0) [0|0] "" X
 SG_ VCRIGHT_a235_seatCurrUnderLift m3: 58|1@1+ (1,0) [0|0] "" X
 SG_ VCRIGHT_a236_lumbarOverPresA m3: 59|1@1+ (1,0) [0|0] "" X
 SG_ VCRIGHT_a237_lumbarOverPresB m3: 60|1@1+ (1,0) [0|0] "" X
 SG_ VCRIGHT_a238_lumbarValveMIA m3: 61|1@1+ (1,0) [0|0] "" X
 SG_ VCRIGHT_a239_seatHeatIFront m3: 62|1@1+ (1,0) [0|0] "" X
 SG_ VCRIGHT_a240_seatHeatShortFront m3: 63|1@1+ (1,0) [0|0] "" X
 SG_ VCRIGHT_a241_seatHeatMIAFront m4: 4|1@1+ (1,0) [0|0] "" X
 SG_ VCRIGHT_a242_seatHeatIRearL m4: 5|1@1+ (1,0) [0|0] "" X
 SG_ VCRIGHT_a243_seatHeatShortRearL m4: 6|1@1+ (1,0) [0|0] "" X
 SG_ VCRIGHT_a244_seatHeatMIARearL m4: 7|1@1+ (1,0) [0|0] "" X
 SG_ VCRIGHT_a245_seatHeatIRearC m4: 8|1@1+ (1,0) [0|0] "" X
 SG_ VCRIGHT_a246_seatHeatShortRearC m4: 9|1@1+ (1,0) [0|0] "" X
 SG_ VCRIGHT_a247_seatHeatMIARearC m4: 10|1@1+ (1,0) [0|0] "" X
 SG_ VCRIGHT_a248_seatHeatIRearR m4: 11|1@1+ (1,0) [0|0] "" X
 SG_ VCRIGHT_a249_seatHeatShortRearR m4: 12|1@1+ (1,0) [0|0] "" X
 SG_ VCRIGHT_a250_seatHeatMIARearR m4: 13|1@1+ (1,0) [0|0] "" X
 SG_ VCRIGHT_a251_seatUncalTrack m4: 14|1@1+ (1,0) [0|0] "" X
 SG_ VCRIGHT_a252_seatUncalBack m4: 15|1@1+ (1,0) [0|0] "" X
 SG_ VCRIGHT_a253_seatUncalTilt m4: 16|1@1+ (1,0) [0|0] "" X
 SG_ VCRIGHT_a254_seatUncalLift m4: 17|1@1+ (1,0) [0|0] "" X
 SG_ VCRIGHT_a255_PTCOverTemp m4: 18|1@1+ (1,0) [0|0] "" X
 SG_ VCRIGHT_a256_PTCCurrentDrawNoReq m4: 19|1@1+ (1,0) [0|0] "" X
 SG_ VCRIGHT_a257_THSMIA m4: 20|1@1+ (1,0) [0|0] "" X
 SG_ VCRIGHT_a258_PTCStuckInBoot m4: 21|1@1+ (1,0) [0|0] "" X
 SG_ VCRIGHT_a259_latchDisarmDelayF m4: 22|1@1+ (1,0) [0|0] "" X
 SG_ VCRIGHT_a260_latchDisarmDelayR m4: 23|1@1+ (1,0) [0|0] "" X
 SG_ VCRIGHT_a262_PTCFaulted m4: 25|1@1+ (1,0) [0|0] "" X
 SG_ VCRIGHT_a263_seatTrackStallDebug m4: 26|1@1+ (1,0) [0|0] "" X
 SG_ VCRIGHT_a264_seatBackStallDebug m4: 27|1@1+ (1,0) [0|0] "" X
 SG_ VCRIGHT_a265_seatTiltStallDebug m4: 28|1@1+ (1,0) [0|0] "" X
 SG_ VCRIGHT_a266_seatLiftStallDebug m4: 29|1@1+ (1,0) [0|0] "" X
 SG_ VCRIGHT_a267_seatTrackHCEncStlDbg m4: 30|1@1+ (1,0) [0|0] "" X
 SG_ VCRIGHT_a268_seatBackHCEncStlDbg m4: 31|1@1+ (1,0) [0|0] "" X
 SG_ VCRIGHT_a269_seatTiltHCEncStlDbg m4: 32|1@1+ (1,0) [0|0] "" X
 SG_ VCRIGHT_a270_seatLiftHCEncStlDbg m4: 33|1@1+ (1,0) [0|0] "" X
 SG_ VCRIGHT_a271_THSSensorFault m4: 34|1@1+ (1,0) [0|0] "" X
 SG_ VCRIGHT_a272_vhclPwrStateMsmtch m4: 35|1@1+ (1,0) [0|0] "" X
 SG_ VCRIGHT_a273_handleStuckActiveF m4: 36|1@1+ (1,0) [0|0] "" X
 SG_ VCRIGHT_a274_handleStuckActiveR m4: 37|1@1+ (1,0) [0|0] "" X
 SG_ VCRIGHT_a275_rightTurnLightFault m4: 38|1@1+ (1,0) [0|0] "" X
 SG_ VCRIGHT_a276_mirrorDebug m4: 39|1@1+ (1,0) [0|0] "" X
 SG_ VCRIGHT_a277_BLERightUnderVoltage m4: 40|1@1+ (1,0) [0|0] "" X
 SG_ VCRIGHT_a280_latchDidNotDisarmF m4: 43|1@1+ (1,0) [0|0] "" X
 SG_ VCRIGHT_a281_latchDidNotDisarmR m4: 44|1@1+ (1,0) [0|0] "" X
 SG_ VCRIGHT_a282_latchUnexpectedArmF m4: 45|1@1+ (1,0) [0|0] "" X
 SG_ VCRIGHT_a283_latchUnexpectedArmR m4: 46|1@1+ (1,0) [0|0] "" X
 SG_ VCRIGHT_a286_windowSpeedInvalidF m4: 49|1@1+ (1,0) [0|0] "" X
 SG_ VCRIGHT_a287_windowSpeedInvalidR m4: 50|1@1+ (1,0) [0|0] "" X
 SG_ VCRIGHT_a290_occupancyFaultedFront m4: 53|1@1+ (1,0) [0|0] "" X
 SG_ VCRIGHT_a291_buckleFaultedFront m4: 54|1@1+ (1,0) [0|0] "" X
 SG_ VCRIGHT_a292_buckleFaultedRearC m4: 55|1@1+ (1,0) [0|0] "" X
 SG_ VCRIGHT_a293_buckleFaultedRearR m4: 56|1@1+ (1,0) [0|0] "" X
 SG_ VCRIGHT_a304_frontIntHandleShorted m5: 7|1@1+ (1,0) [0|0] "" X
 SG_ VCRIGHT_a305_rearIntHandleShorted m5: 8|1@1+ (1,0) [0|0] "" X
 SG_ VCRIGHT_a306_handleDisconnectedF m5: 9|1@1+ (1,0) [0|0] "" X
 SG_ VCRIGHT_a307_handleDisconnectedR m5: 10|1@1+ (1,0) [0|0] "" X

BO_ 1795 VCRIGHT_debugThermal10Hz: 8 VEH
 SG_ VCRIGHT_debugThermal10HzIndex M: 0|3@1+ (1,0) [0|0] "" X
 SG_ VCRIGHT_wattsDemandEvapFeedback m0: 3|9@1- (20,0) [0|0] "W" X
 SG_ VCRIGHT_wattsDemandEvapFeedfwd m0: 12|9@1+ (20,0) [0|0] "W" X
 SG_ VCRIGHT_wattsHeaterLeftFeedback m0: 21|9@1- (20,0) [0|0] "W" X
 SG_ VCRIGHT_wattsHeaterLeftFeedfwd m0: 30|9@1+ (20,0) [0|0] "W" X
 SG_ VCRIGHT_wattsHeaterRightFeedback m0: 39|9@1- (20,0) [0|0] "W" X
 SG_ VCRIGHT_wattsHeaterRightFeedfwd m0: 48|9@1+ (20,0) [0|0] "W" X
 SG_ VCRIGHT_tempEvapAdjustmentLeft m1: 8|7@1+ (0.1,0) [0|0] "degC" X
 SG_ VCRIGHT_tempEvapAdjustmentRight m1: 16|7@1+ (0.1,0) [0|0] "degC" X
 SG_ VCRIGHT_hvacPanelFloorSplitRow1 m2: 8|8@1+ (0.4,0) [0|0] "%" X
 SG_ VCRIGHT_hvacDefrostPercent m2: 16|8@1+ (0.4,0) [0|0] "%" X
 SG_ VCRIGHT_hvacRow2Percent m2: 24|8@1+ (0.4,0) [0|0] "%" X
 SG_ VCRIGHT_hvacPanelFloorSplitRow2 m2: 32|8@1+ (0.4,0) [0|0] "%" X
 SG_ VCRIGHT_cabinTempThs m3: 8|8@1+ (0.5,-40) [0|0] "degC" X
 SG_ VCRIGHT_cabinTempThsBracket m3: 16|8@1+ (0.5,-40) [0|0] "degC" X
 SG_ VCRIGHT_cabinTempProbe m3: 24|8@1+ (0.5,-40) [0|0] "degC" X
 SG_ VCRIGHT_setTempAdjustmentLeft m3: 32|7@1+ (0.1,0) [0|0] "degC" X
 SG_ VCRIGHT_setTempAdjustmentRight m3: 40|7@1+ (0.1,0) [0|0] "degC" X
 SG_ VCRIGHT_hvacLHBleedCalibrated m4: 3|1@1+ (1,0) [0|0] "" X
 SG_ VCRIGHT_hvacActuatorsCalibrated m4: 4|1@1+ (1,0) [0|0] "" X
 SG_ VCRIGHT_hvacRHBleedCalibrated m4: 7|1@1+ (1,0) [0|0] "" X
 SG_ VCRIGHT_hvacLHVaneCalibrated m4: 11|1@1+ (1,0) [0|0] "" X
 SG_ VCRIGHT_hvacRHVaneCalibrated m4: 15|1@1+ (1,0) [0|0] "" X
 SG_ VCRIGHT_hvacUpperModeCalibrated m4: 19|1@1+ (1,0) [0|0] "" X
 SG_ VCRIGHT_hvacLowerModeCalibrated m4: 23|1@1+ (1,0) [0|0] "" X
 SG_ VCRIGHT_hvacIntakeCalibrated m4: 27|1@1+ (1,0) [0|0] "" X

BO_ 259 VCRIGHT_doorStatus: 8 VEH
 SG_ VCRIGHT_frontHandlePWM: 14|7@1+ (1,0) [0|0] "%" X
 SG_ VCRIGHT_frontHandlePulled: 10|1@1+ (1,0) [0|0] "" X
 SG_ VCRIGHT_frontHandlePulledPersist: 30|1@1+ (1,0) [0|0] "" X
 SG_ VCRIGHT_frontIntSwitchPressed: 31|1@1+ (1,0) [0|0] "" X
 SG_ VCRIGHT_frontLatchStatus: 0|4@1+ (1,0) [0|0] "" X
 SG_ VCRIGHT_frontLatchSwitch: 8|1@1+ (1,0) [0|0] "" X
 SG_ VCRIGHT_frontRelActuatorSwitch: 12|1@1+ (1,0) [0|0] "" X
 SG_ VCRIGHT_mirrorDipped: 63|1@1+ (1,0) [0|0] "" X
 SG_ VCRIGHT_mirrorFoldState: 52|3@1+ (1,0) [0|0] "" X
 SG_ VCRIGHT_mirrorRecallState: 60|3@1+ (1,0) [0|0] "" X
 SG_ VCRIGHT_mirrorState: 49|3@1+ (1,0) [0|0] "" X
 SG_ VCRIGHT_mirrorTiltXPosition: 33|8@1+ (0.02,0) [0|0] "V" X
 SG_ VCRIGHT_mirrorTiltYPosition: 41|8@1+ (0.02,0) [0|0] "V" X
 SG_ VCRIGHT_rearHandlePWM: 21|7@1+ (1,0) [0|0] "%" X
 SG_ VCRIGHT_rearHandlePulled: 11|1@1+ (1,0) [0|0] "" X
 SG_ VCRIGHT_rearIntSwitchPressed: 32|1@1+ (1,0) [0|0] "" X
 SG_ VCRIGHT_rearLatchStatus: 4|4@1+ (1,0) [0|0] "" X
 SG_ VCRIGHT_rearLatchSwitch: 9|1@1+ (1,0) [0|0] "" X
 SG_ VCRIGHT_rearRelActuatorSwitch: 13|1@1+ (1,0) [0|0] "" X
 SG_ VCRIGHT_reservedForBackCompat: 28|2@1+ (1,0) [0|0] "" X
 SG_ VCRIGHT_trunkLatchStatus: 56|4@1+ (1,0) [0|0] "" X

BO_ 915 ID393VCRIGHT_epbmDebug: 8 VEH
 SG_ VCRIGHT_epbmDebugIndex M : 0|1@1+ (1,0) [0|1] ""  Receiver
 SG_ VCRIGHT_cdpEnumDummy m1 : 24|2@1+ (1,0) [0|2] ""  Receiver
 SG_ VCRIGHT_epbFaultStatus m0 : 58|2@1+ (1,0) [0|3] ""  Receiver
 SG_ VCRIGHT_epbMotorCurrent m0 : 5|11@1+ (0.01,0) [0|20.47] "A"  Receiver
 SG_ VCRIGHT_epbSummonState m0 : 45|3@1+ (1,0) [0|6] ""  Receiver
 SG_ VCRIGHT_epbUnitStatus m0 : 51|5@1+ (1,0) [0|22] ""  Receiver
 SG_ VCRIGHT_epbmApplyVoltage m0 : 16|11@1+ (0.01,0) [0|20.47] "A"  Receiver
 SG_ VCRIGHT_epbmCaliperState m0 : 1|3@1+ (1,0) [0|6] ""  Receiver
 SG_ VCRIGHT_epbmDynApplyingAllowed m1 : 9|1@1+ (1,0) [0|1] ""  Receiver
 SG_ VCRIGHT_epbmDynamicAllowed m1 : 2|1@1+ (1,0) [0|1] ""  Receiver
 SG_ VCRIGHT_epbmFaultAllowed m1 : 11|1@1+ (1,0) [0|1] ""  Receiver
 SG_ VCRIGHT_epbmFaultStatus m0 : 56|2@1+ (1,0) [0|3] ""  ui
 SG_ VCRIGHT_epbmMotorEnabled m0 : 4|1@1+ (1,0) [0|1] ""  Receiver
 SG_ VCRIGHT_epbmOpenAllowed m1 : 1|1@1+ (1,0) [0|1] ""  Receiver
 SG_ VCRIGHT_epbmParkAllowed m1 : 3|1@1+ (1,0) [0|1] ""  Receiver
 SG_ VCRIGHT_epbmParkingAllowed m1 : 8|1@1+ (1,0) [0|1] ""  Receiver
 SG_ VCRIGHT_epbmReleaseVoltage m0 : 27|11@1+ (0.01,0) [0|20.47] "A"  Receiver
 SG_ VCRIGHT_epbmReleasingAllowed m1 : 10|1@1+ (1,0) [0|1] ""  Receiver
 SG_ VCRIGHT_epbmServiceAllowed m1 : 5|1@1+ (1,0) [0|1] ""  Receiver
 SG_ VCRIGHT_epbmStartAllowed m1 : 4|1@1+ (1,0) [0|1] ""  Receiver
 SG_ VCRIGHT_epbmSummonAllowed m1 : 12|1@1+ (1,0) [0|1] ""  Receiver
 SG_ VCRIGHT_epbmSummonParkAllowed m1 : 13|1@1+ (1,0) [0|1] ""  Receiver
 SG_ VCRIGHT_epbmSummonReleaseAllowed m1 : 14|1@1+ (1,0) [0|1] ""  Receiver
 SG_ VCRIGHT_epbmSummonState m0 : 48|3@1+ (1,0) [0|6] ""  Receiver
 SG_ VCRIGHT_epbmSystemStatus m0 : 60|4@1+ (1,0) [0|8] ""  Receiver
 SG_ VCRIGHT_epbmUnknownAllowed m1 : 16|1@1+ (1,0) [0|1] ""  Receiver
 SG_ VCRIGHT_epbmWinchAllowed m1 : 6|1@1+ (1,0) [0|1] ""  Receiver
 SG_ VCRIGHT_epbmWinchReleaseAllowed m1 : 7|1@1+ (1,0) [0|1] ""  Receiver
 SG_ VCRIGHT_summonActiveAllowed m1 : 19|1@1+ (1,0) [0|1] ""  Receiver
 SG_ VCRIGHT_summonArmedAllowed m1 : 18|1@1+ (1,0) [0|1] ""  Receiver
 SG_ VCRIGHT_summonCompleteAllowed m1 : 20|1@1+ (1,0) [0|1] ""  Receiver
 SG_ VCRIGHT_summonFaultAllowed m1 : 21|1@1+ (1,0) [0|1] ""  Receiver
 SG_ VCRIGHT_summonFaultReason m0 : 40|5@1+ (1,0) [0|28] ""  Receiver
 SG_ VCRIGHT_summonIdleAllowed m1 : 17|1@1+ (1,0) [0|1] ""  Receiver
 SG_ VCRIGHT_summonInitAllowed m1 : 15|1@1+ (1,0) [0|1] ""  Receiver
 SG_ VCRIGHT_summonUnavailableAllowed m1 : 22|1@1+ (1,0) [0|1] ""  Receiver

BO_ 579 VCRIGHT_hvacStatus: 8 Vector__XXX
 SG_ VCRIGHT_hvacOverheatProtActive m3 : 63|1@1+ (1,0) [0|0] "" Vector__XXX
 SG_ VCRIGHT_hvacModelInitStatus m0 : 60|4@1+ (1,0) [0|0] "" Vector__XXX
 SG_ VCRIGHT_extendedHvacPerfTestSupportState m2 : 59|4@1+ (1,0) [0|0] "" Vector__XXX
 SG_ VCRIGHT_hvacLimitedReasonLeft m3 : 59|3@1+ (1,0) [0|0] "" Vector__XXX
 SG_ VCRIGHT_hvacSystemNominal m0 : 59|1@1+ (1,0) [0|0] "" Vector__XXX
 SG_ VCRIGHT_hvacDuctTargetRight m1 : 56|8@1+ (0.5,-40) [0|0] "" Vector__XXX
 SG_ VCRIGHT_hvacLimitedReasonRight m3 : 56|3@1+ (1,0) [0|0] "" Vector__XXX
 SG_ VCRIGHT_hvacSecondRowState m0 : 56|3@1+ (1,0) [0|0] "" Vector__XXX
 SG_ VCRIGHT_tempDuctRightLower m4 : 56|8@1+ (0.5,-22) [0|0] "" Vector__XXX
 SG_ VCRIGHT_hvacVentStatus m0 : 54|2@1+ (1,0) [0|0] "" Vector__XXX
 SG_ VCRIGHT_windshieldCameraHeaterDutyRequest m2 : 54|5@1+ (5,0) [0|0] "" Vector__XXX
 SG_ VCRIGHT_hvacRefHighPowerRequest m2 : 53|1@1+ (1,0) [0|0] "" Vector__XXX
 SG_ VCRIGHT_hvacPowerState m0 : 51|3@1+ (1,0) [0|0] "" Vector__XXX
 SG_ VCRIGHT_hvacACRunning m0 : 50|1@1+ (1,0) [0|0] "" Vector__XXX
 SG_ VCRIGHT_hvacDuctTargetLeft m1 : 48|8@1+ (0.5,-40) [0|0] "" Vector__XXX
 SG_ VCRIGHT_hvacRecirc m0 : 48|2@1+ (1,0) [0|0] "" Vector__XXX
 SG_ VCRIGHT_minsToSunset m3 : 48|8@1+ (10,0) [0|0] "" Vector__XXX
 SG_ VCRIGHT_refrigDistCommanded m2 : 48|1@1+ (1,0) [0|0] "" Vector__XXX
 SG_ VCRIGHT_tempDuctLeftLower m4 : 48|8@1+ (0.5,-22) [0|0] "" Vector__XXX
 SG_ VCRIGHT_hvacBlowerSegment m0 : 44|4@1+ (1,0) [0|0] "" Vector__XXX
 SG_ VCRIGHT_hvacAirDistributionMode m0 : 41|3@1+ (1,0) [0|0] "" Vector__XXX
 SG_ VCRIGHT_minsToSunrise m3 : 40|8@1+ (10,0) [0|0] "" Vector__XXX
 SG_ VCRIGHT_solarLoadOnVehicle m2 : 40|8@1+ (4,0) [0|0] "" Vector__XXX
 SG_ VCRIGHT_autoHvacBlowerShouldLimit m2 : 37|1@1+ (1,0) [0|0] "" Vector__XXX
 SG_ VCRIGHT_hvacQdotRight m4 : 34|14@1+ (1,-8191) [0|0] "" Vector__XXX
 SG_ VCRIGHT_blowerTorqueIndex m5 : 32|7@1+ (1,0) [0|0] "" Vector__XXX
 SG_ VCRIGHT_hvacAirflowReason m2 : 32|5@1+ (1,0) [0|0] "" Vector__XXX
 SG_ VCRIGHT_tempDuctRight m1 : 32|8@1+ (0.5,-22) [0|0] "" Vector__XXX
 SG_ VCRIGHT_solarElevation m3 : 31|9@1- (0.5,0) [0|0] "" Vector__XXX
 SG_ VCRIGHT_hvacCabinAtTempTarget m2 : 30|1@1+ (1,0) [0|0] "" Vector__XXX
 SG_ VCRIGHT_hvacCabinTempEst m0 : 30|11@1+ (0.1,-40) [0|0] "" Vector__XXX
 SG_ VCRIGHT_tempMonitorNotNominal m2 : 29|1@1+ (1,0) [0|0] "" Vector__XXX
 SG_ VCRIGHT_COPNotRunningReasonFiltered m0 : 27|3@1+ (1,0) [0|0] "" Vector__XXX
 SG_ VCRIGHT_autoDefogStatus m3 : 26|2@1+ (1,0) [0|0] "" Vector__XXX
 SG_ VCRIGHT_hvacCabinTempEstValid m0 : 26|1@1+ (1,0) [0|0] "" Vector__XXX
 SG_ VCRIGHT_hvacMassflowRefrigSystem m1 : 24|8@1+ (1,0) [0|0] "" Vector__XXX
 SG_ VCRIGHT_steeringWheelHeatStatus m3 : 24|2@1+ (1,0) [0|0] "" Vector__XXX
 SG_ VCRIGHT_dogModeState m0 : 22|4@1+ (1,0) [0|0] "" Vector__XXX
 SG_ VCRIGHT_hvacRequestsAutoIntake m3 : 22|1@1+ (1,0) [0|0] "" Vector__XXX
 SG_ VCRIGHT_passengerPresentHvacCycle m3 : 21|1@1+ (1,0) [0|0] "" Vector__XXX
 SG_ VCRIGHT_childModeHVACState m0 : 20|2@1+ (1,0) [0|0] "" Vector__XXX
 SG_ VCRIGHT_hvacQdotLeft m4 : 20|14@1+ (1,-8191) [0|0] "" Vector__XXX
 SG_ VCRIGHT_hvacEvapInletTempEstimate m2 : 19|10@1+ (0.13,-40) [0|0] "" Vector__XXX
 SG_ VCRIGHT_hpSplitTempsEnabled m2 : 18|1@1+ (1,0) [0|0] "" Vector__XXX
 SG_ VCRIGHT_hvacFrontLeftSeatHeatStatus m4 : 18|2@1+ (1,0) [0|0] "" Vector__XXX
 SG_ VCRIGHT_hvacRequestsFullAuto m3 : 17|3@1+ (1,0) [0|0] "" Vector__XXX
 SG_ VCRIGHT_tempDuctLeft m1 : 16|8@1+ (0.5,-22) [0|0] "" Vector__XXX
 SG_ VCRIGHT_coolingDownStatus m0 : 15|5@1+ (3,7) [0|0] "" Vector__XXX
 SG_ VCRIGHT_hvacManualToAutoNotify m3 : 14|3@1+ (1,0) [0|0] "" Vector__XXX
 SG_ VCRIGHT_hvacRecircDoorPercent m1 : 10|6@1+ (1.6,0) [0|0] "" Vector__XXX
 SG_ VCRIGHT_tempDuctLeftUpper m4 : 10|8@1+ (0.5,-22) [0|0] "" Vector__XXX
 SG_ VCRIGHT_tempDuctRightUpper m2 : 10|8@1+ (0.5,-22) [0|0] "" Vector__XXX
 SG_ VCRIGHT_warmingUpStatus m0 : 10|5@1+ (3,7) [0|0] "" Vector__XXX
 SG_ VCRIGHT_autoSwingAvailable m4 : 9|1@1+ (1,0) [0|0] "" Vector__XXX
 SG_ VCRIGHT_enableTripleCameraFanPowerInSleep m2 : 9|1@1+ (1,0) [0|0] "" Vector__XXX
 SG_ VCRIGHT_foggingControllerResetReason m5 : 9|15@1+ (1,0) [0|0] "" Vector__XXX
 SG_ VCRIGHT_hvacSeatFrontLeftTempTarget m3 : 6|8@1+ (0.5,-40) [0|0] "" Vector__XXX
 SG_ VCRIGHT_hvacFrontRightSeatHeatStatus m3 : 4|2@1+ (1,0) [0|0] "" Vector__XXX
 SG_ VCRIGHT_hvacStatusIndex M : 0|3@1+ (1,0) [0|0] "" Vector__XXX

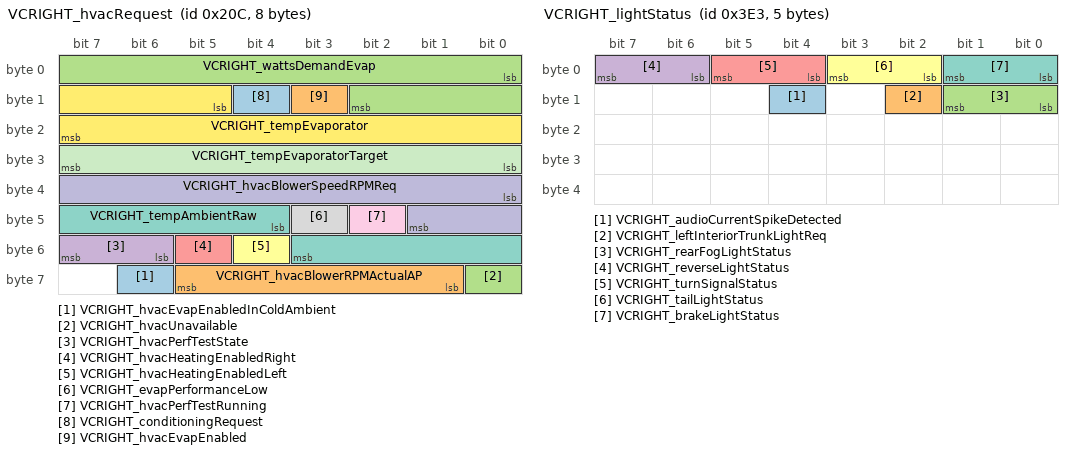
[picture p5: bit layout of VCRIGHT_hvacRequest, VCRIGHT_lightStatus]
BO_ 524 VCRIGHT_hvacRequest: 8 Vector__XXX
 SG_ VCRIGHT_hvacEvapEnabledInColdAmbient : 62|1@1+ (1,0) [0|0] "" Vector__XXX
 SG_ VCRIGHT_hvacBlowerRPMActualAP : 57|5@1+ (200,0) [0|0] "" Vector__XXX
 SG_ VCRIGHT_hvacUnavailable : 56|1@1+ (1,0) [0|0] "" Vector__XXX
 SG_ VCRIGHT_hvacPerfTestState : 54|2@1+ (1,0) [0|0] "" Vector__XXX
 SG_ VCRIGHT_hvacHeatingEnabledRight : 53|1@1+ (1,0) [0|0] "" Vector__XXX
 SG_ VCRIGHT_hvacHeatingEnabledLeft : 52|1@1+ (1,0) [0|0] "" Vector__XXX
 SG_ VCRIGHT_tempAmbientRaw : 44|8@1+ (0.5,-40) [0|0] "" Vector__XXX
 SG_ VCRIGHT_evapPerformanceLow : 43|1@1+ (1,0) [0|0] "" Vector__XXX
 SG_ VCRIGHT_hvacPerfTestRunning : 42|1@1+ (1,0) [0|0] "" Vector__XXX
 SG_ VCRIGHT_hvacBlowerSpeedRPMReq : 32|10@1+ (5,0) [0|0] "" Vector__XXX
 SG_ VCRIGHT_tempEvaporatorTarget : 24|8@1+ (0.2,0) [0|0] "" Vector__XXX
 SG_ VCRIGHT_tempEvaporator : 13|11@1+ (0.1,-40) [0|0] "" Vector__XXX
 SG_ VCRIGHT_conditioningRequest : 12|1@1+ (1,0) [0|0] "" Vector__XXX
 SG_ VCRIGHT_hvacEvapEnabled : 11|1@1+ (1,0) [0|0] "" Vector__XXX
 SG_ VCRIGHT_wattsDemandEvap : 0|11@1+ (5,0) [0|0] "" Vector__XXX

BO_ 774 VCRIGHT_info_306: 8 VEH
 SG_ VCRIGHT_infoIndex M: 0|8@1+ (1,0) [0|0] "" X
 SG_ VCRIGHT_infoBuildType m10: 8|3@1+ (1,0) [0|0] "" X
 SG_ VCRIGHT_infoBuildConfigId m10: 16|16@1+ (1,0) [0|0] "" X
 SG_ VCRIGHT_infoHardwareId m10: 32|16@1+ (1,0) [0|0] "" X
 SG_ VCRIGHT_infoComponentId m10: 48|16@1+ (1,0) [0|0] "" X
 SG_ VCRIGHT_infoPcbaId m11: 8|8@1+ (1,0) [0|0] "" X
 SG_ VCRIGHT_infoAssemblyId m11: 16|8@1+ (1,0) [0|0] "" X
 SG_ VCRIGHT_infoUsageId m11: 24|16@1+ (1,0) [0|0] "" X
 SG_ VCRIGHT_infoSubUsageId m11: 40|16@1+ (1,0) [0|0] "" X
 SG_ VCRIGHT_infoAppCrc m13: 8|32@1+ (1,0) [0|0] "" X
 SG_ VCRIGHT_infoAppGitHash m17: 10|54@1+ (4,0) [0|0] "" X
 SG_ VCRIGHT_infoBootGitHash m18: 10|54@1+ (4,0) [0|0] "" X
 SG_ VCRIGHT_infoPlatformType m19: 8|8@1+ (1,0) [0|0] "" X
 SG_ VCRIGHT_infoBootUdsProtoVersion m20: 8|16@1+ (1,0) [0|0] "" X
 SG_ VCRIGHT_infoBootCrc m20: 24|32@1+ (1,0) [0|0] "" X

BO_ 995 VCRIGHT_lightStatus: 5 Vector__XXX
 SG_ VCRIGHT_audioCurrentSpikeDetected : 12|1@1+ (1,0) [0|0] "" Vector__XXX
 SG_ VCRIGHT_leftInteriorTrunkLightReq : 10|1@1+ (1,0) [0|0] "" Vector__XXX
 SG_ VCRIGHT_rearFogLightStatus : 8|2@1+ (1,0) [0|0] "" Vector__XXX
 SG_ VCRIGHT_reverseLightStatus : 6|2@1+ (1,0) [0|0] "" Vector__XXX
 SG_ VCRIGHT_turnSignalStatus : 4|2@1+ (1,0) [0|0] "" Vector__XXX
 SG_ VCRIGHT_tailLightStatus : 2|2@1+ (1,0) [0|0] "" Vector__XXX
 SG_ VCRIGHT_brakeLightStatus : 0|2@1+ (1,0) [0|0] "" Vector__XXX

BO_ 611 VCRIGHT_logging10Hz: 8 Vector__XXX
 SG_ VCRIGHT_ptcHeaterBadRodDetectionState m2 : 56|4@1+ (1,0) [0|0] "" Vector__XXX
 SG_ VCRIGHT_windshieldRHExteriorSurface m3 : 56|8@1+ (1,0) [0|0] "" Vector__XXX
 SG_ VCRIGHT_hvacIntakePosition m1 : 53|8@1+ (0.4,0) [0|0] "" Vector__XXX
 SG_ VCRIGHT_hvacIntakeTarget m0 : 53|8@1+ (0.4,0) [0|0] "" Vector__XXX
 SG_ VCRIGHT_tempDuctRightEst m2 : 48|8@1+ (0.5,-22) [0|0] "" Vector__XXX
 SG_ VCRIGHT_hvacLowerModePosition m1 : 45|8@1+ (0.4,0) [0|0] "" Vector__XXX
 SG_ VCRIGHT_hvacLowerModeTarget m0 : 45|8@1+ (0.4,0) [0|0] "" Vector__XXX
 SG_ VCRIGHT_frontRightSeatTempTargetQuasiSS m4 : 42|6@1+ (1,20) [0|0] "" Vector__XXX
 SG_ VCRIGHT_tempDuctLeftEst m2 : 40|8@1+ (0.5,-22) [0|0] "" Vector__XXX
 SG_ VCRIGHT_frontLeftSeatTempTargetQuasiSS m4 : 36|6@1+ (0.75,20) [0|0] "" Vector__XXX
 SG_ VCRIGHT_hvacUpperModePosition m1 : 35|10@1+ (0.1,0) [0|0] "" Vector__XXX
 SG_ VCRIGHT_hvacUpperModeTarget m0 : 35|10@1+ (0.1,0) [0|0] "" Vector__XXX
 SG_ VCRIGHT_tempDatRightEst m2 : 30|9@1+ (0.5,-22) [0|0] "" Vector__XXX
 SG_ VCRIGHT_hvacRHVanePosition m1 : 27|8@1+ (0.4,0) [0|0] "" Vector__XXX
 SG_ VCRIGHT_hvacRHVaneTarget m0 : 27|8@1+ (0.4,0) [0|0] "" Vector__XXX
 SG_ VCRIGHT_tempDatLeftEst m2 : 21|9@1+ (0.5,-22) [0|0] "" Vector__XXX
 SG_ VCRIGHT_EvapPulldownBiasActive m2 : 20|1@1+ (1,0) [0|0] "" Vector__XXX
 SG_ VCRIGHT_hvacLHVanePosition m1 : 19|8@1+ (0.4,0) [0|0] "" Vector__XXX
 SG_ VCRIGHT_hvacLHVaneTarget m0 : 19|8@1+ (0.4,0) [0|0] "" Vector__XXX
 SG_ VCRIGHT_hvacIntakeActuatorState m2 : 16|2@1+ (1,0) [0|0] "" Vector__XXX
 SG_ VCRIGHT_hvacLowerModeActState m2 : 14|2@1+ (1,0) [0|0] "" Vector__XXX
 SG_ VCRIGHT_hvacUpperModeActState m2 : 12|2@1+ (1,0) [0|0] "" Vector__XXX
 SG_ VCRIGHT_hvacRHBleedPosition m1 : 11|8@1+ (0.4,0) [0|0] "" Vector__XXX
 SG_ VCRIGHT_hvacRHBleedTarget m0 : 11|8@1+ (0.4,0) [0|0] "" Vector__XXX
 SG_ VCRIGHT_hvacRHVaneActuatorState m2 : 10|2@1+ (1,0) [0|0] "" Vector__XXX
 SG_ VCRIGHT_hvacLHVaneActuatorState m2 : 8|2@1+ (1,0) [0|0] "" Vector__XXX
 SG_ VCRIGHT_hvacRHBleedActuatorState m2 : 5|2@1+ (1,0) [0|0] "" Vector__XXX
 SG_ VCRIGHT_hvacLHBleedActuatorState m2 : 3|2@1+ (1,0) [0|0] "" Vector__XXX
 SG_ VCRIGHT_hvacLHBleedPosition m1 : 3|8@1+ (0.4,0) [0|0] "" Vector__XXX
 SG_ VCRIGHT_hvacLHBleedTarget m0 : 3|8@1+ (0.4,0) [0|0] "" Vector__XXX
 SG_ VCRIGHT_logging10HzIndex M : 0|3@1+ (1,0) [0|0] "" Vector__XXX

BA_DEF_ BO_ "GenMsgSendType" ENUM "Cyclic";
BA_DEF_ BO_ "GenMsgCycleTime" INT 0 10000;

BA_ "GenMsgSendType" BO_ 632 0;
BA_ "GenMsgCycleTime" BO_ 632 500;

BA_ "GenMsgSendType" BO_ 723 0;
BA_ "GenMsgCycleTime" BO_ 723 1000;

BA_ "GenMsgSendType" BO_ 1064 0;
BA_ "GenMsgCycleTime" BO_ 1064 1000;

BA_ "GenMsgSendType" BO_ 952 0;
BA_ "GenMsgCycleTime" BO_ 952 1000;

BA_ "GenMsgSendType" BO_ 627 0;
BA_ "GenMsgCycleTime" BO_ 627 500;

BA_ "GenMsgSendType" BO_ 947 0;
BA_ "GenMsgCycleTime" BO_ 947 500;

BA_ "GenMsgSendType" BO_ 644 0;
BA_ "GenMsgCycleTime" BO_ 644 500;

BA_ "GenMsgSendType" BO_ 595 0;
BA_ "GenMsgCycleTime" BO_ 595 500;

BA_ "GenMsgSendType" BO_ 824 0;
BA_ "GenMsgCycleTime" BO_ 824 1000;

BA_ "GenMsgSendType" BO_ 609 0;
BA_ "GenMsgCycleTime" BO_ 609 100;

BA_ "GenMsgSendType" BO_ 545 0;
BA_ "GenMsgCycleTime" BO_ 545 50;

BA_ "GenMsgSendType" BO_ 832 0;
BA_ "GenMsgCycleTime" BO_ 832 100;

BA_ "GenMsgSendType" BO_ 577 0;
BA_ "GenMsgCycleTime" BO_ 577 100;

BA_ "GenMsgSendType" BO_ 753 0;
BA_ "GenMsgCycleTime" BO_ 753 100;

BA_ "GenMsgSendType" BO_ 769 0;
BA_ "GenMsgCycleTime" BO_ 769 1000;

BA_ "GenMsgSendType" BO_ 1009 0;
BA_ "GenMsgCycleTime" BO_ 1009 100;

BA_ "GenMsgSendType" BO_ 705 0;
BA_ "GenMsgCycleTime" BO_ 705 17;

BA_ "GenMsgSendType" BO_ 897 0;
BA_ "GenMsgCycleTime" BO_ 897 250;

BA_ "GenMsgSendType" BO_ 721 0;
BA_ "GenMsgCycleTime" BO_ 721 100;

BA_ "GenMsgSendType" BO_ 801 0;
BA_ "GenMsgCycleTime" BO_ 801 1000;

BA_ "GenMsgSendType" BO_ 737 0;
BA_ "GenMsgCycleTime" BO_ 737 20;

BA_ "GenMsgSendType" BO_ 929 0;
BA_ "GenMsgCycleTime" BO_ 929 100;

BA_ "GenMsgSendType" BO_ 864 0;
BA_ "GenMsgCycleTime" BO_ 864 100;

BA_ "GenMsgSendType" BO_ 258 0;
BA_ "GenMsgCycleTime" BO_ 258 100;

BA_ "GenMsgSendType" BO_ 626 0;
BA_ "GenMsgCycleTime" BO_ 626 50;

BA_ "GenMsgSendType" BO_ 642 0;
BA_ "GenMsgCycleTime" BO_ 642 50;

BA_ "GenMsgSendType" BO_ 770 0;
BA_ "GenMsgCycleTime" BO_ 770 1000;

BA_ "GenMsgSendType" BO_ 1860 0;
BA_ "GenMsgCycleTime" BO_ 1860 1000;

BA_ "GenMsgSendType" BO_ 778 0;
BA_ "GenMsgCycleTime" BO_ 778 50;

BA_ "GenMsgSendType" BO_ 1250 0;
BA_ "GenMsgCycleTime" BO_ 1250 100;

BA_ "GenMsgSendType" BO_ 930 0;
BA_ "GenMsgCycleTime" BO_ 930 50;

BA_ "GenMsgSendType" BO_ 610 0;
BA_ "GenMsgCycleTime" BO_ 610 100;

BA_ "GenMsgSendType" BO_ 962 0;
BA_ "GenMsgCycleTime" BO_ 962 50;

BA_ "GenMsgSendType" BO_ 960 0;
BA_ "GenMsgCycleTime" BO_ 960 100;

BA_ "GenMsgSendType" BO_ 1795 0;
BA_ "GenMsgCycleTime" BO_ 1795 10;

BA_ "GenMsgSendType" BO_ 259 0;
BA_ "GenMsgCycleTime" BO_ 259 100;

BA_ "GenMsgSendType" BO_ 915 0;
BA_ "GenMsgCycleTime" BO_ 915 50;

BA_ "GenMsgSendType" BO_ 579 0;
BA_ "GenMsgCycleTime" BO_ 579 100;

BA_ "GenMsgSendType" BO_ 524 0;
BA_ "GenMsgCycleTime" BO_ 524 100;

BA_ "GenMsgSendType" BO_ 774 0;
BA_ "GenMsgCycleTime" BO_ 774 1000;

BA_ "GenMsgSendType" BO_ 995 0;
BA_ "GenMsgCycleTime" BO_ 995 100;

BA_ "GenMsgSendType" BO_ 611 0;
BA_ "GenMsgCycleTime" BO_ 611 20;

VAL_ 632 UI_roadCurvHealth 0 "UNAVAILABLE" 1 "DEGRADED" 2 "AVAILABLE" 3 "DATABASE";

VAL_ 723 UI_isSunUp 0 "DOWN" 1 "UP" 3 "SNA";
VAL_ 723 UI_solarAzimuthAngle -32768 "SNA";
VAL_ 723 UI_solarAzimuthAngleCarRef 255 "SNA";
VAL_ 723 UI_solarElevationAngle 127 "SNA";

VAL_ 851 UI_autopilotTrial 0 "NONE" 1 "START" 2 "STOP" 3 "ACTIVE";
VAL_ 851 UI_cellNetworkTechnology 0 "NONE" 1 "GPRS" 2 "EDGE" 3 "UMTS" 4 "HSDPA" 5 "HSUPA" 6 "HSPA" 7 "LTE" 15 "SNA";
VAL_ 851 UI_cellSignalBars 0 "ZERO" 1 "ONE" 2 "TWO" 3 "THREE" 4 "FOUR" 5 "FIVE" 7 "SNA";
VAL_ 851 UI_factoryReset 0 "NONE_SNA" 1 "DEVELOPER" 2 "DIAGNOSTIC" 3 "CUSTOMER";

VAL_ 856 UI_TPMSLearnIDMode 0 "NO_ID_LEARN_FUNCTION" 1 "AUTO_LEARN_ACTIVE_BY_MANUAL" 2 "AUTO_LOCATION_ACTIVE_BY_MANUAL" 3 "AUTO_LEARN_ACTIVE_AFTER_PWR" 4 "AUTO_LOCATION_ACTIVE_AFTER_PWR";
VAL_ 856 UI_TPMSMode 0 "UNUSED_MODE" 1 "NORMAL_MODE" 2 "PERFORMANCE_MODE";
VAL_ 856 UI_sizeOfWheelSelect 0 "UNUSED" 1 "18_INCH_WHEEL" 2 "19_INCH_WHEEL";

VAL_ 627 UI_displayBrightnessLevel 255 "SNA";
VAL_ 627 UI_domeLightSwitch 0 "OFF" 1 "ON" 2 "AUTO";
VAL_ 627 UI_driveStateRequest 0 "IDLE" 1 "START";
VAL_ 627 UI_frontLeftSeatHeatReq 0 "OFF" 1 "LEVEL1" 2 "LEVEL2" 3 "LEVEL3";
VAL_ 627 UI_frontRightSeatHeatReq 0 "OFF" 1 "LEVEL1" 2 "LEVEL2" 3 "LEVEL3";
VAL_ 627 UI_lightSwitch 0 "AUTO_SNA" 1 "ON" 2 "PARKING" 3 "OFF";
VAL_ 627 UI_lockRequest 0 "IDLE" 1 "LOCK" 2 "UNLOCK" 3 "REMOTE_UNLOCK" 4 "REMOTE_LOCK" 7 "SNA";
VAL_ 627 UI_mirrorFoldRequest 0 "IDLE" 1 "RETRACT" 2 "PRESENT" 3 "SNA";
VAL_ 627 UI_rearCenterSeatHeatReq 0 "OFF" 1 "LEVEL1" 2 "LEVEL2" 3 "LEVEL3";
VAL_ 627 UI_rearLeftSeatHeatReq 0 "OFF" 1 "LEVEL1" 2 "LEVEL2" 3 "LEVEL3";
VAL_ 627 UI_rearRightSeatHeatReq 0 "OFF" 1 "LEVEL1" 2 "LEVEL2" 3 "LEVEL3";
VAL_ 627 UI_remoteClosureRequest 0 "IDLE" 1 "REAR_TRUNK_MOVE" 2 "FRONT_TRUNK_MOVE" 3 "SNA";
VAL_ 627 UI_remoteStartRequest 0 "IDLE" 1 "START" 4 "SNA";
VAL_ 627 UI_steeringBacklightEnabled 0 "DISABLED" 1 "ENABLED";
VAL_ 627 UI_steeringButtonMode 0 "OFF" 1 "STEERING_COLUMN_ADJ" 2 "MIRROR_LEFT" 3 "MIRROR_RIGHT" 4 "HEADLIGHT_LEFT" 5 "HEADLIGHT_RIGHT";
VAL_ 627 UI_wiperMode 0 "SNA" 1 "SERVICE" 2 "NORMAL" 3 "PARK";
VAL_ 627 UI_wiperRequest 0 "SNA" 1 "OFF" 2 "AUTO" 3 "SLOW_INTERMITTENT" 4 "FAST_INTERMITTENT" 5 "SLOW_CONTINUOUS" 6 "FAST_CONTINUOUS";

VAL_ 545 VCFRONT_LVPowerStateIndex 0 "Mux0" 1 "Mux1";
VAL_ 545 VCFRONT_vehiclePowerState 0 "OFF" 1 "CONDITIONING" 2 "ACCESSORY" 3 "DRIVE";
VAL_ 545 VCFRONT_parkLVState 0 "OFF" 1 "ON" 2 "GOING_DOWN" 3 "FAULT";
VAL_ 545 VCFRONT_espLVState 0 "OFF" 1 "ON" 2 "GOING_DOWN" 3 "FAULT";
VAL_ 545 VCFRONT_radcLVState 0 "OFF" 1 "ON" 2 "GOING_DOWN" 3 "FAULT";
VAL_ 545 VCFRONT_hvacCompLVState 0 "OFF" 1 "ON" 2 "GOING_DOWN" 3 "FAULT";
VAL_ 545 VCFRONT_ptcLVRequest 0 "OFF" 1 "ON" 2 "GOING_DOWN" 3 "FAULT";
VAL_ 545 VCFRONT_sccmLVRequest 0 "OFF" 1 "ON" 2 "GOING_DOWN" 3 "FAULT";
VAL_ 545 VCFRONT_tpmsLVRequest 0 "OFF" 1 "ON" 2 "GOING_DOWN" 3 "FAULT";
VAL_ 545 VCFRONT_rcmLVRequest 0 "OFF" 1 "ON" 2 "GOING_DOWN" 3 "FAULT";
VAL_ 545 VCFRONT_iBoosterLVState 0 "OFF" 1 "ON" 2 "GOING_DOWN" 3 "FAULT";
VAL_ 545 VCFRONT_tunerLVRequest 0 "OFF" 1 "ON" 2 "GOING_DOWN" 3 "FAULT";
VAL_ 545 VCFRONT_amplifierLVRequest 0 "OFF" 1 "ON" 2 "GOING_DOWN" 3 "FAULT";
VAL_ 545 VCFRONT_das1HighCurrentLVState 0 "OFF" 1 "ON" 2 "GOING_DOWN" 3 "FAULT";
VAL_ 545 VCFRONT_das2HighCurrentLVState 0 "OFF" 1 "ON" 2 "GOING_DOWN" 3 "FAULT";
VAL_ 545 VCFRONT_diLVRequest 0 "OFF" 1 "ON" 2 "GOING_DOWN" 3 "FAULT";
VAL_ 545 VCFRONT_disLVState 0 "OFF" 1 "ON" 2 "GOING_DOWN" 3 "FAULT";
VAL_ 545 VCFRONT_oilPumpFrontLVState 0 "OFF" 1 "ON" 2 "GOING_DOWN" 3 "FAULT";
VAL_ 545 VCFRONT_oilPumpRearLVRequest 0 "OFF" 1 "ON" 2 "GOING_DOWN" 3 "FAULT";
VAL_ 545 VCFRONT_ocsLVRequest 0 "OFF" 1 "ON" 2 "GOING_DOWN" 3 "FAULT";
VAL_ 545 VCFRONT_vcleftHiCurrentLVState 0 "OFF" 1 "ON" 2 "GOING_DOWN" 3 "FAULT";
VAL_ 545 VCFRONT_vcrightHiCurrentLVState 0 "OFF" 1 "ON" 2 "GOING_DOWN" 3 "FAULT";
VAL_ 545 VCFRONT_uiHiCurrentLVState 0 "OFF" 1 "ON" 2 "GOING_DOWN" 3 "FAULT";
VAL_ 545 VCFRONT_uiAudioLVState 0 "OFF" 1 "ON" 2 "GOING_DOWN" 3 "FAULT";
VAL_ 545 VCFRONT_cpLVRequest 0 "OFF" 1 "ON" 2 "GOING_DOWN" 3 "FAULT";
VAL_ 545 VCFRONT_epasLVState 0 "OFF" 1 "ON" 2 "GOING_DOWN" 3 "FAULT";
VAL_ 545 VCFRONT_hvcLVRequest 0 "OFF" 1 "ON" 2 "GOING_DOWN" 3 "FAULT";
VAL_ 545 VCFRONT_tasLVState 0 "OFF" 1 "ON" 2 "GOING_DOWN" 3 "FAULT";
VAL_ 545 VCFRONT_pcsLVState 0 "OFF" 1 "ON" 2 "GOING_DOWN" 3 "FAULT";

VAL_ 832 VCFRONT_matrixIndex 0 "AlertMatrix0" 1 "AlertMatrix1" 2 "AlertMatrix2" 3 "AlertMatrix3" 4 "AlertMatrix4";

VAL_ 577 VCFRONT_coolantAirPurgeBatState 0 "INACTIVE" 1 "ACTIVE" 2 "COMPLETE" 3 "INTERRUPTED" 4 "PENDING";
VAL_ 577 VCFRONT_coolantFlowBatReason 0 "NONE" 1 "COOLANT_AIR_PURGE" 2 "NO_FLOW_REQ" 3 "OVERRIDE_BATT" 4 "ACTIVE_MANAGER_BATT" 5 "PASSIVE_MANAGER_BATT" 6 "BMS_FLOW_REQ" 7 "DAS_FLOW_REQ" 8 "OVERRIDE_PT" 9 "ACTIVE_MANAGER_PT" 10 "PASSIVE_MANAGER_PT" 11 "PCS_FLOW_REQ" 12 "DI_FLOW_REQ" 13 "DIS_FLOW_REQ";
VAL_ 577 VCFRONT_coolantFlowPTReason 0 "NONE" 1 "COOLANT_AIR_PURGE" 2 "NO_FLOW_REQ" 3 "OVERRIDE_BATT" 4 "ACTIVE_MANAGER_BATT" 5 "PASSIVE_MANAGER_BATT" 6 "BMS_FLOW_REQ" 7 "DAS_FLOW_REQ" 8 "OVERRIDE_PT" 9 "ACTIVE_MANAGER_PT" 10 "PASSIVE_MANAGER_PT" 11 "PCS_FLOW_REQ" 12 "DI_FLOW_REQ" 13 "DIS_FLOW_REQ";
VAL_ 577 VCFRONT_wasteHeatRequestType 0 "NONE" 1 "PARTIAL" 2 "FULL";

VAL_ 753 VCFRONT_eFuseDebugStatusIndex 0 "VCRIGHT" 1 "VCLEFT" 2 "PCS" 3 "IBOOSTER" 4 "EPAS3P" 5 "EPAS3S" 6 "ESP_MOTOR" 7 "ESP_VALVE" 8 "AUTOPILOT_1" 9 "AUTOPILOT_2" 10 "SLEEP_BYPASS" 11 "UI" 12 "HEADLAMPS" 13 "VBAT_FUSED_HIGH_CURRENT" 14 "PUMPS" 15 "RAILS_A_B" 16 "MISC_RAILS" 17 "INVALID";
VAL_ 753 VCFRONT_rightControllerState 0 "OFF" 1 "ON" 2 "LOCKED_OUT";
VAL_ 753 VCFRONT_vcrightSelfTestResult 0 "NOT_RUN" 1 "PASSED" 2 "FAILED_EFUSE_OUTPUT_SHORT" 3 "FAILED_POWER_FET_STUCK_ON" 4 "FAILED_ENABLE_LOW_MALFUNCTION" 5 "FAILED_POWER_FET_CHANNEL_OPEN" 6 "FAILED_ENABLE_HIGH_MALFUNCTION" 7 "FAILED_TURN_OFF_PATH_TOO_SLOW" 8 "FAILED_NOT_LATCHED" 9 "SKIPPED";
VAL_ 753 VCFRONT_leftControllerState 0 "OFF" 1 "ON" 2 "LOCKED_OUT";
VAL_ 753 VCFRONT_vcleftSelfTestResult 0 "NOT_RUN" 1 "PASSED" 2 "FAILED_EFUSE_OUTPUT_SHORT" 3 "FAILED_POWER_FET_STUCK_ON" 4 "FAILED_ENABLE_LOW_MALFUNCTION" 5 "FAILED_POWER_FET_CHANNEL_OPEN" 6 "FAILED_ENABLE_HIGH_MALFUNCTION" 7 "FAILED_TURN_OFF_PATH_TOO_SLOW" 8 "FAILED_NOT_LATCHED" 9 "SKIPPED";
VAL_ 753 VCFRONT_PCSState 0 "OFF" 1 "ON" 2 "LOCKED_OUT";
VAL_ 753 VCFRONT_pcsSelfTestResult 0 "NOT_RUN" 1 "PASSED" 2 "FAILED_EFUSE_OUTPUT_SHORT" 3 "FAILED_POWER_FET_STUCK_ON" 4 "FAILED_ENABLE_LOW_MALFUNCTION" 5 "FAILED_POWER_FET_CHANNEL_OPEN" 6 "FAILED_ENABLE_HIGH_MALFUNCTION" 7 "FAILED_TURN_OFF_PATH_TOO_SLOW" 8 "FAILED_NOT_LATCHED" 9 "SKIPPED";
VAL_ 753 VCFRONT_iBoosterState 0 "OFF" 1 "ON" 2 "LOCKED_OUT";
VAL_ 753 VCFRONT_iBoosterSelfTestResult 0 "NOT_RUN" 1 "PASSED" 2 "FAILED_EFUSE_OUTPUT_SHORT" 3 "FAILED_POWER_FET_STUCK_ON" 4 "FAILED_ENABLE_LOW_MALFUNCTION" 5 "FAILED_POWER_FET_CHANNEL_OPEN" 6 "FAILED_ENABLE_HIGH_MALFUNCTION" 7 "FAILED_TURN_OFF_PATH_TOO_SLOW" 8 "FAILED_NOT_LATCHED" 9 "SKIPPED";
VAL_ 753 VCFRONT_EPAS3PState 0 "OFF" 1 "ON" 2 "LOCKED_OUT";
VAL_ 753 VCFRONT_EPAS3PSelfTestResult 0 "NOT_RUN" 1 "PASSED" 2 "FAILED_EFUSE_OUTPUT_SHORT" 3 "FAILED_POWER_FET_STUCK_ON" 4 "FAILED_ENABLE_LOW_MALFUNCTION" 5 "FAILED_POWER_FET_CHANNEL_OPEN" 6 "FAILED_ENABLE_HIGH_MALFUNCTION" 7 "FAILED_TURN_OFF_PATH_TOO_SLOW" 8 "FAILED_NOT_LATCHED" 9 "SKIPPED";
VAL_ 753 VCFRONT_EPAS3SState 0 "OFF" 1 "ON" 2 "LOCKED_OUT";
VAL_ 753 VCFRONT_EPAS3SSelfTestResult 0 "NOT_RUN" 1 "PASSED" 2 "FAILED_EFUSE_OUTPUT_SHORT" 3 "FAILED_POWER_FET_STUCK_ON" 4 "FAILED_ENABLE_LOW_MALFUNCTION" 5 "FAILED_POWER_FET_CHANNEL_OPEN" 6 "FAILED_ENABLE_HIGH_MALFUNCTION" 7 "FAILED_TURN_OFF_PATH_TOO_SLOW" 8 "FAILED_NOT_LATCHED" 9 "SKIPPED";
VAL_ 753 VCFRONT_ESPMotorState 0 "OFF" 1 "ON" 2 "LOCKED_OUT";
VAL_ 753 VCFRONT_ESPMotorSelfTestResult 0 "NOT_RUN" 1 "PASSED" 2 "FAILED_EFUSE_OUTPUT_SHORT" 3 "FAILED_POWER_FET_STUCK_ON" 4 "FAILED_ENABLE_LOW_MALFUNCTION" 5 "FAILED_POWER_FET_CHANNEL_OPEN" 6 "FAILED_ENABLE_HIGH_MALFUNCTION" 7 "FAILED_TURN_OFF_PATH_TOO_SLOW" 8 "FAILED_NOT_LATCHED" 9 "SKIPPED";
VAL_ 753 VCFRONT_ESPValveState 0 "OFF" 1 "ON" 2 "LOCKED_OUT";
VAL_ 753 VCFRONT_autopilot1State 0 "OFF" 1 "ON" 2 "LOCKED_OUT";
VAL_ 753 VCFRONT_autopilot2State 0 "OFF" 1 "ON" 2 "LOCKED_OUT";
VAL_ 753 VCFRONT_headlampLeftVoltage 255 "SNA";
VAL_ 753 VCFRONT_headlampRightVoltage 255 "SNA";
VAL_ 753 VCFRONT_headlampLeftTemperature -128 "SNA";
VAL_ 753 VCFRONT_headlampRightTemperature -128 "SNA";
VAL_ 753 VCFRONT_vbatFusedSelfTestResult 0 "NOT_RUN" 1 "PASSED" 2 "FAILED_EFUSE_OUTPUT_SHORT" 3 "FAILED_POWER_FET_STUCK_ON" 4 "FAILED_ENABLE_LOW_MALFUNCTION" 5 "FAILED_POWER_FET_CHANNEL_OPEN" 6 "FAILED_ENABLE_HIGH_MALFUNCTION" 7 "FAILED_TURN_OFF_PATH_TOO_SLOW" 8 "FAILED_NOT_LATCHED" 9 "SKIPPED";

VAL_ 1009 VCFRONT_DRLLeftStatus 0 "OFF" 1 "ON" 2 "FAULT" 3 "SNA";
VAL_ 1009 VCFRONT_DRLRightStatus 0 "OFF" 1 "ON" 2 "FAULT" 3 "SNA";
VAL_ 1009 VCFRONT_ambientLightingBrightnes 255 "SNA";
VAL_ 1009 VCFRONT_fogLeftStatus 0 "OFF" 1 "ON" 2 "FAULT" 3 "SNA";
VAL_ 1009 VCFRONT_fogRightStatus 0 "OFF" 1 "ON" 2 "FAULT" 3 "SNA";
VAL_ 1009 VCFRONT_hazardLightRequest 0 "NONE" 1 "BUTTON" 2 "LOCK" 3 "UNLOCK" 4 "MISLOCK" 5 "CRASH" 6 "CAR_ALARM" 7 "DAS";
VAL_ 1009 VCFRONT_highBeamLeftStatus 0 "OFF" 1 "ON" 2 "FAULT" 3 "SNA";
VAL_ 1009 VCFRONT_highBeamRightStatus 0 "OFF" 1 "ON" 2 "FAULT" 3 "SNA";
VAL_ 1009 VCFRONT_indicatorLeftRequest 0 "OFF" 1 "ACTIVE_LOW" 2 "ACTIVE_HIGH";
VAL_ 1009 VCFRONT_indicatorRightRequest 0 "OFF" 1 "ACTIVE_LOW" 2 "ACTIVE_HIGH";
VAL_ 1009 VCFRONT_lowBeamLeftStatus 0 "OFF" 1 "ON" 2 "FAULT" 3 "SNA";
VAL_ 1009 VCFRONT_lowBeamRightStatus 0 "OFF" 1 "ON" 2 "FAULT" 3 "SNA";
VAL_ 1009 VCFRONT_parkLeftStatus 0 "OFF" 1 "ON" 2 "FAULT" 3 "SNA";
VAL_ 1009 VCFRONT_parkRightStatus 0 "OFF" 1 "ON" 2 "FAULT" 3 "SNA";
VAL_ 1009 VCFRONT_sideMarkersStatus 0 "OFF" 1 "ON" 2 "FAULT" 3 "SNA";
VAL_ 1009 VCFRONT_sideRepeaterLeftStatus 0 "OFF" 1 "ON" 2 "FAULT" 3 "SNA";
VAL_ 1009 VCFRONT_sideRepeaterRightStatus 0 "OFF" 1 "ON" 2 "FAULT" 3 "SNA";
VAL_ 1009 VCFRONT_simLatchingStalk 0 "IDLE" 1 "LEFT" 2 "RIGHT" 3 "SNA";
VAL_ 1009 VCFRONT_switchLightingBrightness 255 "SNA";
VAL_ 1009 VCFRONT_turnSignalLeftStatus 0 "OFF" 1 "ON" 2 "FAULT" 3 "SNA";
VAL_ 1009 VCFRONT_turnSignalRightStatus 0 "OFF" 1 "ON" 2 "FAULT" 3 "SNA";

VAL_ 705 VCFRONT_logging10HzIndex 0 "COOLANT_PUMPS" 1 "THERMAL_FAN" 2 "FIVE_WAY_VALVE" 3 "REFRIGERANT_LV8907" 4 "COMPRESSOR" 5 "EXV_EVAP_SOLENOID_AIRFLOW" 6 "END";
VAL_ 705 VCFRONT_pumpBatteryRPMTarget 1023 "SNA";
VAL_ 705 VCFRONT_pumpPowertrainRPMTarget 1023 "SNA";
VAL_ 705 VCFRONT_radiatorFanRPMTarget 1023 "SNA";
VAL_ 705 VCFRONT_coolantTempBasedMode 0 "SERIES" 1 "PARALLEL";
VAL_ 897 VCFRONT_tempRefrigSuction 255 "SNA";
VAL_ 705 VCFRONT_tempDischargeSimulated 2047 "SNA";
VAL_ 705 VCFRONT_exvMotorState 0 "UNPOWERED" 1 "HARD_RESET_SETUP" 2 "HARD_RESET" 3 "INIT_SPI" 4 "SPI_ERROR" 5 "ENABLE_MOTOR" 6 "READY" 7 "STALL" 8 "FAULT_SHORT_COIL" 9 "FAULT_OPEN_COIL" 10 "DRIVER_FAULT" 11 "SPI_COMMS_DOWN";

VAL_ 897 VCFRONT_logging1HzIndex 0 "COOLANT" 1 "CONDENSER_LOUVER_IC" 2 "ACTIVE_LOUVER_AND_BRUSHLESS_FETS" 3 "FIVE_WAY_VALVE" 4 "END";
VAL_ 897 VCFRONT_modeTransitionID 0 "PARALLEL_F1_noFlowRequest" 1 "SERIES_F2_faultPumps" 2 "SERIES_1_drive_batteryWantsCool" 3 "SERIES_2_drive_batteryNeedsHeat" 4 "SERIES_3_drive_batteryWantsHeat" 5 "PARALLEL_2_drive_batteryWantsHeat" 6 "PARALLEL_3_drive_batteryWantsCool" 7 "PARALLEL_4_drive_batteryNeedsCool" 8 "SERIES_4_charge_batteryNeedsHeat" 9 "SERIES_5_charge_batteryWantsHeat" 10 "PARALLEL_5_charge_batteryWantsHeat" 11 "PARALLEL_6_charge_batteryWantsCool" 12 "SERIES_6_fastCharge_batteryNeedsHeat" 13 "SERIES_7_fastCharge_batteryWantsCool" 14 "PARALLEL_7_fastCharge_batteryWantsCool" 15 "PARALLEL_8_fastCharge_batteryWantsHeat" 16 "SERIES_8_preConditioning_batteryNeedsHeat" 17 "SERIES_9_drive_driveUnitThermalLimiting" 18 "PARALLEL_9_drive_batteryThermalLimiting" 19 "INIT" 20 "OVERRIDE" 21 "UNDEFINED";
VAL_ 897 VCFRONT_modeDesired 0 "SERIES" 1 "PARALLEL";
VAL_ 705 VCFRONT_activeLouverMotorState 0 "UNPOWERED" 1 "INIT_I2C" 2 "INIT_EEPROM" 3 "I2C_ERROR" 4 "READY" 5 "BRAKE" 6 "STALL" 7 "FAULT_MOTOR_DISCONNECTED" 8 "DRIVER_FAULT";
VAL_ 705 VCFRONT_activeLouverState 0 "UNCALIBRATED" 1 "CALIB_CLOSE" 2 "CALIB_OPEN" 3 "READY" 4 "FAULTED";
VAL_ 897 VCFRONT_pumpBatteryFETTemp 255 "SNA";
VAL_ 897 VCFRONT_pumpPowertrainFETTemp 255 "SNA";
VAL_ 897 VCFRONT_radiatorFanFETTemp 255 "SNA";

VAL_ 737 VCFRONT_statusIndex 0 "BODY_CONTROLS" 1 "VEHICLE_AND_RAILS" 2 "HOMELINK" 3 "REFRIGERANT_SYSTEM" 4 "LV_BATTERY_DEBUG" 5 "INVALID";
VAL_ 737 VCFRONT_frunkLatchStatus 0 "SNA" 1 "OPENED" 2 "CLOSED" 3 "CLOSING" 4 "OPENING" 5 "AJAR" 6 "TIMEOUT" 7 "DEFAULT" 8 "FAULT";
VAL_ 737 VCFRONT_wiperSpeed 0 "SNA" 1 "OFF" 2 "1" 3 "2" 4 "3" 5 "4" 6 "5" 7 "LOW" 8 "HIGH";
VAL_ 737 VCFRONT_wiperPosition 0 "SNA" 1 "SERVICE" 2 "DEPRESSED_PARK" 3 "DELAYED_REST" 4 "WIPING";
VAL_ 737 VCFRONT_wiperState 0 "SNA" 1 "SERVICE" 2 "FAULT" 3 "DELAYED_REST" 4 "PARK" 5 "WASH" 6 "MOMENTARY_WIPE" 7 "INTERMITTENT_HIGH" 8 "INTERMITTENT_LOW" 9 "CONT_FAST" 10 "CONT_SLOW" 11 "INT_AUTO_LOW" 12 "INT_AUTO_HIGH";
VAL_ 737 VCFRONT_crashDetectedType 0 "NONE" 1 "MINOR" 2 "SEVERE";
VAL_ 737 VCFRONT_crashState 0 "IDLE" 1 "MINOR" 2 "SEVERE";
VAL_ 737 VCFRONT_airCompressorStatus 0 "OFF" 1 "ON" 2 "TURNING_OFF" 3 "TURNING_ON" 4 "FAULT" 5 "RETRY_AVAILABLE" 7 "SNA";
VAL_ 737 VCFRONT_iBoosterStateDBG 0 "OFF" 1 "ON" 2 "GOING_DOWN" 3 "WRITING_DATA_SHUTDOWN" 4 "FORCE_OFF";
VAL_ 737 VCFRONT_vehicleStatusDBG 0 "INIT" 1 "LOW_POWER_STANDBY" 2 "SILENT_WAKE" 3 "BATTERY_POST_WAKE" 4 "SYSTEM_CHECKS" 5 "SLEEP_SHUTDOWN" 6 "SLEEP_STANDBY" 7 "LV_SHUTDOWN" 8 "LV_AWAKE" 9 "HV_UP_STANDBY" 10 "ACCESSORY" 11 "ACCESSORY_PLUS" 12 "CONDITIONING" 13 "DRIVE" 14 "CRASH" 15 "OTA" 16 "TURN_ON_RAILS" 17 "RESET";
VAL_ 737 VCFRONT_batterySMState 0 "INIT" 1 "CHARGE" 2 "DISCHARGE" 3 "STANDBY" 4 "RESISTANCE_ESTIMATION" 5 "OTA_STANDBY" 6 "DISCONNECTED_BATTERY_TEST" 7 "FAULT";
VAL_ 737 VCFRONT_homelinkCommStatus 0 "SNA" 1 "OFF" 2 "ON" 3 "FAULT";
VAL_ 737 VCFRONT_pressureRefrigSuction 127 "SNA";
VAL_ 737 VCFRONT_pressureRefrigDischarge 255 "SNA";
VAL_ 737 VCFRONT_AS8510Voltage 4095 "SNA";

VAL_ 864 VCLEFT_matrixIndex 0 "AlertMatrix0" 1 "AlertMatrix1" 2 "AlertMatrix2" 3 "AlertMatrix3" 4 "AlertMatrix4" 5 "AlertMatrix5";

VAL_ 258 VCLEFT_frontLatchStatus 0 "SNA" 1 "OPENED" 2 "CLOSED" 3 "CLOSING" 4 "OPENING" 5 "AJAR" 6 "TIMEOUT" 7 "DEFAULT" 8 "FAULT";
VAL_ 258 VCLEFT_mirrorFoldState 0 "UNKNOWN" 1 "FOLDED" 2 "UNFOLDED" 3 "FOLDING" 4 "UNFOLDING";
VAL_ 258 VCLEFT_mirrorHeatState 0 "SNA" 1 "ON" 2 "OFF" 3 "OFF_UNAVAILABLE" 4 "FAULT";
VAL_ 258 VCLEFT_mirrorRecallState 0 "INIT" 1 "RECALLING_AXIS_1" 2 "RECALLING_AXIS_2" 3 "RECALLING_COMPLETE" 4 "RECALLING_FAILED" 5 "RECALLING_STOPPED";
VAL_ 258 VCLEFT_mirrorState 0 "IDLE" 1 "TILT_X" 2 "TILT_Y" 3 "FOLD_UNFOLD" 4 "RECALL";
VAL_ 258 VCLEFT_rearLatchStatus 0 "SNA" 1 "OPENED" 2 "CLOSED" 3 "CLOSING" 4 "OPENING" 5 "AJAR" 6 "TIMEOUT" 7 "DEFAULT" 8 "FAULT";

VAL_ 626 VCLEFT_epbmDebugIndex 0 "STATES" 1 "TRANSITIONS";
VAL_ 626 VCLEFT_epbmCaliperState 0 "UNSAVED" 1 "UNKNOWN" 2 "REAPPLY" 3 "PARK" 4 "OPEN" 5 "SERVICE";
VAL_ 626 VCLEFT_summonFaultReason 0 "NONE" 1 "DI_MIA" 2 "DAS_MIA" 3 "ESP_MIA" 4 "EPBM_MIA" 5 "DI_FAULT" 6 "DI_APC_FAULT" 7 "DAS_FAULT" 8 "ESP_FAULT" 9 "VEH_CAN_FAULT" 10 "EAC_NOT_ALLOWED" 11 "EPBM_REQUEST" 12 "SPEED" 13 "EXTERNAL" 14 "PARK_MIA" 15 "PM_MIA" 16 "PM_REQUEST" 17 "OOC" 18 "MISMATCH" 19 "EPB_FAULT" 20 "DI_STATE_INVALID" 21 "PASSIVE_REQUEST" 22 "EPBREMOTE_MIA" 23 "REMOTE_SUMMON_FAULTED" 24 "LOCAL_UNIT_FAULTED" 25 "REMOTE_UNIT_FAULTED" 26 "START_IN_UNAVAILABLE" 27 "INVALID_REMOTE_STATE" 28 "REMOTE_DID_NOT_START";
VAL_ 626 VCLEFT_epbSummonState 0 "INIT" 1 "IDLE" 2 "ARMED" 3 "ACTIVE" 4 "COMPLETE" 5 "FAULT" 6 "UNAVAILABLE";
VAL_ 626 VCLEFT_epbmSummonState 0 "INIT" 1 "IDLE" 2 "ARMED" 3 "ACTIVE" 4 "COMPLETE" 5 "FAULT" 6 "UNAVAILABLE";
VAL_ 626 VCLEFT_epbmUnitStatus 0 "UNKNOWN" 1 "OPEN" 2 "DYNAMIC" 3 "PARK" 4 "START" 5 "SERVICE" 6 "WINCHMODE" 7 "WINCHMODE_RELEASING" 8 "PARKING" 9 "DYNAMIC_APPLYING" 10 "RELEASING" 11 "SERVICE_RELEASING" 12 "PARK_PENDING" 13 "WINCHMODE_PENDING" 14 "SUMMON" 15 "SUMMON_RELEASING" 16 "SUMMON_PARKING" 17 "EXTERNAL_DYNAMIC" 18 "RELEASING_FOR_EXTERNAL_PARK" 19 "EXTERNAL_PARKING" 20 "DYNAMIC_PARKING" 21 "COUNT";
VAL_ 626 VCLEFT_epbUnitStatus 0 "UNKNOWN" 1 "OPEN" 2 "DYNAMIC" 3 "PARK" 4 "START" 5 "SERVICE" 6 "WINCHMODE" 7 "WINCHMODE_RELEASING" 8 "PARKING" 9 "DYNAMIC_APPLYING" 10 "RELEASING" 11 "SERVICE_RELEASING" 12 "PARK_PENDING" 13 "WINCHMODE_PENDING" 14 "SUMMON" 15 "SUMMON_RELEASING" 16 "SUMMON_PARKING" 17 "EXTERNAL_DYNAMIC" 18 "RELEASING_FOR_EXTERNAL_PARK" 19 "EXTERNAL_PARKING" 20 "DYNAMIC_PARKING" 21 "COUNT";
VAL_ 626 VCLEFT_epbmFaultStatus 0 "NOMINAL" 1 "RETRY" 2 "FAULT" 3 "FAULT_IDLE";
VAL_ 626 VCLEFT_epbFaultStatus 0 "NOMINAL" 1 "RETRY" 2 "FAULT" 3 "FAULT_IDLE";
VAL_ 626 VCLEFT_cdpEnumDummy 0 "IDLE" 1 "VALID" 2 "INVALID";

VAL_ 642 VCLEFT_blowerIndex 0 "FEEDBACK_SIGNALS" 1 "VARS";
VAL_ 642 VCLEFT_hvacBlowerOutputDuty 127 "SNA";
VAL_ 642 VCLEFT_hvacBlowerRPMTarget 1023 "SNA";
VAL_ 642 VCLEFT_hvacBlowerTorque -128 "SNA";
VAL_ 642 VCLEFT_hvacBlowerFETTemp 255 "SNA";
VAL_ 642 VCLEFT_hvacBlowerITerm 255 "SNA";
VAL_ 642 VCLEFT_hvacBlowerRs 255 "SNA";
VAL_ 642 VCLEFT_hvacBlowerIPhase0 255 "SNA";
VAL_ 642 VCLEFT_hvacBlowerIPhase1 255 "SNA";
VAL_ 642 VCLEFT_hvacBlowerIPhase2 255 "SNA";

VAL_ 1860 VCLEFT_columnRecallStatus 0 "SNA" 1 "IN_PROGRESS" 2 "COMPLETE" 3 "INTERRUPTED";
VAL_ 1860 VCLEFT_mirrorRecallStatus 0 "SNA" 1 "IN_PROGRESS" 2 "COMPLETE" 3 "INTERRUPTED";
VAL_ 1860 VCLEFT_seatRecallStatus 0 "SNA" 1 "IN_PROGRESS" 2 "COMPLETE" 3 "INTERRUPTED";
VAL_ 1860 VCLEFT_systemRecallStatus 0 "SNA" 1 "IN_PROGRESS" 2 "COMPLETE" 3 "INTERRUPTED";

VAL_ 778 VCLEFT_frontBuckleStatus 0 "UNLATCHED" 1 "LATCHED" 2 "FAULTED" 3 "SNA";
VAL_ 778 VCLEFT_frontOccupancyStatus 0 "UNOCCUPIED" 1 "OCCUPIED" 2 "OCCUPANCY_FAULTED" 3 "NOT_CONFIGURED" 7 "OCCUPANCY_SNA";
VAL_ 778 VCLEFT_rearCenterOccupancyStatus 0 "UNOCCUPIED" 1 "OCCUPIED" 2 "OCCUPANCY_FAULTED" 3 "OCCUPANCY_SNA";
VAL_ 778 VCLEFT_rearLeftBuckleStatus 0 "UNLATCHED" 1 "LATCHED" 2 "FAULTED" 3 "SNA";
VAL_ 778 VCLEFT_rearLeftOccupancyStatus 0 "UNOCCUPIED" 1 "OCCUPIED" 2 "OCCUPANCY_FAULTED" 3 "OCCUPANCY_SNA";
VAL_ 778 VCLEFT_rearRightOccupancyStatus 0 "UNOCCUPIED" 1 "OCCUPIED" 2 "OCCUPANCY_FAULTED" 3 "OCCUPANCY_SNA";

VAL_ 930 VCLEFT_statusIndex 0 "MUX0" 1 "MUX1";
VAL_ 930 VCLEFT_vehiclePowerStateDBG 0 "OFF" 1 "CONDITIONING" 2 "ACCESSORY" 3 "DRIVE";
VAL_ 930 VCLEFT_swcInputVoltage 255 "SNA";
VAL_ 930 VCLEFT_swcPCBATemperature -128 "SNA";
VAL_ 930 VCLEFT_tlcPCBATemperature -128 "SNA";

VAL_ 962 VCLEFT_switchStatusIndex 0 "0" 1 "1" 2 "INVALID";
VAL_ 962 VCLEFT_rightMirrorTilt 0 "STOP" 1 "DOWN" 2 "UP" 3 "RIGHT" 4 "LEFT";
VAL_ 962 VCLEFT_frontSeatTrackBack 0 "SNA" 1 "OFF" 2 "ON" 3 "FAULT";
VAL_ 962 VCLEFT_frontSeatTrackForward 0 "SNA" 1 "OFF" 2 "ON" 3 "FAULT";
VAL_ 962 VCLEFT_frontSeatTiltDown 0 "SNA" 1 "OFF" 2 "ON" 3 "FAULT";
VAL_ 962 VCLEFT_frontSeatTiltUp 0 "SNA" 1 "OFF" 2 "ON" 3 "FAULT";
VAL_ 962 VCLEFT_frontSeatLiftDown 0 "SNA" 1 "OFF" 2 "ON" 3 "FAULT";
VAL_ 962 VCLEFT_frontSeatLiftUp 0 "SNA" 1 "OFF" 2 "ON" 3 "FAULT";
VAL_ 962 VCLEFT_frontSeatBackrestBack 0 "SNA" 1 "OFF" 2 "ON" 3 "FAULT";
VAL_ 962 VCLEFT_frontSeatBackrestForward 0 "SNA" 1 "OFF" 2 "ON" 3 "FAULT";
VAL_ 962 VCLEFT_frontSeatLumbarDown 0 "SNA" 1 "OFF" 2 "ON" 3 "FAULT";
VAL_ 962 VCLEFT_frontSeatLumbarUp 0 "SNA" 1 "OFF" 2 "ON" 3 "FAULT";
VAL_ 962 VCLEFT_frontSeatLumbarIn 0 "SNA" 1 "OFF" 2 "ON" 3 "FAULT";
VAL_ 962 VCLEFT_frontSeatLumbarOut 0 "SNA" 1 "OFF" 2 "ON" 3 "FAULT";
VAL_ 962 VCLEFT_frontBuckleSwitch 0 "SNA" 1 "OFF" 2 "ON" 3 "FAULT";
VAL_ 962 VCLEFT_frontOccupancySwitch 0 "SNA" 1 "OFF" 2 "ON" 3 "FAULT";
VAL_ 962 VCLEFT_rearLeftBuckleSwitch 0 "SNA" 1 "OFF" 2 "ON" 3 "FAULT";
VAL_ 962 VCLEFT_rearCenterOccupancySwitch 0 "SNA" 1 "OFF" 2 "ON" 3 "FAULT";
VAL_ 962 VCLEFT_rearLeftOccupancySwitch 0 "SNA" 1 "OFF" 2 "ON" 3 "FAULT";
VAL_ 962 VCLEFT_rearRightOccupancySwitch 0 "SNA" 1 "OFF" 2 "ON" 3 "FAULT";
VAL_ 962 VCLEFT_swcLeftTiltRight 0 "SNA" 1 "OFF" 2 "ON" 3 "FAULT";
VAL_ 962 VCLEFT_swcLeftPressed 0 "SNA" 1 "OFF" 2 "ON" 3 "FAULT";
VAL_ 962 VCLEFT_swcRightTiltLeft 0 "SNA" 1 "OFF" 2 "ON" 3 "FAULT";
VAL_ 962 VCLEFT_swcRightTiltRight 0 "SNA" 1 "OFF" 2 "ON" 3 "FAULT";
VAL_ 962 VCLEFT_swcRightPressed 0 "SNA" 1 "OFF" 2 "ON" 3 "FAULT";
VAL_ 962 VCLEFT_swcLeftTiltLeft 0 "SNA" 1 "OFF" 2 "ON" 3 "FAULT";

VAL_ 960 VCRIGHT_matrixIndex 0 "AlertMatrix0" 1 "AlertMatrix1" 2 "AlertMatrix2" 3 "AlertMatrix3" 4 "AlertMatrix4" 5 "AlertMatrix5";

VAL_ 1795 VCRIGHT_debugThermal10HzIndex 0 "heaterAndEvapWatts" 1 "temps" 2 "airflow" 3 "cabinModel" 4 "actuatorStatus" 5 "END";
VAL_ 1795 VCRIGHT_tempEvapAdjustmentLeft 255 "SNA";
VAL_ 1795 VCRIGHT_tempEvapAdjustmentRight 255 "SNA";
VAL_ 1795 VCRIGHT_cabinTempThs 255 "SNA";
VAL_ 1795 VCRIGHT_cabinTempThsBracket 255 "SNA";
VAL_ 1795 VCRIGHT_cabinTempProbe 255 "SNA";
VAL_ 1795 VCRIGHT_setTempAdjustmentLeft 255 "SNA";
VAL_ 1795 VCRIGHT_setTempAdjustmentRight 255 "SNA";

VAL_ 259 VCRIGHT_frontLatchStatus 0 "SNA" 1 "OPENED" 2 "CLOSED" 3 "CLOSING" 4 "OPENING" 5 "AJAR" 6 "TIMEOUT" 7 "DEFAULT" 8 "FAULT";
VAL_ 259 VCRIGHT_mirrorFoldState 0 "UNKNOWN" 1 "FOLDED" 2 "UNFOLDED" 3 "FOLDING" 4 "UNFOLDING";
VAL_ 259 VCRIGHT_mirrorRecallState 0 "INIT" 1 "RECALLING_AXIS_1" 2 "RECALLING_AXIS_2" 3 "RECALLING_COMPLETE" 4 "RECALLING_FAILED" 5 "RECALLING_STOPPED";
VAL_ 259 VCRIGHT_mirrorState 0 "IDLE" 1 "TILT_X" 2 "TILT_Y" 3 "FOLD_UNFOLD" 4 "RECALL";
VAL_ 259 VCRIGHT_rearLatchStatus 0 "SNA" 1 "OPENED" 2 "CLOSED" 3 "CLOSING" 4 "OPENING" 5 "AJAR" 6 "TIMEOUT" 7 "DEFAULT" 8 "FAULT";
VAL_ 259 VCRIGHT_trunkLatchStatus 0 "SNA" 1 "OPENED" 2 "CLOSED" 3 "CLOSING" 4 "OPENING" 5 "AJAR" 6 "TIMEOUT" 7 "DEFAULT" 8 "FAULT";

VAL_ 915 VCRIGHT_epbmDebugIndex 0 "STATES" 1 "TRANSITIONS";
VAL_ 915 VCRIGHT_epbmCaliperState 0 "UNSAVED" 1 "UNKNOWN" 2 "REAPPLY" 3 "PARK" 4 "OPEN" 5 "SERVICE";
VAL_ 915 VCRIGHT_summonFaultReason 0 "NONE" 1 "DI_MIA" 2 "DAS_MIA" 3 "ESP_MIA" 4 "EPBM_MIA" 5 "DI_FAULT" 6 "DI_APC_FAULT" 7 "DAS_FAULT" 8 "ESP_FAULT" 9 "VEH_CAN_FAULT" 10 "EAC_NOT_ALLOWED" 11 "EPBM_REQUEST" 12 "SPEED" 13 "EXTERNAL" 14 "PARK_MIA" 15 "PM_MIA" 16 "PM_REQUEST" 17 "OOC" 18 "MISMATCH" 19 "EPB_FAULT" 20 "DI_STATE_INVALID" 21 "PASSIVE_REQUEST" 22 "EPBREMOTE_MIA" 23 "REMOTE_SUMMON_FAULTED" 24 "LOCAL_UNIT_FAULTED" 25 "REMOTE_UNIT_FAULTED" 26 "START_IN_UNAVAILABLE" 27 "INVALID_REMOTE_STATE" 28 "REMOTE_DID_NOT_START";
VAL_ 915 VCRIGHT_epbSummonState 0 "INIT" 1 "IDLE" 2 "ARMED" 3 "ACTIVE" 4 "COMPLETE" 5 "FAULT" 6 "UNAVAILABLE";
VAL_ 915 VCRIGHT_epbmSummonState 0 "INIT" 1 "IDLE" 2 "ARMED" 3 "ACTIVE" 4 "COMPLETE" 5 "FAULT" 6 "UNAVAILABLE";
VAL_ 915 VCRIGHT_epbUnitStatus 0 "UNKNOWN" 1 "OPEN" 2 "DYNAMIC" 3 "PARK" 4 "START" 5 "SERVICE" 6 "WINCHMODE" 7 "WINCHMODE_RELEASING" 8 "PARKING" 9 "DYNAMIC_APPLYING" 10 "RELEASING" 11 "SERVICE_RELEASING" 12 "PARK_PENDING" 13 "WINCHMODE_PENDING" 14 "SUMMON" 15 "SUMMON_RELEASING" 16 "SUMMON_PARKING" 17 "EXTERNAL_DYNAMIC" 18 "RELEASING_FOR_EXTERNAL_PARK" 19 "EXTERNAL_PARKING" 20 "DYNAMIC_PARKING" 21 "COUNT";
VAL_ 915 VCRIGHT_epbmFaultStatus 0 "NOMINAL" 1 "RETRY" 2 "FAULT" 3 "FAULT_IDLE";
VAL_ 915 VCRIGHT_epbFaultStatus 0 "NOMINAL" 1 "RETRY" 2 "FAULT" 3 "FAULT_IDLE";
VAL_ 915 VCRIGHT_cdpEnumDummy 0 "IDLE" 1 "VALID" 2 "INVALID";

VAL_ 774 VCRIGHT_infoIndex 0 "DEPRECATED_0" 1 "DEPRECATED_1" 2 "DEPRECATED_2" 3 "DEPRECATED_3" 4 "DEPRECATED_4" 5 "DEPRECATED_5" 6 "DEPRECATED_6" 7 "DEPRECATED_7" 8 "DEPRECATED_8" 9 "DEPRECATED_9" 10 "BUILD_HWID_COMPONENTID" 11 "PCBAID_ASSYID_USAGEID" 13 "APP_CRC" 14 "BOOTLOADER_SVN" 15 "BOOTLOADER_CRC" 16 "SUBCOMPONENT1" 17 "APP_GITHASH" 18 "BOOTLOADER_GITHASH" 19 "VERSION_DEPRECATED" 20 "UDS_PROTOCOL_BOOTCRC" 23 "SUBCOMPONENT2" 24 "SUBCOMPONENT3" 31 "SUBCOMPONENT4" 255 "END";
VAL_ 774 VCRIGHT_infoBuildType 0 "UNKNOWN_BUILD" 1 "PLATFORM_BUILD" 2 "LOCAL_BUILD" 3 "TRACEABLE_CI_BUILD" 4 "MFG_BUILD";
VAL_ 774 VCRIGHT_infoAssemblyId 1 "ASSEMBLY1" 255 "ASSEMBLY_SNA";
CM_ BO_ 524 "ESP32-DualCAN Model3_VEH. Seen on this car: 8-byte frames; fit good (bits covered 100%, mux 100%, ranges 100%).";
VAL_ 524 VCRIGHT_hvacPerfTestState 0 "STOPPED" 1 "WAITING" 2 "BLOWING" ;
VAL_ 524 VCRIGHT_tempAmbientRaw 0 "SNA" ;
VAL_ 524 VCRIGHT_tempEvaporatorTarget 255 "SNA" ;
VAL_ 524 VCRIGHT_tempEvaporator 2047 "SNA" ;
CM_ BO_ 579 "ESP32-DualCAN Model3_VEH. Seen on this car: 8-byte frames; fit good (bits covered 100%, mux 100%, ranges 100%).";
VAL_ 579 VCRIGHT_hvacModelInitStatus 0 "NOT_INIT_WAIT_FOR_SENSORS" 1 "NOT_INIT_WAIT_FOR_GTW" 2 "INIT_FROM_SENSORS" 3 "INIT_FROM_SENSORS_PREDICTION_ERROR" 4 "INIT_FORWARD_CALC" 5 "INIT_WAITING_FOR_SENSORS" ;
VAL_ 579 VCRIGHT_hvacDuctTargetRight 255 "SNA" ;
VAL_ 579 VCRIGHT_hvacSecondRowState 0 "AUTO" 1 "OFF" 2 "LOW" 3 "MED" 4 "HIGH" ;
VAL_ 579 VCRIGHT_tempDuctRightLower 255 "SNA" ;
VAL_ 579 VCRIGHT_hvacVentStatus 0 "BOTH" 1 "LEFT" 2 "RIGHT" ;
VAL_ 579 VCRIGHT_hvacPowerState 0 "OFF" 1 "ON" 2 "PRECONDITION" 3 "OVERHEAT_PROTECT_FANONLY" 4 "OVERHEAT_PROTECT" ;
VAL_ 579 VCRIGHT_hvacACRunning 0 "OFF" 1 "ON" ;
VAL_ 579 VCRIGHT_hvacDuctTargetLeft 255 "SNA" ;
VAL_ 579 VCRIGHT_hvacRecirc 0 "AUTO" 1 "RECIRC" 2 "FRESH" ;
VAL_ 579 VCRIGHT_tempDuctLeftLower 255 "SNA" ;
VAL_ 579 VCRIGHT_hvacBlowerSegment 0 "OFF" 1 "1" 2 "2" 3 "3" 4 "4" 5 "5" 6 "6" 7 "7" 8 "8" 9 "9" 10 "10" 11 "11" ;
VAL_ 579 VCRIGHT_hvacAirDistributionMode 0 "NONE" 1 "FLOOR" 2 "PANEL" 3 "PANEL_FLOOR" 4 "DEFROST" 5 "DEFROST_FLOOR" 6 "DEFROST_PANEL" 7 "DEFROST_PANEL_FLOOR" ;
VAL_ 579 VCRIGHT_solarLoadOnVehicle 255 "SNA" ;
VAL_ 579 VCRIGHT_hvacAirflowReason 0 "HVAC_OFF" 1 "MANUAL_FAN_SPEED" 2 "UI_SHORTCUT" 3 "CABIN_TEMPERATURE_CONTROL" 4 "MINIMUM_AUTO_AIRFLOW" 5 "STRATIFICATION_GLASS_ROOF" 6 "STRATIFICATION_INTERIOR_SURFACES" 7 "OCCUPANT_CONVECTION_REQUIREMENT" 8 "COLD_DUCT_LOCKOUT" 9 "CABIN_PURGE" 10 "CABIN_OVERHEAT_PROTECT" 11 "SCREEN_PROTECTION" 12 "EVAP_DRYING" 13 "EVAP_OIL_PURGE" 14 "BIOWEAPON_DEFENSE" 15 "NONE" ;
VAL_ 579 VCRIGHT_tempDuctRight 255 "SNA" ;
VAL_ 579 VCRIGHT_autoDefogStatus 0 "NONE" 1 "DEFOG" 2 "INTERMEDIATE_DEFOG" ;
VAL_ 579 VCRIGHT_hvacEvapInletTempEstimate 1023 "SNA" ;
VAL_ 579 VCRIGHT_hvacFrontLeftSeatHeatStatus 0 "OFF" 1 "LEVEL1" 2 "LEVEL2" 3 "LEVEL3" ;
VAL_ 579 VCRIGHT_tempDuctLeft 255 "SNA" ;
VAL_ 579 VCRIGHT_tempDuctLeftUpper 255 "SNA" ;
VAL_ 579 VCRIGHT_tempDuctRightUpper 255 "SNA" ;
VAL_ 579 VCRIGHT_hvacSeatFrontLeftTempTarget 0 "OFF" ;
VAL_ 579 VCRIGHT_hvacFrontRightSeatHeatStatus 0 "OFF" 1 "LEVEL1" 2 "LEVEL2" 3 "LEVEL3" ;
VAL_ 579 VCRIGHT_hvacStatusIndex 0 "STATUS_UI" 1 "STATUS_VCFRONT" 2 "TARGETS_AND_MASS_FLOW" 3 "TEMPERATURES" 4 "TEMPERATURES_2" 5 "SEAT_CLIMATE" 6 "END" ;
CM_ BO_ 595 "ESP32-DualCAN Model3_VEH. Seen on this car: 8-byte frames; fit ok (bits covered 100%, mux 48%, ranges 100%).";
VAL_ 595 UI_hvacReqActiveVents 0 "BOTH" 1 "LEFT" 2 "RIGHT" ;
VAL_ 595 UI_ventPanelRightLateralMode 0 "SINGLE" 1 "SPLIT" ;
VAL_ 595 UI_ventPanelLeftLateralMode 0 "SINGLE" 1 "SPLIT" ;
VAL_ 595 UI_ventPanelControlRequestIndex 0 "0" 1 "1" ;
CM_ BO_ 609 "ESP32-DualCAN Model3_VEH. Seen on this car: 8-byte frames; fit ok (bits covered 100%, mux 100%, ranges 100%, checksum 0%).";
VAL_ 609 VCFRONT_LVBatteryType 0 "CATL_LI_ION" 1 "UNKNOWN" ;
VAL_ 609 VCFRONT_LVBatteryStatusForDrive 0 "NOT_READY_FOR_DRIVE" 1 "READY_FOR_DRIVE" 2 "EXIT_DRIVE_REQUESTED" ;
VAL_ 609 VCFRONT_IBSVoltage 4095 "SNA" ;
VAL_ 609 VCFRONT_silentWakeIBSCurrent 4095 "SNA" ;
VAL_ 609 VCFRONT_LVBatterySupportRqrdTrigger 0 "NONE" 1 "IBS_FILTERED_VOLTAGE" 2 "PACK_FILTERED_VOLTAGE" 4 "IBS_RAW_VOLTAGE" 8 "PACK_RAW_VOLTAGE" 16 "VBAT_RAW_VOLTAGE" 32 "UNKNOWN_VOLTAGE" 64 "AH_COUNT" 128 "PERIODIC_CHARGE" 256 "POWER_ON_RESET" 512 "EXIT_TRANSPORT_MODE" 1024 "POST_OTA" ;
VAL_ 609 VCFRONT_IBSVoltageRawDBG 4095 "IBS_VOLTAGE_SNA" ;
VAL_ 609 VCFRONT_LVBMS_LVBusVoltageSourceDBG 0 "NONE" 1 "IBS" 2 "VBAT_MONITOR" 3 "LVBMS" ;
VAL_ 609 VCFRONT_IBSTemperature 32767 "IBS_TEMPERATURE_SNA" ;
VAL_ 609 VCFRONT_batterySMState 0 "INIT" 1 "CHARGE" 2 "DISCHARGE" 3 "STANDBY" 4 "RESISTANCE_ESTIMATION" 5 "OTA_STANDBY" 6 "DISCONNECTED_BATTERY_TEST" 7 "SHORTED_CELL_TEST" 8 "FAULT" 9 "RECOVERY" ;
VAL_ 609 VCFRONT_IBSVoltageFiltered 4095 "IBS_VOLTAGE_SNA" ;
VAL_ 609 VCFRONT_voltageProfile 0 "CHARGE" 1 "FLOAT" 2 "REDUCED_FLOAT" 3 "ALWAYS_CLOSED_CONTACTORS" ;
VAL_ 609 VCFRONT_12VBatteryStatusIndex 0 "Mux0" 1 "Mux1" 2 "Mux2" ;
CM_ BO_ 610 "ESP32-DualCAN Model3_VEH. Seen on this car: 8-byte frames; fit good (bits covered 100%, mux 100%, ranges 100%).";
VAL_ 610 VCLEFT_steeringColumnLastRequest 0 "SNA" 1 "NONE" 2 "UP" 3 "DOWN" 4 "IN" 5 "OUT" ;
VAL_ 610 VCLEFT_steeringColumnSMState 0 "SNA" 1 "RECALL" 2 "CALIBRATE" 3 "MANUAL_CONTROL" ;
CM_ BO_ 611 "ESP32-DualCAN Model3_VEH. Seen on this car: 8-byte frames; fit good (bits covered 100%, mux 100%, ranges 100%).";
VAL_ 611 VCRIGHT_hvacIntakeActuatorState 0 "BRAKING" 1 "RUNNING" 2 "COASTING" ;
VAL_ 611 VCRIGHT_hvacLowerModeActState 0 "BRAKING" 1 "RUNNING" 2 "COASTING" ;
VAL_ 611 VCRIGHT_hvacUpperModeActState 0 "BRAKING" 1 "RUNNING" 2 "COASTING" ;
VAL_ 611 VCRIGHT_hvacRHVaneActuatorState 0 "BRAKING" 1 "RUNNING" 2 "COASTING" ;
VAL_ 611 VCRIGHT_hvacLHVaneActuatorState 0 "BRAKING" 1 "RUNNING" 2 "COASTING" ;
VAL_ 611 VCRIGHT_hvacRHBleedActuatorState 0 "BRAKING" 1 "RUNNING" 2 "COASTING" ;
VAL_ 611 VCRIGHT_hvacLHBleedActuatorState 0 "BRAKING" 1 "RUNNING" 2 "COASTING" ;
VAL_ 611 VCRIGHT_logging10HzIndex 0 "HVAC_ACTUATOR_TARGETS_1" 1 "HVAC_ACTUATOR_TARGETS_2" 2 "HVAC_ACTUATOR_POSITIONS_1" 3 "HVAC_ACTUATOR_POSITIONS_2" 4 "END" ;
CM_ BO_ 644 "ESP32-DualCAN Model3_VEH. Seen on this car: 8-byte frames; fit good (bits covered 100%, mux 100%, ranges 100%, checksum 100%).";
VAL_ 644 UI_closureEasterEggStatus 0 "IDLE" 1 "REQ_RECD_WAITING_STANDARD" 2 "REQ_RECD_WAITING_DYNAMIC" 3 "PLAYING" ;
VAL_ 644 UI_serviceModePlus 0 "DISABLED" 1 "ENABLED" ;
VAL_ 644 UI_diagnosticsAllowed 0 "NOT_ALLOWED" 1 "ALLOWED" ;
VAL_ 644 UI_serviceMode 0 "DISABLED" 1 "ENABLED" ;
VAL_ 644 UI_showroomMode 0 "DISABLED" 1 "ENABLED" ;
VAL_ 644 UI_transportMode 0 "DISABLED" 1 "ENABLED" ;
VAL_ 644 UI_factoryMode 0 "DISABLED" 1 "ENABLED" ;
CM_ BO_ 721 "ESP32-DualCAN Model3_VEH. Seen on this car: 2-byte frames; fit poor (bits covered 0%, mux 100%, ranges 100%).";
CM_ BO_ 769 "ESP32-DualCAN Model3_VEH. Seen on this car: 8-byte frames; fit good (bits covered 100%, mux 100%, ranges 100%).";
VAL_ 769 VCFRONT_infoAssemblyId 1 "ASSEMBLY1" 255 "ASSEMBLY_SNA" ;
VAL_ 769 VCFRONT_infoBuildType 0 "UNKNOWN_BUILD" 1 "PLATFORM_BUILD" 2 "LOCAL_BUILD" 3 "TRACEABLE_CI_BUILD" 4 "MFG_BUILD" ;
VAL_ 769 VCFRONT_infoIndex 0 "DEPRECATED_0" 1 "DEPRECATED_1" 2 "DEPRECATED_2" 3 "DEPRECATED_3" 4 "DEPRECATED_4" 5 "DEPRECATED_5" 6 "DEPRECATED_6" 7 "DEPRECATED_7" 8 "DEPRECATED_8" 9 "DEPRECATED_9" 10 "BUILD_HWID_COMPONENTID" 11 "PCBAID_ASSYID_USAGEID" 13 "APP_CRC" 14 "BOOTLOADER_SVN" 15 "BOOTLOADER_CRC" 16 "SUBCOMPONENT1" 17 "APP_GITHASH" 18 "BOOTLOADER_GITHASH" 19 "VERSION_DEPRECATED" 20 "UDS_PROTOCOL_BOOTCRC" 23 "SUBCOMPONENT2" 24 "SUBCOMPONENT3" 31 "SUBCOMPONENT4" 32 "SUBCOMPONENT5" 33 "SUBCOMPONENT6" 34 "SUBCOMPONENT7" 35 "SUBCOMPONENT8" 36 "SUBCOMPONENT9" 37 "SUBCOMPONENT10" 38 "SUBCOMPONENT11" 39 "SUBCOMPONENT12" 40 "SUBCOMPONENT13" 41 "SUBCOMPONENT14" 255 "END" ;
CM_ BO_ 770 "ESP32-DualCAN Model3_VEH. Seen on this car: 8-byte frames; fit good (bits covered 100%, mux 71%, ranges 100%).";
VAL_ 770 VCLEFT_infoAssemblyId 1 "ASSEMBLY1" 255 "ASSEMBLY_SNA" ;
VAL_ 770 VCLEFT_infoBuildType 0 "UNKNOWN_BUILD" 1 "PLATFORM_BUILD" 2 "LOCAL_BUILD" 3 "TRACEABLE_CI_BUILD" 4 "MFG_BUILD" ;
VAL_ 770 VCLEFT_infoIndex 0 "DEPRECATED_0" 1 "DEPRECATED_1" 2 "DEPRECATED_2" 3 "DEPRECATED_3" 4 "DEPRECATED_4" 5 "DEPRECATED_5" 6 "DEPRECATED_6" 7 "DEPRECATED_7" 8 "DEPRECATED_8" 9 "DEPRECATED_9" 10 "BUILD_HWID_COMPONENTID" 11 "PCBAID_ASSYID_USAGEID" 13 "APP_CRC" 14 "BOOTLOADER_SVN" 15 "BOOTLOADER_CRC" 16 "SUBCOMPONENT1" 17 "APP_GITHASH" 18 "BOOTLOADER_GITHASH" 19 "VERSION_DEPRECATED" 20 "UDS_PROTOCOL_BOOTCRC" 23 "SUBCOMPONENT2" 24 "SUBCOMPONENT3" 31 "SUBCOMPONENT4" 32 "SUBCOMPONENT5" 33 "SUBCOMPONENT6" 34 "SUBCOMPONENT7" 35 "SUBCOMPONENT8" 36 "SUBCOMPONENT9" 37 "SUBCOMPONENT10" 38 "SUBCOMPONENT11" 39 "SUBCOMPONENT12" 40 "SUBCOMPONENT13" 41 "SUBCOMPONENT14" 255 "END" ;
CM_ BO_ 801 "ESP32-DualCAN Model3_VEH. Seen on this car: 8-byte frames; fit good (bits covered 100%, mux 100%, ranges 100%, checksum 100%).";
VAL_ 801 VCFRONT_tempAmbientFiltered 0 "SNA" ;
VAL_ 801 VCFRONT_washerFluidLevel 0 "SNA" 1 "LOW" 2 "NORMAL" ;
VAL_ 801 VCFRONT_tempAmbient 0 "SNA" ;
VAL_ 801 VCFRONT_brakeFluidLevel 0 "SNA" 1 "LOW" 2 "NORMAL" ;
VAL_ 801 VCFRONT_coolantLevel 0 "NOT_OK" 1 "FILLED" ;
VAL_ 801 VCFRONT_tempCoolantPTInlet 2047 "SNA" ;
VAL_ 801 VCFRONT_tempCoolantBatInlet 1023 "SNA" ;
CM_ BO_ 929 "ESP32-DualCAN Model3_VEH. Seen on this car: 8-byte frames; fit good (bits covered 100%, mux 100%, ranges 100%, checksum 100%).";
VAL_ 929 VCFRONT_pcsEFuseVoltage 1023 "SNA" ;
VAL_ 929 VCFRONT_2RowRightUnbuckled 0 "NONE" 1 "OCCUPIED_AND_UNBUCKLED" 2 "SNA" ;
VAL_ 929 VCFRONT_2RowCenterUnbuckled 0 "NONE" 1 "OCCUPIED_AND_UNBUCKLED" 2 "SNA" ;
VAL_ 929 VCFRONT_2RowLeftUnbuckled 0 "NONE" 1 "OCCUPIED_AND_UNBUCKLED" 2 "SNA" ;
VAL_ 929 VCFRONT_passengerUnbuckled 0 "NONE" 1 "OCCUPIED_AND_UNBUCKLED" 2 "SNA" ;
VAL_ 929 VCFRONT_driverUnbuckled 0 "NONE" 1 "OCCUPIED_AND_UNBUCKLED" 2 "SNA" ;
VAL_ 929 VCFRONT_driverDoorStatus 0 "OPEN" 1 "CLOSED" ;
VAL_ 929 VCFRONT_driverBuckleStatus 0 "UNBUCKLED" 1 "BUCKLED" ;
VAL_ 929 VCFRONT_12vStatusForDrive 0 "NOT_READY_FOR_DRIVE_12V" 1 "READY_FOR_DRIVE_12V" 2 "EXIT_DRIVE_REQUESTED_12V" ;
VAL_ 929 VCFRONT_diPowerOnState 0 "POWERED_OFF" 1 "POWERED_ON_FOR_SUMMON" 2 "POWERED_ON_FOR_STATIONARY_HEAT" 3 "POWERED_ON_FOR_DRIVE" 4 "POWER_GOING_DOWN" 5 "POWERED_ON_FOR_WINCH" ;
VAL_ 929 VCFRONT_thermalSystemType 0 "LEGACY_THERMAL_SYSTEM" 1 "HEAT_PUMP_THERMAL_SYSTEM" ;
VAL_ 929 VCFRONT_3RowRightUnbuckled 0 "NONE" 1 "OCCUPIED_AND_UNBUCKLED" 2 "SNA" ;
VAL_ 929 VCFRONT_3RowLeftUnbuckled 0 "NONE" 1 "OCCUPIED_AND_UNBUCKLED" 2 "SNA" ;
VAL_ 929 VCFRONT_APGlassHeaterState 0 "SNA" 1 "ON" 2 "OFF" 3 "OFF_UNAVAILABLE" 4 "FAULT" ;
VAL_ 929 VCFRONT_vehicleStatusMuxIndex 0 "MUX0" 1 "MUX1" ;
CM_ BO_ 947 "ESP32-DualCAN Model3_VEH. Seen on this car: 8-byte frames; fit good (bits covered 100%, mux 100%, ranges 100%). read by the app or firmware.";
VAL_ 947 UI_dcr12VThreshold 0 "OFF" 1 "40_MILLIOHMS" 2 "35_MILLIOHMS" 3 "30_MILLIOHMS" 4 "27_MILLIOHMS" 5 "24_MILLIOHMS" 6 "22_MILLIOHMS" 7 "20_MILLIOHMS" ;
VAL_ 947 UI_shorted12VCellTestMode 0 "DISABLED" 1 "SHADOW" 2 "ACTIVE" ;
VAL_ 947 UI_autopilotPowerStateRequest 0 "NOMINAL" 1 "SENTRY" 2 "SUSPEND" ;
VAL_ 947 UI_summonState 0 "SNA" 1 "IDLE" 2 "PRE_PRIMED" 3 "ACTIVE" ;
VAL_ 947 UI_lightSwitch 0 "AUTO" 1 "ON" 2 "PARKING" 3 "OFF" 4 "SNA" ;
VAL_ 947 UI_trunkRequest 0 "NONE" 1 "MOVE" 2 "STOP" 3 "SNA" ;
CM_ BO_ 952 "ESP32-DualCAN Model3_CH. Seen on this car: 4-byte frames; fit poor (bits covered 0%, mux 100%, ranges 100%).";
CM_ BO_ 991 "ESP32-DualCAN Model3_VEH. Seen on this car: 8-byte frames; fit good (bits covered 100%, mux 100%, ranges 100%). read by the app or firmware.";
VAL_ 991 UI_sentryModeState 0 "OFF" 1 "IDLE" 2 "ARMED" 3 "AWARE" 4 "PANIC" 5 "QUIET" 6 "SNA" ;
VAL_ 991 UI_linkState 0 "NONE" 1 "CELL" 2 "WIFI" ;
CM_ BO_ 995 "ESP32-DualCAN Model3_VEH. Seen on this car: 5-byte frames; fit ok (bits covered 100%, mux 100%, ranges 100%). read by the app or firmware.";
VAL_ 995 VCRIGHT_rearFogLightStatus 0 "OFF" 1 "ON" 2 "FAULT" 3 "SNA" ;
VAL_ 995 VCRIGHT_reverseLightStatus 0 "OFF" 1 "ON" 2 "FAULT" 3 "SNA" ;
VAL_ 995 VCRIGHT_turnSignalStatus 0 "OFF" 1 "ON" 2 "FAULT" 3 "SNA" ;
VAL_ 995 VCRIGHT_tailLightStatus 0 "OFF" 1 "ON" 2 "FAULT" 3 "SNA" ;
VAL_ 995 VCRIGHT_brakeLightStatus 0 "OFF" 1 "ON" 2 "FAULT" 3 "SNA" ;
CM_ BO_ 1064 "ESP32-DualCAN Model3_VEH. Seen on this car: 7-byte frames; fit ok (bits covered 100%, mux 100%, ranges 100%).";
VAL_ 1064 EPBL_nmDebugWakeUp 2147483648 "31" 1073741824 "30" 536870912 "29" 268435456 "28" 134217728 "27" 67108864 "26" 33554432 "25" 16777216 "24" 0 "NONE" 256 "8" 512 "9" 1024 "10" 2048 "11" 4096 "12" 8192 "13" 16384 "14" 32768 "15" 1 "0" 65536 "16" 2 "1" 131072 "17" 4 "2" 262144 "18" 8 "3" 524288 "19" 16 "4" 1048576 "20" 32 "5" 2097152 "21" 64 "6" 4194304 "22" 128 "7" 8388608 "23" ;
VAL_ 1064 EPBL_nmWakeUpReason 0 "NONE" 1 "CAN_VEH" 2 "CAN_HVS" 3 "WANTTOCHARGE" 4 "CRITICALALERT" 5 "WANTTOWARM" ;
VAL_ 1064 EPBL_nmKeepAwakeReason 0 "NONE_SNA" 1 "CTRS_CLOSED" 2 "CRITICAL_ALERT" 3 "FC_CTR_CLEANING" 4 "HVP_ACTIVE" 5 "BMS_ACTIVE" 6 "CP_ACTIVE" ;
CM_ BO_ 1250 "ESP32-DualCAN Model3_VEH. Seen on this car: 8-byte frames; fit good (bits covered 100%, mux 100%, ranges 100%).";
VAL_ 1250 VCLEFT_frontSeatBackState 0 "STOPPED" 1 "MOVING_UP" 2 "MOVING_DOWN" 3 "RECALLING" 4 "CALIBRATING" 5 "UNDEFINED" ;
VAL_ 1250 VCLEFT_frontSeatLiftState 0 "STOPPED" 1 "MOVING_UP" 2 "MOVING_DOWN" 3 "RECALLING" 4 "CALIBRATING" 5 "UNDEFINED" ;
VAL_ 1250 VCLEFT_frontSeatTiltState 0 "STOPPED" 1 "MOVING_UP" 2 "MOVING_DOWN" 3 "RECALLING" 4 "CALIBRATING" 5 "UNDEFINED" ;
VAL_ 1250 VCLEFT_frontSeatTrackState 0 "STOPPED" 1 "MOVING_UP" 2 "MOVING_DOWN" 3 "RECALLING" 4 "CALIBRATING" 5 "UNDEFINED" ;
VAL_ 1250 VCLEFT_lumbarBState 0 "STOPPED" 1 "MOVING_UP" 2 "MOVING_DOWN" 3 "RECALLING" 4 "CALIBRATING" 5 "UNDEFINED" ;
VAL_ 1250 VCLEFT_lumbarAState 0 "STOPPED" 1 "MOVING_UP" 2 "MOVING_DOWN" 3 "RECALLING" 4 "CALIBRATING" 5 "UNDEFINED" ;
VAL_ 1250 VCLEFT_seatStatusIndex 0 "TRACK" 1 "BACK" 2 "LIFT" 3 "TILT" 4 "LUMBAR" 5 "POSITION" ;
